[part 1 of 2: packages /MICROSAR/Dem_swc/DataTypes to /MICROSAR/Dem_swc/ComponentTypes]
AUTOSAR XML (schema 4-2-1)
package /MICROSAR/Dem_swc/DataTypes
  23 x impl type:
    Dem_EventIdType: range raw 1..65535, implementation-data-type=uint16
    Dem_RatioIdType: range raw 1..65535, implementation-data-type=uint16
    Dem_DTCStatusMaskType: range raw 0..255, implementation-data-type=uint8
    Dem_OperationCycleIdType: range raw 0..255, implementation-data-type=uint8
    Dem_DTCGroupType: range raw 0..16777215, implementation-data-type=uint32
    Dem_MaxDataValueType: category=ARRAY, sw-calibration-access=READ-ONLY
      element Dem_MaxDataValueTypeElement: array-size=2, array-size-semantics=FIXED-SIZE, implementation-data-type=uint8
    Dem_EventStatusType:
      compu {0=DEM_EVENT_STATUS_PASSED, 1=DEM_EVENT_STATUS_FAILED, 2=DEM_EVENT_STATUS_PREPASSED, 3=DEM_EVENT_STATUS_PREFAILED, 4=DEM_EVENT_STATUS_FDC_THRESHOLD_REACHED, 5=DEM_EVENT_STATUS_PASSED_CONDITIONS_NOT_FULFILLED, 6=DEM_EVENT_STATUS_FAILED_CONDITIONS_NOT_FULFILLED, 7=DEM_EVENT_STATUS_PREPASSED_CONDITIONS_NOT_FULFILLED, 8=DEM_EVENT_STATUS_PREFAILED_CONDITIONS_NOT_FULFILLED}
      range raw 0..255
      implementation-data-type=uint8
    Dem_InitMonitorReasonType: compu {1=DEM_INIT_MONITOR_CLEAR, 2=DEM_INIT_MONITOR_RESTART, 3=DEM_INIT_MONITOR_REENABLED, 4=DEM_INIT_MONITOR_STORAGE_REENABLED}, range raw 0..255, implementation-data-type=uint8
    Dem_DTCOriginType:
      compu {1=DEM_DTC_ORIGIN_PRIMARY_MEMORY, 2=DEM_DTC_ORIGIN_MIRROR_MEMORY, 3=DEM_DTC_ORIGIN_PERMANENT_MEMORY, 4=DEM_DTC_ORIGIN_OBD_RELEVANT_MEMORY, 5=DEM_DTC_ORIGIN_SECONDARY_MEMORY, 5=DEM_DTC_ORIGIN_USERDEFINED_MEMORY_10, 5=DEM_DTC_ORIGIN_USERDEFINED_MEMORY_11, 5=DEM_DTC_ORIGIN_USERDEFINED_MEMORY_12, 5=DEM_DTC_ORIGIN_USERDEFINED_MEMORY_13, 5=DEM_DTC_ORIGIN_USERDEFINED_MEMORY_14, 5=DEM_DTC_ORIGIN_USERDEFINED_MEMORY_15, 5=DEM_DTC_ORIGIN_USERDEFINED_MEMORY_16, 5=DEM_DTC_ORIGIN_USERDEFINED_MEMORY_17, 5=DEM_DTC_ORIGIN_USERDEFINED_MEMORY_18, 5=DEM_DTC_ORIGIN_USERDEFINED_MEMORY_19, 5=DEM_DTC_ORIGIN_USERDEFINED_MEMORY_1A, 5=DEM_DTC_ORIGIN_USERDEFINED_MEMORY_1B, 5=DEM_DTC_ORIGIN_USERDEFINED_MEMORY_1C, 5=DEM_DTC_ORIGIN_USERDEFINED_MEMORY_1D, 5=DEM_DTC_ORIGIN_USERDEFINED_MEMORY_1E, 5=DEM_DTC_ORIGIN_USERDEFINED_MEMORY_1F, 5=DEM_DTC_ORIGIN_USERDEFINED_MEMORY_20, 5=DEM_DTC_ORIGIN_USERDEFINED_MEMORY_21, 5=DEM_DTC_ORIGIN_USERDEFINED_MEMORY_22, 5=DEM_DTC_ORIGIN_USERDEFINED_MEMORY_23, 5=DEM_DTC_ORIGIN_USERDEFINED_MEMORY_24, 5=DEM_DTC_ORIGIN_USERDEFINED_MEMORY_25, 5=DEM_DTC_ORIGIN_USERDEFINED_MEMORY_26, 5=DEM_DTC_ORIGIN_USERDEFINED_MEMORY_27, 5=DEM_DTC_ORIGIN_USERDEFINED_MEMORY_28, 5=DEM_DTC_ORIGIN_USERDEFINED_MEMORY_29, 5=DEM_DTC_ORIGIN_USERDEFINED_MEMORY_2A, 5=DEM_DTC_ORIGIN_USERDEFINED_MEMORY_2B, 5=DEM_DTC_ORIGIN_USERDEFINED_MEMORY_2C, 5=DEM_DTC_ORIGIN_USERDEFINED_MEMORY_2D, 5=DEM_DTC_ORIGIN_USERDEFINED_MEMORY_2E, 5=DEM_DTC_ORIGIN_USERDEFINED_MEMORY_2F, 5=DEM_DTC_ORIGIN_USERDEFINED_MEMORY_30, 5=DEM_DTC_ORIGIN_USERDEFINED_MEMORY_31, 5=DEM_DTC_ORIGIN_USERDEFINED_MEMORY_32, 5=DEM_DTC_ORIGIN_USERDEFINED_MEMORY_33, 5=DEM_DTC_ORIGIN_USERDEFINED_MEMORY_34, 5=DEM_DTC_ORIGIN_USERDEFINED_MEMORY_35, 5=DEM_DTC_ORIGIN_USERDEFINED_MEMORY_36, 5=DEM_DTC_ORIGIN_USERDEFINED_MEMORY_37, 5=DEM_DTC_ORIGIN_USERDEFINED_MEMORY_38, 5=DEM_DTC_ORIGIN_USERDEFINED_MEMORY_39, 5=DEM_DTC_ORIGIN_USERDEFINED_MEMORY_3A, 5=DEM_DTC_ORIGIN_USERDEFINED_MEMORY_3B, 5=DEM_DTC_ORIGIN_USERDEFINED_MEMORY_3C, 5=DEM_DTC_ORIGIN_USERDEFINED_MEMORY_3D, 5=DEM_DTC_ORIGIN_USERDEFINED_MEMORY_3E, 5=DEM_DTC_ORIGIN_USERDEFINED_MEMORY_3F, 5=DEM_DTC_ORIGIN_USERDEFINED_MEMORY_40, 5=DEM_DTC_ORIGIN_USERDEFINED_MEMORY_41, 5=DEM_DTC_ORIGIN_USERDEFINED_MEMORY_42, 5=DEM_DTC_ORIGIN_USERDEFINED_MEMORY_43, 5=DEM_DTC_ORIGIN_USERDEFINED_MEMORY_44, 5=DEM_DTC_ORIGIN_USERDEFINED_MEMORY_45, 5=DEM_DTC_ORIGIN_USERDEFINED_MEMORY_46, 5=DEM_DTC_ORIGIN_USERDEFINED_MEMORY_47, 5=DEM_DTC_ORIGIN_USERDEFINED_MEMORY_48, 5=DEM_DTC_ORIGIN_USERDEFINED_MEMORY_49, 5=DEM_DTC_ORIGIN_USERDEFINED_MEMORY_4A, 5=DEM_DTC_ORIGIN_USERDEFINED_MEMORY_4B, 5=DEM_DTC_ORIGIN_USERDEFINED_MEMORY_4C, 5=DEM_DTC_ORIGIN_USERDEFINED_MEMORY_4D, 5=DEM_DTC_ORIGIN_USERDEFINED_MEMORY_4E, 5=DEM_DTC_ORIGIN_USERDEFINED_MEMORY_4F, 5=DEM_DTC_ORIGIN_USERDEFINED_MEMORY_50, 5=DEM_DTC_ORIGIN_USERDEFINED_MEMORY_51, 5=DEM_DTC_ORIGIN_USERDEFINED_MEMORY_52, 5=DEM_DTC_ORIGIN_USERDEFINED_MEMORY_53, 5=DEM_DTC_ORIGIN_USERDEFINED_MEMORY_54, 5=DEM_DTC_ORIGIN_USERDEFINED_MEMORY_55, 5=DEM_DTC_ORIGIN_USERDEFINED_MEMORY_56, 5=DEM_DTC_ORIGIN_USERDEFINED_MEMORY_57, 5=DEM_DTC_ORIGIN_USERDEFINED_MEMORY_58, 5=DEM_DTC_ORIGIN_USERDEFINED_MEMORY_59, 5=DEM_DTC_ORIGIN_USERDEFINED_MEMORY_5A, 5=DEM_DTC_ORIGIN_USERDEFINED_MEMORY_5B, 5=DEM_DTC_ORIGIN_USERDEFINED_MEMORY_5C, 5=DEM_DTC_ORIGIN_USERDEFINED_MEMORY_5D, 5=DEM_DTC_ORIGIN_USERDEFINED_MEMORY_5E, 5=DEM_DTC_ORIGIN_USERDEFINED_MEMORY_5F, 5=DEM_DTC_ORIGIN_USERDEFINED_MEMORY_60, 5=DEM_DTC_ORIGIN_USERDEFINED_MEMORY_61, 5=DEM_DTC_ORIGIN_USERDEFINED_MEMORY_62, 5=DEM_DTC_ORIGIN_USERDEFINED_MEMORY_63, 5=DEM_DTC_ORIGIN_USERDEFINED_MEMORY_64, 5=DEM_DTC_ORIGIN_USERDEFINED_MEMORY_65, 5=DEM_DTC_ORIGIN_USERDEFINED_MEMORY_66, 5=DEM_DTC_ORIGIN_USERDEFINED_MEMORY_67, 5=DEM_DTC_ORIGIN_USERDEFINED_MEMORY_68, 5=DEM_DTC_ORIGIN_USERDEFINED_MEMORY_69, 5=DEM_DTC_ORIGIN_USERDEFINED_MEMORY_6A, 5=DEM_DTC_ORIGIN_USERDEFINED_MEMORY_6B, 5=DEM_DTC_ORIGIN_USERDEFINED_MEMORY_6C, 5=DEM_DTC_ORIGIN_USERDEFINED_MEMORY_6D, 5=DEM_DTC_ORIGIN_USERDEFINED_MEMORY_6E, 5=DEM_DTC_ORIGIN_USERDEFINED_MEMORY_6F, 5=DEM_DTC_ORIGIN_USERDEFINED_MEMORY_70, 5=DEM_DTC_ORIGIN_USERDEFINED_MEMORY_71, 5=DEM_DTC_ORIGIN_USERDEFINED_MEMORY_72, 5=DEM_DTC_ORIGIN_USERDEFINED_MEMORY_73, 5=DEM_DTC_ORIGIN_USERDEFINED_MEMORY_74, 5=DEM_DTC_ORIGIN_USERDEFINED_MEMORY_75, 5=DEM_DTC_ORIGIN_USERDEFINED_MEMORY_76, 5=DEM_DTC_ORIGIN_USERDEFINED_MEMORY_77, 5=DEM_DTC_ORIGIN_USERDEFINED_MEMORY_78, 5=DEM_DTC_ORIGIN_USERDEFINED_MEMORY_79, 5=DEM_DTC_ORIGIN_USERDEFINED_MEMORY_7A, 5=DEM_DTC_ORIGIN_USERDEFINED_MEMORY_7B, 5=DEM_DTC_ORIGIN_USERDEFINED_MEMORY_7C, 5=DEM_DTC_ORIGIN_USERDEFINED_MEMORY_7D, 5=DEM_DTC_ORIGIN_USERDEFINED_MEMORY_7E, 5=DEM_DTC_ORIGIN_USERDEFINED_MEMORY_7F, 5=DEM_DTC_ORIGIN_USERDEFINED_MEMORY_80, 5=DEM_DTC_ORIGIN_USERDEFINED_MEMORY_81, 5=DEM_DTC_ORIGIN_USERDEFINED_MEMORY_82, 5=DEM_DTC_ORIGIN_USERDEFINED_MEMORY_83, 5=DEM_DTC_ORIGIN_USERDEFINED_MEMORY_84, 5=DEM_DTC_ORIGIN_USERDEFINED_MEMORY_85, 5=DEM_DTC_ORIGIN_USERDEFINED_MEMORY_86, 5=DEM_DTC_ORIGIN_USERDEFINED_MEMORY_87, 5=DEM_DTC_ORIGIN_USERDEFINED_MEMORY_88, 5=DEM_DTC_ORIGIN_USERDEFINED_MEMORY_89, 5=DEM_DTC_ORIGIN_USERDEFINED_MEMORY_8A, 5=DEM_DTC_ORIGIN_USERDEFINED_MEMORY_8B, 5=DEM_DTC_ORIGIN_USERDEFINED_MEMORY_8C, 5=DEM_DTC_ORIGIN_USERDEFINED_MEMORY_8D, 5=DEM_DTC_ORIGIN_USERDEFINED_MEMORY_8E, 5=DEM_DTC_ORIGIN_USERDEFINED_MEMORY_8F, 5=DEM_DTC_ORIGIN_USERDEFINED_MEMORY_90, 5=DEM_DTC_ORIGIN_USERDEFINED_MEMORY_91, 5=DEM_DTC_ORIGIN_USERDEFINED_MEMORY_92, 5=DEM_DTC_ORIGIN_USERDEFINED_MEMORY_93, 5=DEM_DTC_ORIGIN_USERDEFINED_MEMORY_94, 5=DEM_DTC_ORIGIN_USERDEFINED_MEMORY_95, 5=DEM_DTC_ORIGIN_USERDEFINED_MEMORY_96, 5=DEM_DTC_ORIGIN_USERDEFINED_MEMORY_97, 5=DEM_DTC_ORIGIN_USERDEFINED_MEMORY_98, 5=DEM_DTC_ORIGIN_USERDEFINED_MEMORY_99, 5=DEM_DTC_ORIGIN_USERDEFINED_MEMORY_9A, 5=DEM_DTC_ORIGIN_USERDEFINED_MEMORY_9B, 5=DEM_DTC_ORIGIN_USERDEFINED_MEMORY_9C, 5=DEM_DTC_ORIGIN_USERDEFINED_MEMORY_9D, 5=DEM_DTC_ORIGIN_USERDEFINED_MEMORY_9E, 5=DEM_DTC_ORIGIN_USERDEFINED_MEMORY_9F, 5=DEM_DTC_ORIGIN_USERDEFINED_MEMORY_A0, 5=DEM_DTC_ORIGIN_USERDEFINED_MEMORY_A1, 5=DEM_DTC_ORIGIN_USERDEFINED_MEMORY_A2, 5=DEM_DTC_ORIGIN_USERDEFINED_MEMORY_A3, 5=DEM_DTC_ORIGIN_USERDEFINED_MEMORY_A4, 5=DEM_DTC_ORIGIN_USERDEFINED_MEMORY_A5, 5=DEM_DTC_ORIGIN_USERDEFINED_MEMORY_A6, 5=DEM_DTC_ORIGIN_USERDEFINED_MEMORY_A7, 5=DEM_DTC_ORIGIN_USERDEFINED_MEMORY_A8, 5=DEM_DTC_ORIGIN_USERDEFINED_MEMORY_A9, 5=DEM_DTC_ORIGIN_USERDEFINED_MEMORY_AA, 5=DEM_DTC_ORIGIN_USERDEFINED_MEMORY_AB, 5=DEM_DTC_ORIGIN_USERDEFINED_MEMORY_AC, 5=DEM_DTC_ORIGIN_USERDEFINED_MEMORY_AD, 5=DEM_DTC_ORIGIN_USERDEFINED_MEMORY_AE, 5=DEM_DTC_ORIGIN_USERDEFINED_MEMORY_AF, 5=DEM_DTC_ORIGIN_USERDEFINED_MEMORY_B0, 5=DEM_DTC_ORIGIN_USERDEFINED_MEMORY_B1, 5=DEM_DTC_ORIGIN_USERDEFINED_MEMORY_B2, 5=DEM_DTC_ORIGIN_USERDEFINED_MEMORY_B3, 5=DEM_DTC_ORIGIN_USERDEFINED_MEMORY_B4, 5=DEM_DTC_ORIGIN_USERDEFINED_MEMORY_B5, 5=DEM_DTC_ORIGIN_USERDEFINED_MEMORY_B6, 5=DEM_DTC_ORIGIN_USERDEFINED_MEMORY_B7, 5=DEM_DTC_ORIGIN_USERDEFINED_MEMORY_B8, 5=DEM_DTC_ORIGIN_USERDEFINED_MEMORY_B9, 5=DEM_DTC_ORIGIN_USERDEFINED_MEMORY_BA, 5=DEM_DTC_ORIGIN_USERDEFINED_MEMORY_BB, 5=DEM_DTC_ORIGIN_USERDEFINED_MEMORY_BC, 5=DEM_DTC_ORIGIN_USERDEFINED_MEMORY_BD, 5=DEM_DTC_ORIGIN_USERDEFINED_MEMORY_BE, 5=DEM_DTC_ORIGIN_USERDEFINED_MEMORY_BF, 5=DEM_DTC_ORIGIN_USERDEFINED_MEMORY_C0, 5=DEM_DTC_ORIGIN_USERDEFINED_MEMORY_C1, 5=DEM_DTC_ORIGIN_USERDEFINED_MEMORY_C2, 5=DEM_DTC_ORIGIN_USERDEFINED_MEMORY_C3, 5=DEM_DTC_ORIGIN_USERDEFINED_MEMORY_C4, 5=DEM_DTC_ORIGIN_USERDEFINED_MEMORY_C5, 5=DEM_DTC_ORIGIN_USERDEFINED_MEMORY_C6, 5=DEM_DTC_ORIGIN_USERDEFINED_MEMORY_C7, 5=DEM_DTC_ORIGIN_USERDEFINED_MEMORY_C8, 5=DEM_DTC_ORIGIN_USERDEFINED_MEMORY_C9, 5=DEM_DTC_ORIGIN_USERDEFINED_MEMORY_CA, 5=DEM_DTC_ORIGIN_USERDEFINED_MEMORY_CB, 5=DEM_DTC_ORIGIN_USERDEFINED_MEMORY_CC, 5=DEM_DTC_ORIGIN_USERDEFINED_MEMORY_CD, 5=DEM_DTC_ORIGIN_USERDEFINED_MEMORY_CE, 5=DEM_DTC_ORIGIN_USERDEFINED_MEMORY_CF, 5=DEM_DTC_ORIGIN_USERDEFINED_MEMORY_D0, 5=DEM_DTC_ORIGIN_USERDEFINED_MEMORY_D1, 5=DEM_DTC_ORIGIN_USERDEFINED_MEMORY_D2, 5=DEM_DTC_ORIGIN_USERDEFINED_MEMORY_D3, 5=DEM_DTC_ORIGIN_USERDEFINED_MEMORY_D4, 5=DEM_DTC_ORIGIN_USERDEFINED_MEMORY_D5, 5=DEM_DTC_ORIGIN_USERDEFINED_MEMORY_D6, 5=DEM_DTC_ORIGIN_USERDEFINED_MEMORY_D7, 5=DEM_DTC_ORIGIN_USERDEFINED_MEMORY_D8, 5=DEM_DTC_ORIGIN_USERDEFINED_MEMORY_D9, 5=DEM_DTC_ORIGIN_USERDEFINED_MEMORY_DA, 5=DEM_DTC_ORIGIN_USERDEFINED_MEMORY_DB, 5=DEM_DTC_ORIGIN_USERDEFINED_MEMORY_DC, 5=DEM_DTC_ORIGIN_USERDEFINED_MEMORY_DD, 5=DEM_DTC_ORIGIN_USERDEFINED_MEMORY_DE, 5=DEM_DTC_ORIGIN_USERDEFINED_MEMORY_DF, 5=DEM_DTC_ORIGIN_USERDEFINED_MEMORY_E0, 5=DEM_DTC_ORIGIN_USERDEFINED_MEMORY_E1, 5=DEM_DTC_ORIGIN_USERDEFINED_MEMORY_E2, 5=DEM_DTC_ORIGIN_USERDEFINED_MEMORY_E3, 5=DEM_DTC_ORIGIN_USERDEFINED_MEMORY_E4, 5=DEM_DTC_ORIGIN_USERDEFINED_MEMORY_E5, 5=DEM_DTC_ORIGIN_USERDEFINED_MEMORY_E6, 5=DEM_DTC_ORIGIN_USERDEFINED_MEMORY_E7, 5=DEM_DTC_ORIGIN_USERDEFINED_MEMORY_E8, 5=DEM_DTC_ORIGIN_USERDEFINED_MEMORY_E9, 5=DEM_DTC_ORIGIN_USERDEFINED_MEMORY_EA, 5=DEM_DTC_ORIGIN_USERDEFINED_MEMORY_EB, 5=DEM_DTC_ORIGIN_USERDEFINED_MEMORY_EC, 5=DEM_DTC_ORIGIN_USERDEFINED_MEMORY_ED, 5=DEM_DTC_ORIGIN_USERDEFINED_MEMORY_EE, 5=DEM_DTC_ORIGIN_USERDEFINED_MEMORY_EF, 5=DEM_DTC_ORIGIN_USERDEFINED_MEMORY_F0, 5=DEM_DTC_ORIGIN_USERDEFINED_MEMORY_F1, 5=DEM_DTC_ORIGIN_USERDEFINED_MEMORY_F2, 5=DEM_DTC_ORIGIN_USERDEFINED_MEMORY_F3, 5=DEM_DTC_ORIGIN_USERDEFINED_MEMORY_F4, 5=DEM_DTC_ORIGIN_USERDEFINED_MEMORY_F5, 5=DEM_DTC_ORIGIN_USERDEFINED_MEMORY_F6, 5=DEM_DTC_ORIGIN_USERDEFINED_MEMORY_F7, 5=DEM_DTC_ORIGIN_USERDEFINED_MEMORY_F8, 5=DEM_DTC_ORIGIN_USERDEFINED_MEMORY_F9, 5=DEM_DTC_ORIGIN_USERDEFINED_MEMORY_FA, 5=DEM_DTC_ORIGIN_USERDEFINED_MEMORY_FB, 5=DEM_DTC_ORIGIN_USERDEFINED_MEMORY_FC, 5=DEM_DTC_ORIGIN_USERDEFINED_MEMORY_FD, 5=DEM_DTC_ORIGIN_USERDEFINED_MEMORY_FE, 5=DEM_DTC_ORIGIN_USERDEFINED_MEMORY_FF}
      range raw 0..65535
      implementation-data-type=uint16
    Dem_DTCFormatType: compu {0=DEM_DTC_FORMAT_OBD, 1=DEM_DTC_FORMAT_UDS, 2=DEM_DTC_FORMAT_J1939}, range raw 0..255, implementation-data-type=uint8
    Dem_OperationCycleStateType: compu {0=DEM_CYCLE_STATE_START, 1=DEM_CYCLE_STATE_END}, range raw 0..255, implementation-data-type=uint8
    Dem_IndicatorStatusType: compu {0=DEM_INDICATOR_OFF, 1=DEM_INDICATOR_CONTINUOUS, 2=DEM_INDICATOR_BLINKING, 3=DEM_INDICATOR_BLINK_CONT, 4=DEM_INDICATOR_SLOW_FLASH, 5=DEM_INDICATOR_FAST_FLASH, 6=DEM_INDICATOR_ON_DEMAND, 7=DEM_INDICATOR_SHORT}, range raw 0..255, implementation-data-type=uint8
    Dem_DTCKindType: compu {1=DEM_DTC_KIND_ALL_DTCS, 2=DEM_DTC_KIND_EMISSION_REL_DTCS}, range raw 0..255, implementation-data-type=uint8
    Dem_IumprDenomCondIdType: compu {1=DEM_IUMPR_GENERAL_DENOMINATOR, 2=DEM_IUMPR_DEN_COND_COLDSTART, 3=DEM_IUMPR_DEN_COND_EVAP, 4=DEM_IUMPR_DEN_COND_500MI}, range raw 0..255, implementation-data-type=uint8
    Dem_IumprDenomCondStatusType: compu {0=DEM_IUMPR_DEN_STATUS_NOT_REACHED, 1=DEM_IUMPR_DEN_STATUS_REACHED, 2=DEM_IUMPR_DEN_STATUS_INHIBITED}, range raw 0..255, implementation-data-type=uint8
    Dem_DebounceResetStatusType: compu {0=DEM_DEBOUNCE_STATUS_FREEZE, 1=DEM_DEBOUNCE_STATUS_RESET}, range raw 0..255, implementation-data-type=uint8
    Dem_DTRControlType: compu {0=DEM_DTR_CTL_NORMAL, 1=DEM_DTR_CTL_NO_MAX, 2=DEM_DTR_CTL_NO_MIN, 3=DEM_DTR_CTL_RESET, 4=DEM_DTR_CTL_INVISIBLE}, range raw 0..255, implementation-data-type=uint8
    Dem_DebouncingStateType:
      compu {mask 1: 1=DEM_TEMPORARILY_DEFECTIVE (Bit 0: Temporarily Defective (corresponds to 0 < FDC < 127)), mask 2: 2=DEM_FINALLY_DEFECTIVE (Bit 1: Finally Defective (corresponds to FDC = 127)), mask 4: 4=DEM_TEMPORARILY_HEALED (Bit 2: Temporarily healed (corresponds to -128 < FDC < 0)), mask 8: 8=DEM_TEST_COMPLETE (Bit 3: Test complete (corresponds to FDC = -128 or FDC = 127)), mask 16: 16=DEM_DTR_UPDATE (Bit 4: DTR Update (= Test complete && Debouncing complete && enable conditions / storage conditions fulfilled))}
      range raw 0..255
      implementation-data-type=uint8
    Dem_DTCSeverityType:
      compu {mask 255: 0=DEM_SEVERITY_NO_SEVERITY (DTC_NO_SEVERITY) (No severity information available), mask 31: 1=DEM_SEVERITY_WWHOBD_CLASS_NO_CLASS (DTC_CLASS) (No class information), mask 31: 2=DEM_SEVERITY_WWHOBD_CLASS_A (DTC_CLASS) (WWH-OBD Class A), mask 31: 4=DEM_SEVERITY_WWHOBD_CLASS_B1 (DTC_CLASS) (WWH-OBD Class B1), mask 31: 8=DEM_SEVERITY_WWHOBD_CLASS_B2 (DTC_CLASS) (WWH-OBD Class B2), mask 31: 16=DEM_SEVERITY_WWHOBD_CLASS_C (DTC_CLASS) (WWH-OBD Class C), mask 224: 32=DEM_SEVERITY_MAINTENANCE_ONLY (DTC_SEVERITY) (Maintenance required), mask 224: 64=DEM_SEVERITY_CHECK_AT_NEXT_HALT (DTC_SEVERITY) (Check at next halt), mask 224: 128=DEM_SEVERITY_CHECK_IMMEDIATELY (DTC_SEVERITY) (Check immediately)}
      range raw 0..255
      implementation-data-type=uint8
    Dem_UdsStatusByteType:
      compu {mask 1: 1=DEM_UDS_STATUS_TF (bit 0: TestFailed), mask 2: 2=DEM_UDS_STATUS_TFTOC (bit 1: TestFailedThisOperationCycle), mask 4: 4=DEM_UDS_STATUS_PDTC (bit 2: PendingDTC), mask 8: 8=DEM_UDS_STATUS_CDTC (bit 3: ConfirmedDTC), mask 16: 16=DEM_UDS_STATUS_TNCSLC (bit 4: TestNotCompletedSinceLastClear), mask 32: 32=DEM_UDS_STATUS_TFSLC (bit 5: TestFailedSinceLastClear), mask 64: 64=DEM_UDS_STATUS_TNCTOC (bit 6: TestNotCompletedThisOperationCycle), mask 128: 128=DEM_UDS_STATUS_WIR (bit 7: WarningIndicatorRequested)}
      range raw 0..255
      implementation-data-type=uint8
    Dem_MonitorStatusType: compu {mask 1: 1=DEM_MONITOR_STATUS_TF (bit 0: TestFailed), mask 2: 2=DEM_MONITOR_STATUS_TNCTOC (bit 1: TestNotCompletedThisOperationCycle)}, range raw 0..255, implementation-data-type=uint8
    DataArrayType_uint8_2: category=ARRAY, sw-calibration-access=READ-ONLY
      element DataArrayType_uint8_2Element: array-size=2, array-size-semantics=FIXED-SIZE, implementation-data-type=uint8
    Dem_IumprReadinessGroupType:
      compu {0=DEM_IUMPR_BOOSTPRS, 1=DEM_IUMPR_CAT1, 2=DEM_IUMPR_CAT2, 3=DEM_IUMPR_EGR, 4=DEM_IUMPR_EGSENSOR, 5=DEM_IUMPR_EVAP, 6=DEM_IUMPR_NMHCCAT, 7=DEM_IUMPR_NOXADSORB, 8=DEM_IUMPR_NOXCAT, 9=DEM_IUMPR_OXS1, 10=DEM_IUMPR_OXS2, 11=DEM_IUMPR_PMFILTER, 12=DEM_IUMPR_PRIVATE, 13=DEM_IUMPR_SAIR, 14=DEM_IUMPR_SECOXS1, 15=DEM_IUMPR_SECOXS2, 16=DEM_IUMPR_FLSYS, 17=DEM_IUMPR_AFRI1, 18=DEM_IUMPR_AFRI2, 19=DEM_IUMPR_PF1, 20=DEM_IUMPR_PF2, 255=DEM_IUMPR_ALLGROUPS}
      range raw 0..255
      implementation-data-type=uint8
package /MICROSAR/Dem_swc/Interfaces
  10 x client server interface, all with is-service=true, service-kind=DIAGNOSTIC-EVENT-MANAGER:
    DemServices
      operation GetPostRunRequested: possible-error=DemServices/E_NOT_OK
        arg IsRequested: type=boolean, direction=OUT
      operation GetDTCStatusAvailabilityMask: possible-error=DemServices/E_NOT_OK
        arg ClientId: type=uint8, direction=IN
        arg DTCStatusMask: type=uint8, direction=OUT
      error E_NOT_OK: error-code=1
    ClearDTC
      operation ClearDTC: possible-error=[ClearDTC/E_NOT_OK, DEM_CLEAR_FAILED, DEM_PENDING, DEM_CLEAR_BUSY, DEM_CLEAR_MEMORY_ERROR, DEM_WRONG_DTC, DEM_WRONG_DTCORIGIN]
      operation SelectDTC: possible-error=[ClearDTC/E_OK, ClearDTC/E_NOT_OK]
        arg DTC: type=uint32, direction=IN
        arg DTCFormat: type=Dem_DTCFormatType, direction=IN
        arg DTCOrigin: type=Dem_DTCOriginType, direction=IN
      8 x error:
        E_OK: error-code=0
        E_NOT_OK: error-code=1
        DEM_CLEAR_FAILED: error-code=7
        DEM_PENDING: error-code=4
        DEM_CLEAR_BUSY: error-code=5
        DEM_CLEAR_MEMORY_ERROR: error-code=6
        DEM_WRONG_DTC: error-code=8
        DEM_WRONG_DTCORIGIN: error-code=9
    EnableCondition
      operation SetEnableCondition: possible-error=EnableCondition/E_NOT_OK
        arg ConditionFulfilled: type=boolean, direction=IN
      error E_NOT_OK: error-code=1
    EvMemOverflowIndication
      operation GetEventMemoryOverflow: possible-error=EvMemOverflowIndication/E_NOT_OK
        arg OverflowIndication: type=boolean, direction=OUT
      operation GetNumberOfEventMemoryEntries: possible-error=EvMemOverflowIndication/E_NOT_OK
        arg NumberOfEventMemoryEntries: type=uint8, direction=OUT
      error E_NOT_OK: error-code=1
    GeneralDiagnosticInfo
      11 x operation:
        GetEventUdsStatus: possible-error=GeneralDiagnosticInfo/E_NOT_OK
          arg EventId: type=Dem_EventIdType, direction=IN
          arg UDSStatusByte: type=Dem_UdsStatusByteType, direction=OUT
        GetEventStatus: possible-error=GeneralDiagnosticInfo/E_NOT_OK
          arg EventId: type=Dem_EventIdType, direction=IN
          arg UDSStatusByte: type=Dem_UdsStatusByteType, direction=OUT
        GetEventFailed: possible-error=GeneralDiagnosticInfo/E_NOT_OK
          arg EventId: type=Dem_EventIdType, direction=IN
          arg EventFailed: type=boolean, direction=OUT
        GetEventTested: possible-error=GeneralDiagnosticInfo/E_NOT_OK
          arg EventId: type=Dem_EventIdType, direction=IN
          arg EventTested: type=boolean, direction=OUT
        GetDTCOfEvent: possible-error=[GeneralDiagnosticInfo/E_NOT_OK, GeneralDiagnosticInfo/DEM_E_NO_DTC_AVAILABLE]
          arg EventId: type=Dem_EventIdType, direction=IN
          arg DTCFormat: type=Dem_DTCFormatType, direction=IN
          arg DTCOfEvent: type=uint32, direction=OUT
        GetFaultDetectionCounter: possible-error=[GeneralDiagnosticInfo/E_NOT_OK, GeneralDiagnosticInfo/DEM_E_NO_FDC_AVAILABLE]
          arg EventId: type=Dem_EventIdType, direction=IN
          arg FaultDetectionCounter: type=sint8, direction=OUT
        GetEventFreezeFrameDataEx: possible-error=[GeneralDiagnosticInfo/E_NOT_OK, GeneralDiagnosticInfo/DEM_BUFFER_TOO_SMALL, GeneralDiagnosticInfo/DEM_NO_SUCH_ELEMENT]
          5 x arg:
            EventId: type=Dem_EventIdType, direction=IN
            RecordNumber: type=uint8, direction=IN
            DataId: type=uint16, direction=IN
            DestBuffer: type=Dem_MaxDataValueType, direction=OUT
            BufSize: type=uint16, direction=INOUT
        GetEventExtendedDataRecordEx: possible-error=[GeneralDiagnosticInfo/E_NOT_OK, GeneralDiagnosticInfo/DEM_BUFFER_TOO_SMALL, GeneralDiagnosticInfo/DEM_NO_SUCH_ELEMENT]
          4 x arg:
            EventId: type=Dem_EventIdType, direction=IN
            RecordNumber: type=uint8, direction=IN
            DestBuffer: type=Dem_MaxDataValueType, direction=OUT
            BufSize: type=uint16, direction=INOUT
        GetEventEnableCondition: possible-error=GeneralDiagnosticInfo/E_NOT_OK
          arg EventId: type=Dem_EventIdType, direction=IN
          arg ConditionFullfilled: type=boolean, direction=OUT
        GetDebouncingOfEvent: possible-error=GeneralDiagnosticInfo/E_NOT_OK
          arg EventId: type=Dem_EventIdType, direction=IN
          arg DebouncingState: type=Dem_DebouncingStateType, direction=OUT
        GetMonitorStatus: possible-error=GeneralDiagnosticInfo/E_NOT_OK
          arg EventId: type=Dem_EventIdType, direction=IN
          arg MonitorStatus: type=Dem_MonitorStatusType, direction=OUT
      5 x error:
        E_NOT_OK: error-code=1
        DEM_E_NO_DTC_AVAILABLE: error-code=10
        DEM_E_NO_FDC_AVAILABLE: error-code=14
        DEM_BUFFER_TOO_SMALL: error-code=21
        DEM_NO_SUCH_ELEMENT: error-code=48
    OperationCycle
      operation GetOperationCycleState: possible-error=[OperationCycle/E_OK, OperationCycle/E_NOT_OK]
        arg CycleState: type=Dem_OperationCycleStateType, direction=OUT
      operation SetOperationCycleState: possible-error=[OperationCycle/E_OK, OperationCycle/E_NOT_OK]
        arg CycleState: type=Dem_OperationCycleStateType, direction=IN
      error E_OK: error-code=0
      error E_NOT_OK: error-code=1
    CSDataServices_PID_0x14_DID_Data
      operation ReadData: possible-error=CSDataServices_PID_0x14_DID_Data/E_NOT_OK
        arg Data: type=DataArrayType_uint8_2, direction=OUT
      error E_NOT_OK: error-code=1
    DiagnosticInfo
      11 x operation:
        GetEventUdsStatus: possible-error=DiagnosticInfo/E_NOT_OK
          arg UDSStatusByte: type=Dem_UdsStatusByteType, direction=OUT
        GetEventStatus: possible-error=DiagnosticInfo/E_NOT_OK
          arg UDSStatusByte: type=Dem_UdsStatusByteType, direction=OUT
        GetEventFailed: possible-error=DiagnosticInfo/E_NOT_OK
          arg EventFailed: type=boolean, direction=OUT
        GetEventTested: possible-error=DiagnosticInfo/E_NOT_OK
          arg EventTested: type=boolean, direction=OUT
        GetDTCOfEvent: possible-error=[DiagnosticInfo/E_NOT_OK, DiagnosticInfo/DEM_E_NO_DTC_AVAILABLE]
          arg DTCFormat: type=Dem_DTCFormatType, direction=IN
          arg DTCOfEvent: type=uint32, direction=OUT
        GetFaultDetectionCounter: possible-error=[DiagnosticInfo/E_NOT_OK, DiagnosticInfo/DEM_E_NO_FDC_AVAILABLE]
          arg FaultDetectionCounter: type=sint8, direction=OUT
        GetEventFreezeFrameDataEx: possible-error=[DiagnosticInfo/E_NOT_OK, DiagnosticInfo/DEM_BUFFER_TOO_SMALL, DiagnosticInfo/DEM_NO_SUCH_ELEMENT]
          4 x arg:
            RecordNumber: type=uint8, direction=IN
            DataId: type=uint16, direction=IN
            DestBuffer: type=Dem_MaxDataValueType, direction=OUT
            BufSize: type=uint16, direction=INOUT
        GetEventExtendedDataRecordEx: possible-error=[DiagnosticInfo/E_NOT_OK, DiagnosticInfo/DEM_BUFFER_TOO_SMALL, DiagnosticInfo/DEM_NO_SUCH_ELEMENT]
          arg RecordNumber: type=uint8, direction=IN
          arg DestBuffer: type=Dem_MaxDataValueType, direction=OUT
          arg BufSize: type=uint16, direction=INOUT
        GetEventEnableCondition: possible-error=DiagnosticInfo/E_NOT_OK
          arg ConditionFullfilled: type=boolean, direction=OUT
        GetDebouncingOfEvent: possible-error=DiagnosticInfo/E_NOT_OK
          arg DebouncingState: type=Dem_DebouncingStateType, direction=OUT
        GetMonitorStatus: possible-error=DiagnosticInfo/E_NOT_OK
          arg MonitorStatus: type=Dem_MonitorStatusType, direction=OUT
      5 x error:
        E_NOT_OK: error-code=1
        DEM_E_NO_DTC_AVAILABLE: error-code=10
        DEM_E_NO_FDC_AVAILABLE: error-code=14
        DEM_BUFFER_TOO_SMALL: error-code=21
        DEM_NO_SUCH_ELEMENT: error-code=48
    DiagnosticMonitor
      11 x operation:
        SetEventStatus: possible-error=DiagnosticMonitor/E_NOT_OK
          arg EventStatus: type=Dem_EventStatusType, direction=IN
        ResetEventStatus: possible-error=DiagnosticMonitor/E_NOT_OK
        ResetEventDebounceStatus: possible-error=DiagnosticMonitor/E_NOT_OK
          arg DebounceResetStatus: type=Dem_DebounceResetStatusType, direction=IN
        GetEventUdsStatus: possible-error=DiagnosticMonitor/E_NOT_OK
          arg UDSStatusByte: type=Dem_UdsStatusByteType, direction=OUT
        GetEventStatus: possible-error=DiagnosticMonitor/E_NOT_OK
          arg UDSStatusByte: type=Dem_UdsStatusByteType, direction=OUT
        GetEventFailed: possible-error=DiagnosticMonitor/E_NOT_OK
          arg EventFailed: type=boolean, direction=OUT
        GetEventTested: possible-error=DiagnosticMonitor/E_NOT_OK
          arg EventTested: type=boolean, direction=OUT
        GetDTCOfEvent: possible-error=[DiagnosticMonitor/E_NOT_OK, DiagnosticMonitor/DEM_E_NO_DTC_AVAILABLE]
          arg DTCFormat: type=Dem_DTCFormatType, direction=IN
          arg DTCOfEvent: type=uint32, direction=OUT
        GetFaultDetectionCounter: possible-error=[DiagnosticMonitor/E_NOT_OK, DiagnosticMonitor/DEM_E_NO_FDC_AVAILABLE]
          arg FaultDetectionCounter: type=sint8, direction=OUT
        GetEventFreezeFrameDataEx: possible-error=[DiagnosticMonitor/E_NOT_OK, DiagnosticMonitor/DEM_BUFFER_TOO_SMALL, DiagnosticMonitor/DEM_NO_SUCH_ELEMENT]
          4 x arg:
            RecordNumber: type=uint8, direction=IN
            DataId: type=uint16, direction=IN
            DestBuffer: type=Dem_MaxDataValueType, direction=OUT
            BufSize: type=uint16, direction=INOUT
        GetEventExtendedDataRecordEx: possible-error=[DiagnosticMonitor/E_NOT_OK, DiagnosticMonitor/DEM_BUFFER_TOO_SMALL, DiagnosticMonitor/DEM_NO_SUCH_ELEMENT]
          arg RecordNumber: type=uint8, direction=IN
          arg DestBuffer: type=Dem_MaxDataValueType, direction=OUT
          arg BufSize: type=uint16, direction=INOUT
      5 x error:
        E_NOT_OK: error-code=1
        DEM_E_NO_DTC_AVAILABLE: error-code=10
        DEM_E_NO_FDC_AVAILABLE: error-code=14
        DEM_BUFFER_TOO_SMALL: error-code=21
        DEM_NO_SUCH_ELEMENT: error-code=48
    CSDataServices_DemDataElementClass_StartApplication
      operation ReadData: possible-error=CSDataServices_DemDataElementClass_StartApplication/E_NOT_OK
        arg Data: type=DataArrayType_uint8_2, direction=OUT
      error E_NOT_OK: error-code=1
package /MICROSAR/Dem_swc/ComponentTypes
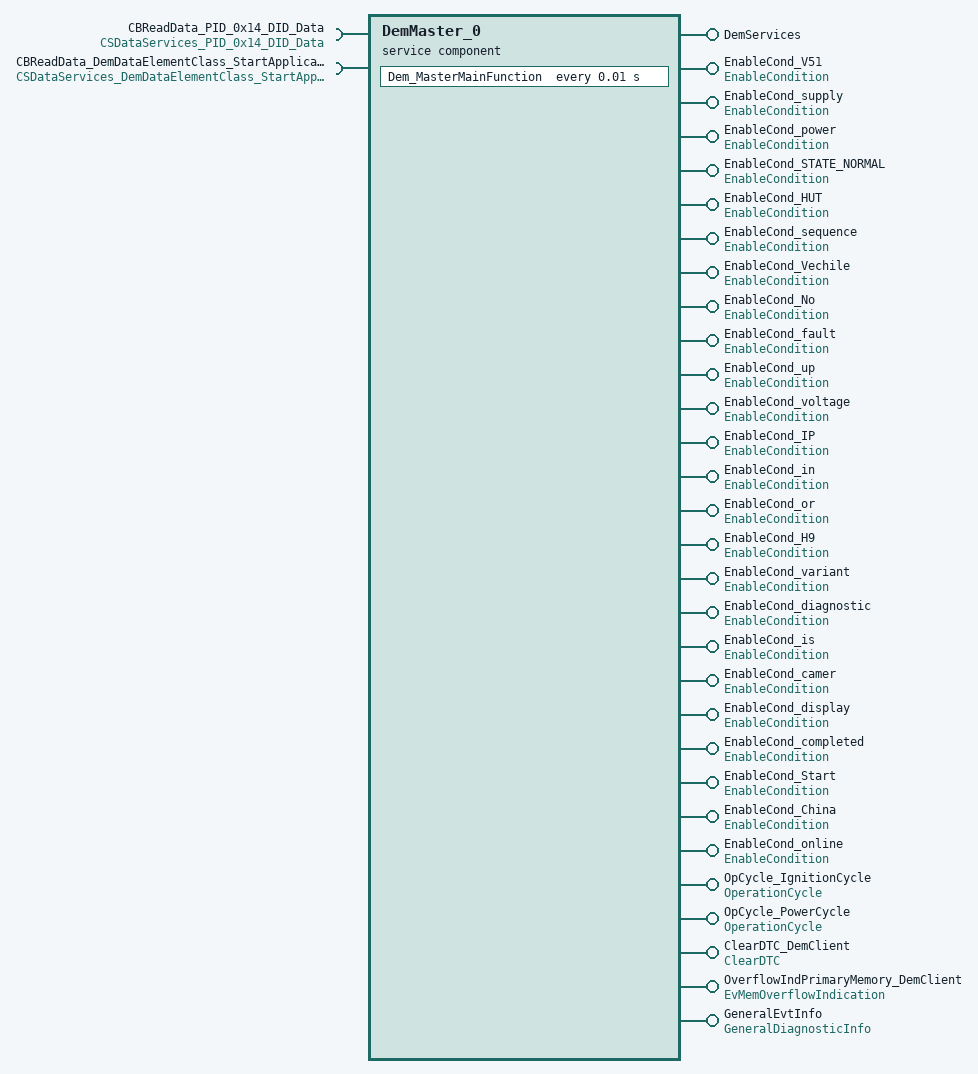
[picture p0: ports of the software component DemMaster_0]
  service sw component type DemMaster_0: category=SERVICE_COMPONENT
    27 x provide port:
      DemServices: provided-interface=DemServices
      EnableCond_V51: provided-interface=EnableCondition
      EnableCond_supply: provided-interface=EnableCondition
      EnableCond_power: provided-interface=EnableCondition
      EnableCond_STATE_NORMAL: provided-interface=EnableCondition
      EnableCond_HUT: provided-interface=EnableCondition
      EnableCond_sequence: provided-interface=EnableCondition
      EnableCond_Vechile: provided-interface=EnableCondition
      EnableCond_No: provided-interface=EnableCondition
      EnableCond_fault: provided-interface=EnableCondition
      EnableCond_up: provided-interface=EnableCondition
      EnableCond_voltage: provided-interface=EnableCondition
      EnableCond_IP: provided-interface=EnableCondition
      EnableCond_in: provided-interface=EnableCondition
      EnableCond_or: provided-interface=EnableCondition
      EnableCond_H9: provided-interface=EnableCondition
      EnableCond_variant: provided-interface=EnableCondition
      EnableCond_diagnostic: provided-interface=EnableCondition
      EnableCond_is: provided-interface=EnableCondition
      EnableCond_camer: provided-interface=EnableCondition
      EnableCond_display: provided-interface=EnableCondition
      EnableCond_completed: provided-interface=EnableCondition
      EnableCond_Start: provided-interface=EnableCondition
      EnableCond_China: provided-interface=EnableCondition
      EnableCond_online: provided-interface=EnableCondition
      OpCycle_IgnitionCycle: provided-interface=OperationCycle
      OpCycle_PowerCycle: provided-interface=OperationCycle
    require port CBReadData_PID_0x14_DID_Data: required-interface=CSDataServices_PID_0x14_DID_Data
    provide port ClearDTC_DemClient: provided-interface=ClearDTC
    provide port OverflowIndPrimaryMemory_DemClient: provided-interface=EvMemOverflowIndication
    require port CBReadData_DemDataElementClass_StartApplication: required-interface=CSDataServices_DemDataElementClass_StartApplication
    provide port GeneralEvtInfo: provided-interface=GeneralDiagnosticInfo
    behavior DemMaster_0InternalBehavior: handle-termination-and-restart=NO-SUPPORT, included-data-type-set=data-type=[Dem_EventIdType, Dem_RatioIdType, Dem_EventStatusType, Dem_UdsStatusByteType, Dem_DTCFormatType, Dem_InitMonitorReasonType, Dem_OperationCycleStateType, Dem_DTCStatusMaskType, Dem_IndicatorStatusType, Dem_MaxDataValueType, Dem_DTCKindType, Dem_DTCGroupType, Dem_IumprDenomCondIdType, Dem_IumprDenomCondStatusType, Dem_DebounceResetStatusType, Dem_DebouncingStateType, Dem_IumprReadinessGroupType, Dem_DTRControlType, Dem_DTCSeverityType, Dem_MonitorStatusType]
      timing event Timer_Dem_MasterMainFunction: start-on-event=Dem_MasterMainFunction, period=0.01
      45 x operation invoked event:
        OpEventPostRunRequested_GetPostRunRequested_DemServices: start-on-event=PostRunRequested, operation=DemServices.GetPostRunRequested
        OpEventGetDTCStatusAvailabilityMask_GetDTCStatusAvailabilityMask_DemServices: start-on-event=GetDTCStatusAvailabilityMask, operation=DemServices.GetDTCStatusAvailabilityMask
        OpEventSetEnableCondition_SetEnableCondition_EnableCond_V51: start-on-event=SetEnableCondition, operation=EnableCond_V51.SetEnableCondition
        OpEventSetEnableCondition_SetEnableCondition_EnableCond_supply: start-on-event=SetEnableCondition, operation=EnableCond_supply.SetEnableCondition
        OpEventSetEnableCondition_SetEnableCondition_EnableCond_power: start-on-event=SetEnableCondition, operation=EnableCond_power.SetEnableCondition
        OpEventSetEnableCondition_SetEnableCondition_EnableCond_STATE_NORMAL: start-on-event=SetEnableCondition, operation=EnableCond_STATE_NORMAL.SetEnableCondition
        OpEventSetEnableCondition_SetEnableCondition_EnableCond_HUT: start-on-event=SetEnableCondition, operation=EnableCond_HUT.SetEnableCondition
        OpEventSetEnableCondition_SetEnableCondition_EnableCond_sequence: start-on-event=SetEnableCondition, operation=EnableCond_sequence.SetEnableCondition
        OpEventSetEnableCondition_SetEnableCondition_EnableCond_Vechile: start-on-event=SetEnableCondition, operation=EnableCond_Vechile.SetEnableCondition
        OpEventSetEnableCondition_SetEnableCondition_EnableCond_No: start-on-event=SetEnableCondition, operation=EnableCond_No.SetEnableCondition
        OpEventSetEnableCondition_SetEnableCondition_EnableCond_fault: start-on-event=SetEnableCondition, operation=EnableCond_fault.SetEnableCondition
        OpEventSetEnableCondition_SetEnableCondition_EnableCond_up: start-on-event=SetEnableCondition, operation=EnableCond_up.SetEnableCondition
        OpEventSetEnableCondition_SetEnableCondition_EnableCond_voltage: start-on-event=SetEnableCondition, operation=EnableCond_voltage.SetEnableCondition
        OpEventSetEnableCondition_SetEnableCondition_EnableCond_IP: start-on-event=SetEnableCondition, operation=EnableCond_IP.SetEnableCondition
        OpEventSetEnableCondition_SetEnableCondition_EnableCond_in: start-on-event=SetEnableCondition, operation=EnableCond_in.SetEnableCondition
        OpEventSetEnableCondition_SetEnableCondition_EnableCond_or: start-on-event=SetEnableCondition, operation=EnableCond_or.SetEnableCondition
        OpEventSetEnableCondition_SetEnableCondition_EnableCond_H9: start-on-event=SetEnableCondition, operation=EnableCond_H9.SetEnableCondition
        OpEventSetEnableCondition_SetEnableCondition_EnableCond_variant: start-on-event=SetEnableCondition, operation=EnableCond_variant.SetEnableCondition
        OpEventSetEnableCondition_SetEnableCondition_EnableCond_diagnostic: start-on-event=SetEnableCondition, operation=EnableCond_diagnostic.SetEnableCondition
        OpEventSetEnableCondition_SetEnableCondition_EnableCond_is: start-on-event=SetEnableCondition, operation=EnableCond_is.SetEnableCondition
        OpEventSetEnableCondition_SetEnableCondition_EnableCond_camer: start-on-event=SetEnableCondition, operation=EnableCond_camer.SetEnableCondition
        OpEventSetEnableCondition_SetEnableCondition_EnableCond_display: start-on-event=SetEnableCondition, operation=EnableCond_display.SetEnableCondition
        OpEventSetEnableCondition_SetEnableCondition_EnableCond_completed: start-on-event=SetEnableCondition, operation=EnableCond_completed.SetEnableCondition
        OpEventSetEnableCondition_SetEnableCondition_EnableCond_Start: start-on-event=SetEnableCondition, operation=EnableCond_Start.SetEnableCondition
        OpEventSetEnableCondition_SetEnableCondition_EnableCond_China: start-on-event=SetEnableCondition, operation=EnableCond_China.SetEnableCondition
        OpEventSetEnableCondition_SetEnableCondition_EnableCond_online: start-on-event=SetEnableCondition, operation=EnableCond_online.SetEnableCondition
        OpEventGetOperationCycleState_GetOperationCycleState_OpCycle_IgnitionCycle: start-on-event=GetOperationCycleState, operation=OpCycle_IgnitionCycle.GetOperationCycleState
        OpEventGetOperationCycleState_GetOperationCycleState_OpCycle_PowerCycle: start-on-event=GetOperationCycleState, operation=OpCycle_PowerCycle.GetOperationCycleState
        OpEventSetOperationCycleState_SetOperationCycleState_OpCycle_IgnitionCycle: start-on-event=SetOperationCycleState, operation=OpCycle_IgnitionCycle.SetOperationCycleState
        OpEventSetOperationCycleState_SetOperationCycleState_OpCycle_PowerCycle: start-on-event=SetOperationCycleState, operation=OpCycle_PowerCycle.SetOperationCycleState
        OpEventClearDTC_ClearDTC_ClearDTC_DemClient: start-on-event=ClearDTC, operation=ClearDTC_DemClient.ClearDTC
        OpEventSelectDTC_SelectDTC_ClearDTC_DemClient: start-on-event=SelectDTC, operation=ClearDTC_DemClient.SelectDTC
        OpEventGetEventMemoryOverflow_GetEventMemoryOverflow_OverflowIndPrimaryMemory_DemClient: start-on-event=GetEventMemoryOverflow, operation=OverflowIndPrimaryMemory_DemClient.GetEventMemoryOverflow
        OpEventGetNumberOfEventMemoryEntries_GetNumberOfEventMemoryEntries_OverflowIndPrimaryMemory_DemClient: start-on-event=GetNumberOfEventMemoryEntries, operation=OverflowIndPrimaryMemory_DemClient.GetNumberOfEventMemoryEntries
        OpEventGetEventUdsStatus_GetEventUdsStatus_GeneralEvtInfo: start-on-event=DemMaster_0InternalBehavior/GetEventUdsStatus, operation=GeneralEvtInfo.GetEventUdsStatus
        OpEventGetEventStatus_GetEventStatus_GeneralEvtInfo: start-on-event=DemMaster_0InternalBehavior/GetEventStatus, operation=GeneralEvtInfo.GetEventStatus
        OpEventGetEventFailed_GetEventFailed_GeneralEvtInfo: start-on-event=DemMaster_0InternalBehavior/GetEventFailed, operation=GeneralEvtInfo.GetEventFailed
        OpEventGetEventTested_GetEventTested_GeneralEvtInfo: start-on-event=DemMaster_0InternalBehavior/GetEventTested, operation=GeneralEvtInfo.GetEventTested
        OpEventGetDTCOfEvent_GetDTCOfEvent_GeneralEvtInfo: start-on-event=DemMaster_0InternalBehavior/GetDTCOfEvent, operation=GeneralEvtInfo.GetDTCOfEvent
        OpEventGetFaultDetectionCounter_GetFaultDetectionCounter_GeneralEvtInfo: start-on-event=DemMaster_0InternalBehavior/GetFaultDetectionCounter, operation=GeneralEvtInfo.GetFaultDetectionCounter
        OpEventGetEventFreezeFrameDataEx_GetEventFreezeFrameDataEx_GeneralEvtInfo: start-on-event=DemMaster_0InternalBehavior/GetEventFreezeFrameDataEx, operation=GeneralEvtInfo.GetEventFreezeFrameDataEx
        OpEventGetEventExtendedDataRecordEx_GetEventExtendedDataRecordEx_GeneralEvtInfo: start-on-event=DemMaster_0InternalBehavior/GetEventExtendedDataRecordEx, operation=GeneralEvtInfo.GetEventExtendedDataRecordEx
        OpEventGetEventEnableCondition_GetEventEnableCondition_GeneralEvtInfo: start-on-event=DemMaster_0InternalBehavior/GetEventEnableCondition, operation=GeneralEvtInfo.GetEventEnableCondition
        OpEventGetDebouncingOfEvent_GetDebouncingOfEvent_GeneralEvtInfo: start-on-event=DemMaster_0InternalBehavior/GetDebouncingOfEvent, operation=GeneralEvtInfo.GetDebouncingOfEvent
        OpEventGetMonitorStatus_GetMonitorStatus_GeneralEvtInfo: start-on-event=DemMaster_0InternalBehavior/GetMonitorStatus, operation=GeneralEvtInfo.GetMonitorStatus
      port-api-options:
        enable-take-address=true, indirect-api=false, port=DemServices
        {enable-take-address=true, indirect-api=false, port-defined-argument-value{value=0, value-type=Dem_OperationCycleIdType}, port=OpCycle_IgnitionCycle}
        {enable-take-address=true, indirect-api=false, port-defined-argument-value{value=1, value-type=Dem_OperationCycleIdType}, port=OpCycle_PowerCycle}
        enable-take-address=true, indirect-api=false, port=DemMaster_0/CBReadData_PID_0x14_DID_Data
        {enable-take-address=true, indirect-api=false, port-defined-argument-value{value=8, value-type=uint8}, port=EnableCond_V51}
        {enable-take-address=true, indirect-api=false, port-defined-argument-value{value=21, value-type=uint8}, port=EnableCond_supply}
        {enable-take-address=true, indirect-api=false, port-defined-argument-value{value=19, value-type=uint8}, port=EnableCond_power}
        {enable-take-address=true, indirect-api=false, port-defined-argument-value{value=6, value-type=uint8}, port=EnableCond_STATE_NORMAL}
        {enable-take-address=true, indirect-api=false, port-defined-argument-value{value=3, value-type=uint8}, port=EnableCond_HUT}
        {enable-take-address=true, indirect-api=false, port-defined-argument-value{value=20, value-type=uint8}, port=EnableCond_sequence}
        {enable-take-address=true, indirect-api=false, port-defined-argument-value{value=9, value-type=uint8}, port=EnableCond_Vechile}
        {enable-take-address=true, indirect-api=false, port-defined-argument-value{value=5, value-type=uint8}, port=EnableCond_No}
        {enable-take-address=true, indirect-api=false, port-defined-argument-value{value=14, value-type=uint8}, port=EnableCond_fault}
        {enable-take-address=true, indirect-api=false, port-defined-argument-value{value=22, value-type=uint8}, port=EnableCond_up}
        {enable-take-address=true, indirect-api=false, port-defined-argument-value{value=24, value-type=uint8}, port=EnableCond_voltage}
        {enable-take-address=true, indirect-api=false, port-defined-argument-value{value=4, value-type=uint8}, port=EnableCond_IP}
        {enable-take-address=true, indirect-api=false, port-defined-argument-value{value=15, value-type=uint8}, port=EnableCond_in}
        {enable-take-address=true, indirect-api=false, port-defined-argument-value{value=18, value-type=uint8}, port=EnableCond_or}
        {enable-take-address=true, indirect-api=false, port-defined-argument-value{value=2, value-type=uint8}, port=EnableCond_H9}
        {enable-take-address=true, indirect-api=false, port-defined-argument-value{value=23, value-type=uint8}, port=EnableCond_variant}
        {enable-take-address=true, indirect-api=false, port-defined-argument-value{value=12, value-type=uint8}, port=EnableCond_diagnostic}
        {enable-take-address=true, indirect-api=false, port-defined-argument-value{value=16, value-type=uint8}, port=EnableCond_is}
        {enable-take-address=true, indirect-api=false, port-defined-argument-value{value=10, value-type=uint8}, port=EnableCond_camer}
        {enable-take-address=true, indirect-api=false, port-defined-argument-value{value=13, value-type=uint8}, port=EnableCond_display}
        {enable-take-address=true, indirect-api=false, port-defined-argument-value{value=11, value-type=uint8}, port=EnableCond_completed}
        {enable-take-address=true, indirect-api=false, port-defined-argument-value{value=7, value-type=uint8}, port=EnableCond_Start}
        {enable-take-address=true, indirect-api=false, port-defined-argument-value{value=1, value-type=uint8}, port=EnableCond_China}
        {enable-take-address=true, indirect-api=false, port-defined-argument-value{value=17, value-type=uint8}, port=EnableCond_online}
        {enable-take-address=true, indirect-api=false, port-defined-argument-value{value=0, value-type=uint8}, port=ClearDTC_DemClient}
        {enable-take-address=true, indirect-api=false, port-arg-values=[{value=0, value-type=uint8}, {value=1, value-type=Dem_DTCOriginType}], port=OverflowIndPrimaryMemory_DemClient}
        enable-take-address=true, indirect-api=false, port=DemMaster_0/CBReadData_DemDataElementClass_StartApplication
        enable-take-address=true, indirect-api=false, port=DemMaster_0/GeneralEvtInfo
      21 x runnable:
        Dem_MasterMainFunction
          sync call OpServerCallDem_MasterMainFunction_ReadData_CBReadData_PID_0x14_DID_Data: operation=CBReadData_PID_0x14_DID_Data.ReadData, timeout=0
          sync call OpServerCallDem_MasterMainFunction_ReadData_CBReadData_DemDataElementClass_StartApplication: operation=CBReadData_DemDataElementClass_StartApplication.ReadData, timeout=0
        PostRunRequested: can-be-invoked-concurrently=true, symbol=Dem_PostRunRequested
        GetDTCStatusAvailabilityMask: can-be-invoked-concurrently=true, symbol=Dem_GetDTCStatusAvailabilityMask
        SetEnableCondition: can-be-invoked-concurrently=true, symbol=Dem_SetEnableCondition
        GetEventUdsStatus: can-be-invoked-concurrently=true, symbol=Dem_GetEventUdsStatus
        GetEventStatus: can-be-invoked-concurrently=true, symbol=Dem_GetEventUdsStatus
        GetEventFailed: can-be-invoked-concurrently=true, symbol=Dem_GetEventFailed
        GetEventTested: can-be-invoked-concurrently=true, symbol=Dem_GetEventTested
        GetDTCOfEvent: can-be-invoked-concurrently=true, symbol=Dem_GetDTCOfEvent
        GetFaultDetectionCounter: can-be-invoked-concurrently=true, symbol=Dem_GetFaultDetectionCounter
        GetEventFreezeFrameDataEx: can-be-invoked-concurrently=true, symbol=Dem_GetEventFreezeFrameDataEx
        GetEventExtendedDataRecordEx: can-be-invoked-concurrently=true, symbol=Dem_GetEventExtendedDataRecordEx
        GetEventEnableCondition: can-be-invoked-concurrently=true, symbol=Dem_GetEventEnableCondition
        GetDebouncingOfEvent: can-be-invoked-concurrently=true, symbol=Dem_GetDebouncingOfEvent
        GetMonitorStatus: can-be-invoked-concurrently=true, symbol=Dem_GetMonitorStatus
        GetOperationCycleState: can-be-invoked-concurrently=true, symbol=Dem_GetOperationCycleState
        SetOperationCycleState: can-be-invoked-concurrently=true, symbol=Dem_SetOperationCycleState
        ClearDTC: can-be-invoked-concurrently=true, symbol=Dem_ClearDTC
        SelectDTC: can-be-invoked-concurrently=true, symbol=Dem_SelectDTC
        GetEventMemoryOverflow: can-be-invoked-concurrently=true, symbol=Dem_GetEventMemoryOverflow
        GetNumberOfEventMemoryEntries: can-be-invoked-concurrently=true, symbol=Dem_GetNumberOfEventMemoryEntries
  swc implementation DemMaster_0Implementation: programming-language=C, behavior=DemMaster_0InternalBehavior
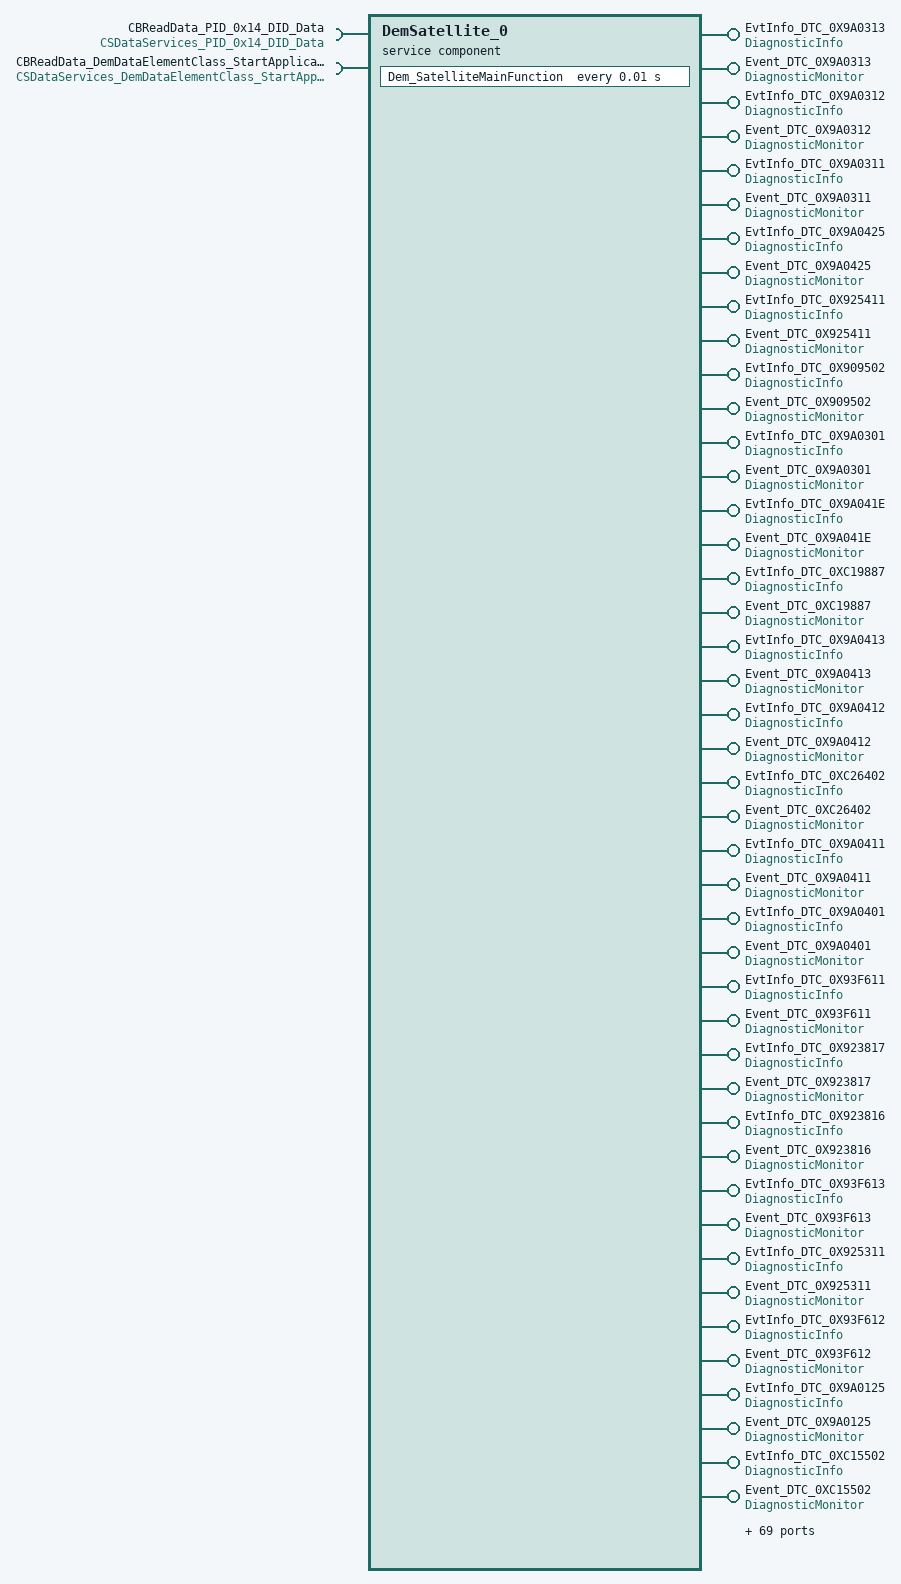
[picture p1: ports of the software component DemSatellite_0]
  service sw component type DemSatellite_0: category=SERVICE_COMPONENT
    108 x provide port:
      EvtInfo_DTC_0X9A0313: provided-interface=DiagnosticInfo
      Event_DTC_0X9A0313: provided-interface=DiagnosticMonitor
      EvtInfo_DTC_0X9A0312: provided-interface=DiagnosticInfo
      Event_DTC_0X9A0312: provided-interface=DiagnosticMonitor
      EvtInfo_DTC_0X9A0311: provided-interface=DiagnosticInfo
      Event_DTC_0X9A0311: provided-interface=DiagnosticMonitor
      EvtInfo_DTC_0X9A0425: provided-interface=DiagnosticInfo
      Event_DTC_0X9A0425: provided-interface=DiagnosticMonitor
      EvtInfo_DTC_0X925411: provided-interface=DiagnosticInfo
      Event_DTC_0X925411: provided-interface=DiagnosticMonitor
      EvtInfo_DTC_0X909502: provided-interface=DiagnosticInfo
      Event_DTC_0X909502: provided-interface=DiagnosticMonitor
      EvtInfo_DTC_0X9A0301: provided-interface=DiagnosticInfo
      Event_DTC_0X9A0301: provided-interface=DiagnosticMonitor
      EvtInfo_DTC_0X9A041E: provided-interface=DiagnosticInfo
      Event_DTC_0X9A041E: provided-interface=DiagnosticMonitor
      EvtInfo_DTC_0XC19887: provided-interface=DiagnosticInfo
      Event_DTC_0XC19887: provided-interface=DiagnosticMonitor
      EvtInfo_DTC_0X9A0413: provided-interface=DiagnosticInfo
      Event_DTC_0X9A0413: provided-interface=DiagnosticMonitor
      EvtInfo_DTC_0X9A0412: provided-interface=DiagnosticInfo
      Event_DTC_0X9A0412: provided-interface=DiagnosticMonitor
      EvtInfo_DTC_0XC26402: provided-interface=DiagnosticInfo
      Event_DTC_0XC26402: provided-interface=DiagnosticMonitor
      EvtInfo_DTC_0X9A0411: provided-interface=DiagnosticInfo
      Event_DTC_0X9A0411: provided-interface=DiagnosticMonitor
      EvtInfo_DTC_0X9A0401: provided-interface=DiagnosticInfo
      Event_DTC_0X9A0401: provided-interface=DiagnosticMonitor
      EvtInfo_DTC_0X93F611: provided-interface=DiagnosticInfo
      Event_DTC_0X93F611: provided-interface=DiagnosticMonitor
      EvtInfo_DTC_0X923817: provided-interface=DiagnosticInfo
      Event_DTC_0X923817: provided-interface=DiagnosticMonitor
      EvtInfo_DTC_0X923816: provided-interface=DiagnosticInfo
      Event_DTC_0X923816: provided-interface=DiagnosticMonitor
      EvtInfo_DTC_0X93F613: provided-interface=DiagnosticInfo
      Event_DTC_0X93F613: provided-interface=DiagnosticMonitor
      EvtInfo_DTC_0X925311: provided-interface=DiagnosticInfo
      Event_DTC_0X925311: provided-interface=DiagnosticMonitor
      EvtInfo_DTC_0X93F612: provided-interface=DiagnosticInfo
      Event_DTC_0X93F612: provided-interface=DiagnosticMonitor
      EvtInfo_DTC_0X9A0125: provided-interface=DiagnosticInfo
      Event_DTC_0X9A0125: provided-interface=DiagnosticMonitor
      EvtInfo_DTC_0XC15502: provided-interface=DiagnosticInfo
      Event_DTC_0XC15502: provided-interface=DiagnosticMonitor
      EvtInfo_DTC_0X9A011E: provided-interface=DiagnosticInfo
      Event_DTC_0X9A011E: provided-interface=DiagnosticMonitor
      EvtInfo_DTC_0XC15582: provided-interface=DiagnosticInfo
      Event_DTC_0XC15582: provided-interface=DiagnosticMonitor
      EvtInfo_DTC_0XC01988: provided-interface=DiagnosticInfo
      Event_DTC_0XC01988: provided-interface=DiagnosticMonitor
      EvtInfo_DTC_0X9A0112: provided-interface=DiagnosticInfo
      Event_DTC_0X9A0112: provided-interface=DiagnosticMonitor
      EvtInfo_DTC_0X919F11: provided-interface=DiagnosticInfo
      Event_DTC_0X919F11: provided-interface=DiagnosticMonitor
      EvtInfo_DTC_0X9A0111: provided-interface=DiagnosticInfo
      Event_DTC_0X9A0111: provided-interface=DiagnosticMonitor
      EvtInfo_DTC_0X919F12: provided-interface=DiagnosticInfo
      Event_DTC_0X919F12: provided-interface=DiagnosticMonitor
      EvtInfo_DTC_0X919F13: provided-interface=DiagnosticInfo
      Event_DTC_0X919F13: provided-interface=DiagnosticMonitor
      EvtInfo_DTC_0X9A0113: provided-interface=DiagnosticInfo
      Event_DTC_0X9A0113: provided-interface=DiagnosticMonitor
      EvtInfo_DTC_0XC14687: provided-interface=DiagnosticInfo
      Event_DTC_0XC14687: provided-interface=DiagnosticMonitor
      EvtInfo_DTC_0X91BA63: provided-interface=DiagnosticInfo
      Event_DTC_0X91BA63: provided-interface=DiagnosticMonitor
      EvtInfo_DTC_0X9A0225: provided-interface=DiagnosticInfo
      Event_DTC_0X9A0225: provided-interface=DiagnosticMonitor
      EvtInfo_DTC_0XD10017: provided-interface=DiagnosticInfo
      Event_DTC_0XD10017: provided-interface=DiagnosticMonitor
      EvtInfo_DTC_0X93F512: provided-interface=DiagnosticInfo
      Event_DTC_0X93F512: provided-interface=DiagnosticMonitor
      EvtInfo_DTC_0X93F511: provided-interface=DiagnosticInfo
      Event_DTC_0X93F511: provided-interface=DiagnosticMonitor
      EvtInfo_DTC_0X925211: provided-interface=DiagnosticInfo
      Event_DTC_0X925211: provided-interface=DiagnosticMonitor
      EvtInfo_DTC_0X93F513: provided-interface=DiagnosticInfo
      Event_DTC_0X93F513: provided-interface=DiagnosticMonitor
      EvtInfo_DTC_0X9A0101: provided-interface=DiagnosticInfo
      Event_DTC_0X9A0101: provided-interface=DiagnosticMonitor
      EvtInfo_DTC_0X9A021E: provided-interface=DiagnosticInfo
      Event_DTC_0X9A021E: provided-interface=DiagnosticMonitor
      EvtInfo_DTC_0XA10604: provided-interface=DiagnosticInfo
      Event_DTC_0XA10604: provided-interface=DiagnosticMonitor
      EvtInfo_DTC_0XA10602: provided-interface=DiagnosticInfo
      Event_DTC_0XA10602: provided-interface=DiagnosticMonitor
      EvtInfo_DTC_0X908E87: provided-interface=DiagnosticInfo
      Event_DTC_0X908E87: provided-interface=DiagnosticMonitor
      EvtInfo_DTC_0X9A0211: provided-interface=DiagnosticInfo
      Event_DTC_0X9A0211: provided-interface=DiagnosticMonitor
      EvtInfo_DTC_0X9A0213: provided-interface=DiagnosticInfo
      Event_DTC_0X9A0213: provided-interface=DiagnosticMonitor
      EvtInfo_DTC_0X9A0212: provided-interface=DiagnosticInfo
      Event_DTC_0X9A0212: provided-interface=DiagnosticMonitor
      EvtInfo_DTC_0XA11204: provided-interface=DiagnosticInfo
      Event_DTC_0XA11204: provided-interface=DiagnosticMonitor
      EvtInfo_DTC_0X9A0325: provided-interface=DiagnosticInfo
      Event_DTC_0X9A0325: provided-interface=DiagnosticMonitor
      EvtInfo_DTC_0XD10116: provided-interface=DiagnosticInfo
      Event_DTC_0XD10116: provided-interface=DiagnosticMonitor
      EvtInfo_DTC_0X909602: provided-interface=DiagnosticInfo
      Event_DTC_0X909602: provided-interface=DiagnosticMonitor
      EvtInfo_DTC_0X9A0201: provided-interface=DiagnosticInfo
      Event_DTC_0X9A0201: provided-interface=DiagnosticMonitor
      EvtInfo_DTC_0X9A031E: provided-interface=DiagnosticInfo
      Event_DTC_0X9A031E: provided-interface=DiagnosticMonitor
      EvtInfo_DTC_0XC19988: provided-interface=DiagnosticInfo
      Event_DTC_0XC19988: provided-interface=DiagnosticMonitor
    require port CBReadData_PID_0x14_DID_Data: required-interface=CSDataServices_PID_0x14_DID_Data
    4 x provide port:
      EvtInfo_DemEventParameter_Ramtst: provided-interface=DiagnosticInfo
      Event_DemEventParameter_Ramtst: provided-interface=DiagnosticMonitor
      EvtInfo_DEM_EVENT_StartApplication: provided-interface=DiagnosticInfo
      Event_DEM_EVENT_StartApplication: provided-interface=DiagnosticMonitor
    require port CBReadData_DemDataElementClass_StartApplication: required-interface=CSDataServices_DemDataElementClass_StartApplication
    provide port GeneralEvtInfo: provided-interface=GeneralDiagnosticInfo
    behavior DemSatellite_0InternalBehavior: handle-termination-and-restart=NO-SUPPORT, included-data-type-set=data-type=[Dem_EventIdType, Dem_RatioIdType, Dem_EventStatusType, Dem_UdsStatusByteType, Dem_DTCFormatType, Dem_InitMonitorReasonType, Dem_OperationCycleStateType, Dem_DTCStatusMaskType, Dem_IndicatorStatusType, Dem_MaxDataValueType, Dem_DTCKindType, Dem_DTCGroupType, Dem_IumprDenomCondIdType, Dem_IumprDenomCondStatusType, Dem_DebounceResetStatusType, Dem_DebouncingStateType, Dem_IumprReadinessGroupType, Dem_DTRControlType, Dem_DTCSeverityType, Dem_MonitorStatusType]
      timing event Timer_Dem_SatelliteMainFunction: start-on-event=Dem_SatelliteMainFunction, period=0.01
      1243 x operation invoked event:
        OpEventGetEventUdsStatus_GetEventUdsStatus_EvtInfo_DTC_0X9A0313: start-on-event=DemSatellite_0InternalBehavior/GetEventUdsStatus, operation=EvtInfo_DTC_0X9A0313.GetEventUdsStatus
        OpEventGetEventUdsStatus_GetEventUdsStatus_Event_DTC_0X9A0313: start-on-event=DemSatellite_0InternalBehavior/GetEventUdsStatus, operation=Event_DTC_0X9A0313.GetEventUdsStatus
        OpEventGetEventUdsStatus_GetEventUdsStatus_EvtInfo_DTC_0X9A0312: start-on-event=DemSatellite_0InternalBehavior/GetEventUdsStatus, operation=EvtInfo_DTC_0X9A0312.GetEventUdsStatus
        OpEventGetEventUdsStatus_GetEventUdsStatus_Event_DTC_0X9A0312: start-on-event=DemSatellite_0InternalBehavior/GetEventUdsStatus, operation=Event_DTC_0X9A0312.GetEventUdsStatus
        OpEventGetEventUdsStatus_GetEventUdsStatus_EvtInfo_DTC_0X9A0311: start-on-event=DemSatellite_0InternalBehavior/GetEventUdsStatus, operation=EvtInfo_DTC_0X9A0311.GetEventUdsStatus
        OpEventGetEventUdsStatus_GetEventUdsStatus_Event_DTC_0X9A0311: start-on-event=DemSatellite_0InternalBehavior/GetEventUdsStatus, operation=Event_DTC_0X9A0311.GetEventUdsStatus
        OpEventGetEventUdsStatus_GetEventUdsStatus_EvtInfo_DTC_0X9A0425: start-on-event=DemSatellite_0InternalBehavior/GetEventUdsStatus, operation=EvtInfo_DTC_0X9A0425.GetEventUdsStatus
        OpEventGetEventUdsStatus_GetEventUdsStatus_Event_DTC_0X9A0425: start-on-event=DemSatellite_0InternalBehavior/GetEventUdsStatus, operation=Event_DTC_0X9A0425.GetEventUdsStatus
        OpEventGetEventUdsStatus_GetEventUdsStatus_EvtInfo_DTC_0X925411: start-on-event=DemSatellite_0InternalBehavior/GetEventUdsStatus, operation=EvtInfo_DTC_0X925411.GetEventUdsStatus
        OpEventGetEventUdsStatus_GetEventUdsStatus_Event_DTC_0X925411: start-on-event=DemSatellite_0InternalBehavior/GetEventUdsStatus, operation=Event_DTC_0X925411.GetEventUdsStatus
        OpEventGetEventUdsStatus_GetEventUdsStatus_EvtInfo_DTC_0X909502: start-on-event=DemSatellite_0InternalBehavior/GetEventUdsStatus, operation=EvtInfo_DTC_0X909502.GetEventUdsStatus
        OpEventGetEventUdsStatus_GetEventUdsStatus_Event_DTC_0X909502: start-on-event=DemSatellite_0InternalBehavior/GetEventUdsStatus, operation=Event_DTC_0X909502.GetEventUdsStatus
        OpEventGetEventUdsStatus_GetEventUdsStatus_EvtInfo_DTC_0X9A0301: start-on-event=DemSatellite_0InternalBehavior/GetEventUdsStatus, operation=EvtInfo_DTC_0X9A0301.GetEventUdsStatus
        OpEventGetEventUdsStatus_GetEventUdsStatus_Event_DTC_0X9A0301: start-on-event=DemSatellite_0InternalBehavior/GetEventUdsStatus, operation=Event_DTC_0X9A0301.GetEventUdsStatus
        OpEventGetEventUdsStatus_GetEventUdsStatus_EvtInfo_DTC_0X9A041E: start-on-event=DemSatellite_0InternalBehavior/GetEventUdsStatus, operation=EvtInfo_DTC_0X9A041E.GetEventUdsStatus
        OpEventGetEventUdsStatus_GetEventUdsStatus_Event_DTC_0X9A041E: start-on-event=DemSatellite_0InternalBehavior/GetEventUdsStatus, operation=Event_DTC_0X9A041E.GetEventUdsStatus
        OpEventGetEventUdsStatus_GetEventUdsStatus_EvtInfo_DTC_0XC19887: start-on-event=DemSatellite_0InternalBehavior/GetEventUdsStatus, operation=EvtInfo_DTC_0XC19887.GetEventUdsStatus
        OpEventGetEventUdsStatus_GetEventUdsStatus_Event_DTC_0XC19887: start-on-event=DemSatellite_0InternalBehavior/GetEventUdsStatus, operation=Event_DTC_0XC19887.GetEventUdsStatus
        OpEventGetEventUdsStatus_GetEventUdsStatus_EvtInfo_DTC_0X9A0413: start-on-event=DemSatellite_0InternalBehavior/GetEventUdsStatus, operation=EvtInfo_DTC_0X9A0413.GetEventUdsStatus
        OpEventGetEventUdsStatus_GetEventUdsStatus_Event_DTC_0X9A0413: start-on-event=DemSatellite_0InternalBehavior/GetEventUdsStatus, operation=Event_DTC_0X9A0413.GetEventUdsStatus
        OpEventGetEventUdsStatus_GetEventUdsStatus_EvtInfo_DTC_0X9A0412: start-on-event=DemSatellite_0InternalBehavior/GetEventUdsStatus, operation=EvtInfo_DTC_0X9A0412.GetEventUdsStatus
        OpEventGetEventUdsStatus_GetEventUdsStatus_Event_DTC_0X9A0412: start-on-event=DemSatellite_0InternalBehavior/GetEventUdsStatus, operation=Event_DTC_0X9A0412.GetEventUdsStatus
        OpEventGetEventUdsStatus_GetEventUdsStatus_EvtInfo_DTC_0XC26402: start-on-event=DemSatellite_0InternalBehavior/GetEventUdsStatus, operation=EvtInfo_DTC_0XC26402.GetEventUdsStatus
        OpEventGetEventUdsStatus_GetEventUdsStatus_Event_DTC_0XC26402: start-on-event=DemSatellite_0InternalBehavior/GetEventUdsStatus, operation=Event_DTC_0XC26402.GetEventUdsStatus
        OpEventGetEventUdsStatus_GetEventUdsStatus_EvtInfo_DTC_0X9A0411: start-on-event=DemSatellite_0InternalBehavior/GetEventUdsStatus, operation=EvtInfo_DTC_0X9A0411.GetEventUdsStatus
        OpEventGetEventUdsStatus_GetEventUdsStatus_Event_DTC_0X9A0411: start-on-event=DemSatellite_0InternalBehavior/GetEventUdsStatus, operation=Event_DTC_0X9A0411.GetEventUdsStatus
        OpEventGetEventUdsStatus_GetEventUdsStatus_EvtInfo_DTC_0X9A0401: start-on-event=DemSatellite_0InternalBehavior/GetEventUdsStatus, operation=EvtInfo_DTC_0X9A0401.GetEventUdsStatus
        OpEventGetEventUdsStatus_GetEventUdsStatus_Event_DTC_0X9A0401: start-on-event=DemSatellite_0InternalBehavior/GetEventUdsStatus, operation=Event_DTC_0X9A0401.GetEventUdsStatus
        OpEventGetEventUdsStatus_GetEventUdsStatus_EvtInfo_DTC_0X93F611: start-on-event=DemSatellite_0InternalBehavior/GetEventUdsStatus, operation=EvtInfo_DTC_0X93F611.GetEventUdsStatus
        OpEventGetEventUdsStatus_GetEventUdsStatus_Event_DTC_0X93F611: start-on-event=DemSatellite_0InternalBehavior/GetEventUdsStatus, operation=Event_DTC_0X93F611.GetEventUdsStatus
        OpEventGetEventUdsStatus_GetEventUdsStatus_EvtInfo_DTC_0X923817: start-on-event=DemSatellite_0InternalBehavior/GetEventUdsStatus, operation=EvtInfo_DTC_0X923817.GetEventUdsStatus
        OpEventGetEventUdsStatus_GetEventUdsStatus_Event_DTC_0X923817: start-on-event=DemSatellite_0InternalBehavior/GetEventUdsStatus, operation=Event_DTC_0X923817.GetEventUdsStatus
        OpEventGetEventUdsStatus_GetEventUdsStatus_EvtInfo_DTC_0X923816: start-on-event=DemSatellite_0InternalBehavior/GetEventUdsStatus, operation=EvtInfo_DTC_0X923816.GetEventUdsStatus
        OpEventGetEventUdsStatus_GetEventUdsStatus_Event_DTC_0X923816: start-on-event=DemSatellite_0InternalBehavior/GetEventUdsStatus, operation=Event_DTC_0X923816.GetEventUdsStatus
        OpEventGetEventUdsStatus_GetEventUdsStatus_EvtInfo_DTC_0X93F613: start-on-event=DemSatellite_0InternalBehavior/GetEventUdsStatus, operation=EvtInfo_DTC_0X93F613.GetEventUdsStatus
        OpEventGetEventUdsStatus_GetEventUdsStatus_Event_DTC_0X93F613: start-on-event=DemSatellite_0InternalBehavior/GetEventUdsStatus, operation=Event_DTC_0X93F613.GetEventUdsStatus
        OpEventGetEventUdsStatus_GetEventUdsStatus_EvtInfo_DTC_0X925311: start-on-event=DemSatellite_0InternalBehavior/GetEventUdsStatus, operation=EvtInfo_DTC_0X925311.GetEventUdsStatus
        OpEventGetEventUdsStatus_GetEventUdsStatus_Event_DTC_0X925311: start-on-event=DemSatellite_0InternalBehavior/GetEventUdsStatus, operation=Event_DTC_0X925311.GetEventUdsStatus
        OpEventGetEventUdsStatus_GetEventUdsStatus_EvtInfo_DTC_0X93F612: start-on-event=DemSatellite_0InternalBehavior/GetEventUdsStatus, operation=EvtInfo_DTC_0X93F612.GetEventUdsStatus
        OpEventGetEventUdsStatus_GetEventUdsStatus_Event_DTC_0X93F612: start-on-event=DemSatellite_0InternalBehavior/GetEventUdsStatus, operation=Event_DTC_0X93F612.GetEventUdsStatus
        OpEventGetEventUdsStatus_GetEventUdsStatus_EvtInfo_DTC_0X9A0125: start-on-event=DemSatellite_0InternalBehavior/GetEventUdsStatus, operation=EvtInfo_DTC_0X9A0125.GetEventUdsStatus
        OpEventGetEventUdsStatus_GetEventUdsStatus_Event_DTC_0X9A0125: start-on-event=DemSatellite_0InternalBehavior/GetEventUdsStatus, operation=Event_DTC_0X9A0125.GetEventUdsStatus
        OpEventGetEventUdsStatus_GetEventUdsStatus_EvtInfo_DTC_0XC15502: start-on-event=DemSatellite_0InternalBehavior/GetEventUdsStatus, operation=EvtInfo_DTC_0XC15502.GetEventUdsStatus
        OpEventGetEventUdsStatus_GetEventUdsStatus_Event_DTC_0XC15502: start-on-event=DemSatellite_0InternalBehavior/GetEventUdsStatus, operation=Event_DTC_0XC15502.GetEventUdsStatus
        OpEventGetEventUdsStatus_GetEventUdsStatus_EvtInfo_DTC_0X9A011E: start-on-event=DemSatellite_0InternalBehavior/GetEventUdsStatus, operation=EvtInfo_DTC_0X9A011E.GetEventUdsStatus
        OpEventGetEventUdsStatus_GetEventUdsStatus_Event_DTC_0X9A011E: start-on-event=DemSatellite_0InternalBehavior/GetEventUdsStatus, operation=Event_DTC_0X9A011E.GetEventUdsStatus
        OpEventGetEventUdsStatus_GetEventUdsStatus_EvtInfo_DTC_0XC15582: start-on-event=DemSatellite_0InternalBehavior/GetEventUdsStatus, operation=EvtInfo_DTC_0XC15582.GetEventUdsStatus
        OpEventGetEventUdsStatus_GetEventUdsStatus_Event_DTC_0XC15582: start-on-event=DemSatellite_0InternalBehavior/GetEventUdsStatus, operation=Event_DTC_0XC15582.GetEventUdsStatus
        OpEventGetEventUdsStatus_GetEventUdsStatus_EvtInfo_DTC_0XC01988: start-on-event=DemSatellite_0InternalBehavior/GetEventUdsStatus, operation=EvtInfo_DTC_0XC01988.GetEventUdsStatus
        OpEventGetEventUdsStatus_GetEventUdsStatus_Event_DTC_0XC01988: start-on-event=DemSatellite_0InternalBehavior/GetEventUdsStatus, operation=Event_DTC_0XC01988.GetEventUdsStatus
        OpEventGetEventUdsStatus_GetEventUdsStatus_EvtInfo_DTC_0X9A0112: start-on-event=DemSatellite_0InternalBehavior/GetEventUdsStatus, operation=EvtInfo_DTC_0X9A0112.GetEventUdsStatus
        OpEventGetEventUdsStatus_GetEventUdsStatus_Event_DTC_0X9A0112: start-on-event=DemSatellite_0InternalBehavior/GetEventUdsStatus, operation=Event_DTC_0X9A0112.GetEventUdsStatus
        OpEventGetEventUdsStatus_GetEventUdsStatus_EvtInfo_DTC_0X919F11: start-on-event=DemSatellite_0InternalBehavior/GetEventUdsStatus, operation=EvtInfo_DTC_0X919F11.GetEventUdsStatus
        OpEventGetEventUdsStatus_GetEventUdsStatus_Event_DTC_0X919F11: start-on-event=DemSatellite_0InternalBehavior/GetEventUdsStatus, operation=Event_DTC_0X919F11.GetEventUdsStatus
        OpEventGetEventUdsStatus_GetEventUdsStatus_EvtInfo_DTC_0X9A0111: start-on-event=DemSatellite_0InternalBehavior/GetEventUdsStatus, operation=EvtInfo_DTC_0X9A0111.GetEventUdsStatus
        OpEventGetEventUdsStatus_GetEventUdsStatus_Event_DTC_0X9A0111: start-on-event=DemSatellite_0InternalBehavior/GetEventUdsStatus, operation=Event_DTC_0X9A0111.GetEventUdsStatus
        OpEventGetEventUdsStatus_GetEventUdsStatus_EvtInfo_DTC_0X919F12: start-on-event=DemSatellite_0InternalBehavior/GetEventUdsStatus, operation=EvtInfo_DTC_0X919F12.GetEventUdsStatus
        OpEventGetEventUdsStatus_GetEventUdsStatus_Event_DTC_0X919F12: start-on-event=DemSatellite_0InternalBehavior/GetEventUdsStatus, operation=Event_DTC_0X919F12.GetEventUdsStatus
        OpEventGetEventUdsStatus_GetEventUdsStatus_EvtInfo_DTC_0X919F13: start-on-event=DemSatellite_0InternalBehavior/GetEventUdsStatus, operation=EvtInfo_DTC_0X919F13.GetEventUdsStatus
        OpEventGetEventUdsStatus_GetEventUdsStatus_Event_DTC_0X919F13: start-on-event=DemSatellite_0InternalBehavior/GetEventUdsStatus, operation=Event_DTC_0X919F13.GetEventUdsStatus
        OpEventGetEventUdsStatus_GetEventUdsStatus_EvtInfo_DTC_0X9A0113: start-on-event=DemSatellite_0InternalBehavior/GetEventUdsStatus, operation=EvtInfo_DTC_0X9A0113.GetEventUdsStatus
        OpEventGetEventUdsStatus_GetEventUdsStatus_Event_DTC_0X9A0113: start-on-event=DemSatellite_0InternalBehavior/GetEventUdsStatus, operation=Event_DTC_0X9A0113.GetEventUdsStatus
        OpEventGetEventUdsStatus_GetEventUdsStatus_EvtInfo_DTC_0XC14687: start-on-event=DemSatellite_0InternalBehavior/GetEventUdsStatus, operation=EvtInfo_DTC_0XC14687.GetEventUdsStatus
        OpEventGetEventUdsStatus_GetEventUdsStatus_Event_DTC_0XC14687: start-on-event=DemSatellite_0InternalBehavior/GetEventUdsStatus, operation=Event_DTC_0XC14687.GetEventUdsStatus
        OpEventGetEventUdsStatus_GetEventUdsStatus_EvtInfo_DTC_0X91BA63: start-on-event=DemSatellite_0InternalBehavior/GetEventUdsStatus, operation=EvtInfo_DTC_0X91BA63.GetEventUdsStatus
        OpEventGetEventUdsStatus_GetEventUdsStatus_Event_DTC_0X91BA63: start-on-event=DemSatellite_0InternalBehavior/GetEventUdsStatus, operation=Event_DTC_0X91BA63.GetEventUdsStatus
        OpEventGetEventUdsStatus_GetEventUdsStatus_EvtInfo_DTC_0X9A0225: start-on-event=DemSatellite_0InternalBehavior/GetEventUdsStatus, operation=EvtInfo_DTC_0X9A0225.GetEventUdsStatus
        OpEventGetEventUdsStatus_GetEventUdsStatus_Event_DTC_0X9A0225: start-on-event=DemSatellite_0InternalBehavior/GetEventUdsStatus, operation=Event_DTC_0X9A0225.GetEventUdsStatus
        OpEventGetEventUdsStatus_GetEventUdsStatus_EvtInfo_DTC_0XD10017: start-on-event=DemSatellite_0InternalBehavior/GetEventUdsStatus, operation=EvtInfo_DTC_0XD10017.GetEventUdsStatus
        OpEventGetEventUdsStatus_GetEventUdsStatus_Event_DTC_0XD10017: start-on-event=DemSatellite_0InternalBehavior/GetEventUdsStatus, operation=Event_DTC_0XD10017.GetEventUdsStatus
        OpEventGetEventUdsStatus_GetEventUdsStatus_EvtInfo_DTC_0X93F512: start-on-event=DemSatellite_0InternalBehavior/GetEventUdsStatus, operation=EvtInfo_DTC_0X93F512.GetEventUdsStatus
        OpEventGetEventUdsStatus_GetEventUdsStatus_Event_DTC_0X93F512: start-on-event=DemSatellite_0InternalBehavior/GetEventUdsStatus, operation=Event_DTC_0X93F512.GetEventUdsStatus
        OpEventGetEventUdsStatus_GetEventUdsStatus_EvtInfo_DTC_0X93F511: start-on-event=DemSatellite_0InternalBehavior/GetEventUdsStatus, operation=EvtInfo_DTC_0X93F511.GetEventUdsStatus
        OpEventGetEventUdsStatus_GetEventUdsStatus_Event_DTC_0X93F511: start-on-event=DemSatellite_0InternalBehavior/GetEventUdsStatus, operation=Event_DTC_0X93F511.GetEventUdsStatus
        OpEventGetEventUdsStatus_GetEventUdsStatus_EvtInfo_DTC_0X925211: start-on-event=DemSatellite_0InternalBehavior/GetEventUdsStatus, operation=EvtInfo_DTC_0X925211.GetEventUdsStatus
        OpEventGetEventUdsStatus_GetEventUdsStatus_Event_DTC_0X925211: start-on-event=DemSatellite_0InternalBehavior/GetEventUdsStatus, operation=Event_DTC_0X925211.GetEventUdsStatus
        OpEventGetEventUdsStatus_GetEventUdsStatus_EvtInfo_DTC_0X93F513: start-on-event=DemSatellite_0InternalBehavior/GetEventUdsStatus, operation=EvtInfo_DTC_0X93F513.GetEventUdsStatus
        OpEventGetEventUdsStatus_GetEventUdsStatus_Event_DTC_0X93F513: start-on-event=DemSatellite_0InternalBehavior/GetEventUdsStatus, operation=Event_DTC_0X93F513.GetEventUdsStatus
        OpEventGetEventUdsStatus_GetEventUdsStatus_EvtInfo_DTC_0X9A0101: start-on-event=DemSatellite_0InternalBehavior/GetEventUdsStatus, operation=EvtInfo_DTC_0X9A0101.GetEventUdsStatus
        OpEventGetEventUdsStatus_GetEventUdsStatus_Event_DTC_0X9A0101: start-on-event=DemSatellite_0InternalBehavior/GetEventUdsStatus, operation=Event_DTC_0X9A0101.GetEventUdsStatus
        OpEventGetEventUdsStatus_GetEventUdsStatus_EvtInfo_DTC_0X9A021E: start-on-event=DemSatellite_0InternalBehavior/GetEventUdsStatus, operation=EvtInfo_DTC_0X9A021E.GetEventUdsStatus
        OpEventGetEventUdsStatus_GetEventUdsStatus_Event_DTC_0X9A021E: start-on-event=DemSatellite_0InternalBehavior/GetEventUdsStatus, operation=Event_DTC_0X9A021E.GetEventUdsStatus
        OpEventGetEventUdsStatus_GetEventUdsStatus_EvtInfo_DTC_0XA10604: start-on-event=DemSatellite_0InternalBehavior/GetEventUdsStatus, operation=EvtInfo_DTC_0XA10604.GetEventUdsStatus
        OpEventGetEventUdsStatus_GetEventUdsStatus_Event_DTC_0XA10604: start-on-event=DemSatellite_0InternalBehavior/GetEventUdsStatus, operation=Event_DTC_0XA10604.GetEventUdsStatus
        OpEventGetEventUdsStatus_GetEventUdsStatus_EvtInfo_DTC_0XA10602: start-on-event=DemSatellite_0InternalBehavior/GetEventUdsStatus, operation=EvtInfo_DTC_0XA10602.GetEventUdsStatus
        OpEventGetEventUdsStatus_GetEventUdsStatus_Event_DTC_0XA10602: start-on-event=DemSatellite_0InternalBehavior/GetEventUdsStatus, operation=Event_DTC_0XA10602.GetEventUdsStatus
        OpEventGetEventUdsStatus_GetEventUdsStatus_EvtInfo_DTC_0X908E87: start-on-event=DemSatellite_0InternalBehavior/GetEventUdsStatus, operation=EvtInfo_DTC_0X908E87.GetEventUdsStatus
        OpEventGetEventUdsStatus_GetEventUdsStatus_Event_DTC_0X908E87: start-on-event=DemSatellite_0InternalBehavior/GetEventUdsStatus, operation=Event_DTC_0X908E87.GetEventUdsStatus
        OpEventGetEventUdsStatus_GetEventUdsStatus_EvtInfo_DTC_0X9A0211: start-on-event=DemSatellite_0InternalBehavior/GetEventUdsStatus, operation=EvtInfo_DTC_0X9A0211.GetEventUdsStatus
        OpEventGetEventUdsStatus_GetEventUdsStatus_Event_DTC_0X9A0211: start-on-event=DemSatellite_0InternalBehavior/GetEventUdsStatus, operation=Event_DTC_0X9A0211.GetEventUdsStatus
        OpEventGetEventUdsStatus_GetEventUdsStatus_EvtInfo_DTC_0X9A0213: start-on-event=DemSatellite_0InternalBehavior/GetEventUdsStatus, operation=EvtInfo_DTC_0X9A0213.GetEventUdsStatus
        OpEventGetEventUdsStatus_GetEventUdsStatus_Event_DTC_0X9A0213: start-on-event=DemSatellite_0InternalBehavior/GetEventUdsStatus, operation=Event_DTC_0X9A0213.GetEventUdsStatus
        OpEventGetEventUdsStatus_GetEventUdsStatus_EvtInfo_DTC_0X9A0212: start-on-event=DemSatellite_0InternalBehavior/GetEventUdsStatus, operation=EvtInfo_DTC_0X9A0212.GetEventUdsStatus
        OpEventGetEventUdsStatus_GetEventUdsStatus_Event_DTC_0X9A0212: start-on-event=DemSatellite_0InternalBehavior/GetEventUdsStatus, operation=Event_DTC_0X9A0212.GetEventUdsStatus
        OpEventGetEventUdsStatus_GetEventUdsStatus_EvtInfo_DTC_0XA11204: start-on-event=DemSatellite_0InternalBehavior/GetEventUdsStatus, operation=EvtInfo_DTC_0XA11204.GetEventUdsStatus
        OpEventGetEventUdsStatus_GetEventUdsStatus_Event_DTC_0XA11204: start-on-event=DemSatellite_0InternalBehavior/GetEventUdsStatus, operation=Event_DTC_0XA11204.GetEventUdsStatus
        OpEventGetEventUdsStatus_GetEventUdsStatus_EvtInfo_DTC_0X9A0325: start-on-event=DemSatellite_0InternalBehavior/GetEventUdsStatus, operation=EvtInfo_DTC_0X9A0325.GetEventUdsStatus
        OpEventGetEventUdsStatus_GetEventUdsStatus_Event_DTC_0X9A0325: start-on-event=DemSatellite_0InternalBehavior/GetEventUdsStatus, operation=Event_DTC_0X9A0325.GetEventUdsStatus
        OpEventGetEventUdsStatus_GetEventUdsStatus_EvtInfo_DTC_0XD10116: start-on-event=DemSatellite_0InternalBehavior/GetEventUdsStatus, operation=EvtInfo_DTC_0XD10116.GetEventUdsStatus
        OpEventGetEventUdsStatus_GetEventUdsStatus_Event_DTC_0XD10116: start-on-event=DemSatellite_0InternalBehavior/GetEventUdsStatus, operation=Event_DTC_0XD10116.GetEventUdsStatus
        OpEventGetEventUdsStatus_GetEventUdsStatus_EvtInfo_DTC_0X909602: start-on-event=DemSatellite_0InternalBehavior/GetEventUdsStatus, operation=EvtInfo_DTC_0X909602.GetEventUdsStatus
        OpEventGetEventUdsStatus_GetEventUdsStatus_Event_DTC_0X909602: start-on-event=DemSatellite_0InternalBehavior/GetEventUdsStatus, operation=Event_DTC_0X909602.GetEventUdsStatus
        OpEventGetEventUdsStatus_GetEventUdsStatus_EvtInfo_DTC_0X9A0201: start-on-event=DemSatellite_0InternalBehavior/GetEventUdsStatus, operation=EvtInfo_DTC_0X9A0201.GetEventUdsStatus
        OpEventGetEventUdsStatus_GetEventUdsStatus_Event_DTC_0X9A0201: start-on-event=DemSatellite_0InternalBehavior/GetEventUdsStatus, operation=Event_DTC_0X9A0201.GetEventUdsStatus
        OpEventGetEventUdsStatus_GetEventUdsStatus_EvtInfo_DTC_0X9A031E: start-on-event=DemSatellite_0InternalBehavior/GetEventUdsStatus, operation=EvtInfo_DTC_0X9A031E.GetEventUdsStatus
        OpEventGetEventUdsStatus_GetEventUdsStatus_Event_DTC_0X9A031E: start-on-event=DemSatellite_0InternalBehavior/GetEventUdsStatus, operation=Event_DTC_0X9A031E.GetEventUdsStatus
        OpEventGetEventUdsStatus_GetEventUdsStatus_EvtInfo_DTC_0XC19988: start-on-event=DemSatellite_0InternalBehavior/GetEventUdsStatus, operation=EvtInfo_DTC_0XC19988.GetEventUdsStatus
        OpEventGetEventUdsStatus_GetEventUdsStatus_Event_DTC_0XC19988: start-on-event=DemSatellite_0InternalBehavior/GetEventUdsStatus, operation=Event_DTC_0XC19988.GetEventUdsStatus
        OpEventGetEventStatus_GetEventStatus_EvtInfo_DTC_0X9A0313: start-on-event=DemSatellite_0InternalBehavior/GetEventStatus, operation=EvtInfo_DTC_0X9A0313.GetEventStatus
        OpEventGetEventStatus_GetEventStatus_Event_DTC_0X9A0313: start-on-event=DemSatellite_0InternalBehavior/GetEventStatus, operation=Event_DTC_0X9A0313.GetEventStatus
        OpEventGetEventStatus_GetEventStatus_EvtInfo_DTC_0X9A0312: start-on-event=DemSatellite_0InternalBehavior/GetEventStatus, operation=EvtInfo_DTC_0X9A0312.GetEventStatus
        OpEventGetEventStatus_GetEventStatus_Event_DTC_0X9A0312: start-on-event=DemSatellite_0InternalBehavior/GetEventStatus, operation=Event_DTC_0X9A0312.GetEventStatus
        OpEventGetEventStatus_GetEventStatus_EvtInfo_DTC_0X9A0311: start-on-event=DemSatellite_0InternalBehavior/GetEventStatus, operation=EvtInfo_DTC_0X9A0311.GetEventStatus
        OpEventGetEventStatus_GetEventStatus_Event_DTC_0X9A0311: start-on-event=DemSatellite_0InternalBehavior/GetEventStatus, operation=Event_DTC_0X9A0311.GetEventStatus
        OpEventGetEventStatus_GetEventStatus_EvtInfo_DTC_0X9A0425: start-on-event=DemSatellite_0InternalBehavior/GetEventStatus, operation=EvtInfo_DTC_0X9A0425.GetEventStatus
        OpEventGetEventStatus_GetEventStatus_Event_DTC_0X9A0425: start-on-event=DemSatellite_0InternalBehavior/GetEventStatus, operation=Event_DTC_0X9A0425.GetEventStatus
        OpEventGetEventStatus_GetEventStatus_EvtInfo_DTC_0X925411: start-on-event=DemSatellite_0InternalBehavior/GetEventStatus, operation=EvtInfo_DTC_0X925411.GetEventStatus
        OpEventGetEventStatus_GetEventStatus_Event_DTC_0X925411: start-on-event=DemSatellite_0InternalBehavior/GetEventStatus, operation=Event_DTC_0X925411.GetEventStatus
        OpEventGetEventStatus_GetEventStatus_EvtInfo_DTC_0X909502: start-on-event=DemSatellite_0InternalBehavior/GetEventStatus, operation=EvtInfo_DTC_0X909502.GetEventStatus
        OpEventGetEventStatus_GetEventStatus_Event_DTC_0X909502: start-on-event=DemSatellite_0InternalBehavior/GetEventStatus, operation=Event_DTC_0X909502.GetEventStatus
        OpEventGetEventStatus_GetEventStatus_EvtInfo_DTC_0X9A0301: start-on-event=DemSatellite_0InternalBehavior/GetEventStatus, operation=EvtInfo_DTC_0X9A0301.GetEventStatus
        OpEventGetEventStatus_GetEventStatus_Event_DTC_0X9A0301: start-on-event=DemSatellite_0InternalBehavior/GetEventStatus, operation=Event_DTC_0X9A0301.GetEventStatus
        OpEventGetEventStatus_GetEventStatus_EvtInfo_DTC_0X9A041E: start-on-event=DemSatellite_0InternalBehavior/GetEventStatus, operation=EvtInfo_DTC_0X9A041E.GetEventStatus
        OpEventGetEventStatus_GetEventStatus_Event_DTC_0X9A041E: start-on-event=DemSatellite_0InternalBehavior/GetEventStatus, operation=Event_DTC_0X9A041E.GetEventStatus
        OpEventGetEventStatus_GetEventStatus_EvtInfo_DTC_0XC19887: start-on-event=DemSatellite_0InternalBehavior/GetEventStatus, operation=EvtInfo_DTC_0XC19887.GetEventStatus
        OpEventGetEventStatus_GetEventStatus_Event_DTC_0XC19887: start-on-event=DemSatellite_0InternalBehavior/GetEventStatus, operation=Event_DTC_0XC19887.GetEventStatus
        OpEventGetEventStatus_GetEventStatus_EvtInfo_DTC_0X9A0413: start-on-event=DemSatellite_0InternalBehavior/GetEventStatus, operation=EvtInfo_DTC_0X9A0413.GetEventStatus
        OpEventGetEventStatus_GetEventStatus_Event_DTC_0X9A0413: start-on-event=DemSatellite_0InternalBehavior/GetEventStatus, operation=Event_DTC_0X9A0413.GetEventStatus
        OpEventGetEventStatus_GetEventStatus_EvtInfo_DTC_0X9A0412: start-on-event=DemSatellite_0InternalBehavior/GetEventStatus, operation=EvtInfo_DTC_0X9A0412.GetEventStatus
        OpEventGetEventStatus_GetEventStatus_Event_DTC_0X9A0412: start-on-event=DemSatellite_0InternalBehavior/GetEventStatus, operation=Event_DTC_0X9A0412.GetEventStatus
        OpEventGetEventStatus_GetEventStatus_EvtInfo_DTC_0XC26402: start-on-event=DemSatellite_0InternalBehavior/GetEventStatus, operation=EvtInfo_DTC_0XC26402.GetEventStatus
        OpEventGetEventStatus_GetEventStatus_Event_DTC_0XC26402: start-on-event=DemSatellite_0InternalBehavior/GetEventStatus, operation=Event_DTC_0XC26402.GetEventStatus
        OpEventGetEventStatus_GetEventStatus_EvtInfo_DTC_0X9A0411: start-on-event=DemSatellite_0InternalBehavior/GetEventStatus, operation=EvtInfo_DTC_0X9A0411.GetEventStatus
        OpEventGetEventStatus_GetEventStatus_Event_DTC_0X9A0411: start-on-event=DemSatellite_0InternalBehavior/GetEventStatus, operation=Event_DTC_0X9A0411.GetEventStatus
        OpEventGetEventStatus_GetEventStatus_EvtInfo_DTC_0X9A0401: start-on-event=DemSatellite_0InternalBehavior/GetEventStatus, operation=EvtInfo_DTC_0X9A0401.GetEventStatus
        OpEventGetEventStatus_GetEventStatus_Event_DTC_0X9A0401: start-on-event=DemSatellite_0InternalBehavior/GetEventStatus, operation=Event_DTC_0X9A0401.GetEventStatus
        OpEventGetEventStatus_GetEventStatus_EvtInfo_DTC_0X93F611: start-on-event=DemSatellite_0InternalBehavior/GetEventStatus, operation=EvtInfo_DTC_0X93F611.GetEventStatus
        OpEventGetEventStatus_GetEventStatus_Event_DTC_0X93F611: start-on-event=DemSatellite_0InternalBehavior/GetEventStatus, operation=Event_DTC_0X93F611.GetEventStatus
        OpEventGetEventStatus_GetEventStatus_EvtInfo_DTC_0X923817: start-on-event=DemSatellite_0InternalBehavior/GetEventStatus, operation=EvtInfo_DTC_0X923817.GetEventStatus
        OpEventGetEventStatus_GetEventStatus_Event_DTC_0X923817: start-on-event=DemSatellite_0InternalBehavior/GetEventStatus, operation=Event_DTC_0X923817.GetEventStatus
        OpEventGetEventStatus_GetEventStatus_EvtInfo_DTC_0X923816: start-on-event=DemSatellite_0InternalBehavior/GetEventStatus, operation=EvtInfo_DTC_0X923816.GetEventStatus
        OpEventGetEventStatus_GetEventStatus_Event_DTC_0X923816: start-on-event=DemSatellite_0InternalBehavior/GetEventStatus, operation=Event_DTC_0X923816.GetEventStatus
        OpEventGetEventStatus_GetEventStatus_EvtInfo_DTC_0X93F613: start-on-event=DemSatellite_0InternalBehavior/GetEventStatus, operation=EvtInfo_DTC_0X93F613.GetEventStatus
        OpEventGetEventStatus_GetEventStatus_Event_DTC_0X93F613: start-on-event=DemSatellite_0InternalBehavior/GetEventStatus, operation=Event_DTC_0X93F613.GetEventStatus
        OpEventGetEventStatus_GetEventStatus_EvtInfo_DTC_0X925311: start-on-event=DemSatellite_0InternalBehavior/GetEventStatus, operation=EvtInfo_DTC_0X925311.GetEventStatus
        OpEventGetEventStatus_GetEventStatus_Event_DTC_0X925311: start-on-event=DemSatellite_0InternalBehavior/GetEventStatus, operation=Event_DTC_0X925311.GetEventStatus
        OpEventGetEventStatus_GetEventStatus_EvtInfo_DTC_0X93F612: start-on-event=DemSatellite_0InternalBehavior/GetEventStatus, operation=EvtInfo_DTC_0X93F612.GetEventStatus
        OpEventGetEventStatus_GetEventStatus_Event_DTC_0X93F612: start-on-event=DemSatellite_0InternalBehavior/GetEventStatus, operation=Event_DTC_0X93F612.GetEventStatus
        OpEventGetEventStatus_GetEventStatus_EvtInfo_DTC_0X9A0125: start-on-event=DemSatellite_0InternalBehavior/GetEventStatus, operation=EvtInfo_DTC_0X9A0125.GetEventStatus
        OpEventGetEventStatus_GetEventStatus_Event_DTC_0X9A0125: start-on-event=DemSatellite_0InternalBehavior/GetEventStatus, operation=Event_DTC_0X9A0125.GetEventStatus
        OpEventGetEventStatus_GetEventStatus_EvtInfo_DTC_0XC15502: start-on-event=DemSatellite_0InternalBehavior/GetEventStatus, operation=EvtInfo_DTC_0XC15502.GetEventStatus
        OpEventGetEventStatus_GetEventStatus_Event_DTC_0XC15502: start-on-event=DemSatellite_0InternalBehavior/GetEventStatus, operation=Event_DTC_0XC15502.GetEventStatus
        OpEventGetEventStatus_GetEventStatus_EvtInfo_DTC_0X9A011E: start-on-event=DemSatellite_0InternalBehavior/GetEventStatus, operation=EvtInfo_DTC_0X9A011E.GetEventStatus
        OpEventGetEventStatus_GetEventStatus_Event_DTC_0X9A011E: start-on-event=DemSatellite_0InternalBehavior/GetEventStatus, operation=Event_DTC_0X9A011E.GetEventStatus
        OpEventGetEventStatus_GetEventStatus_EvtInfo_DTC_0XC15582: start-on-event=DemSatellite_0InternalBehavior/GetEventStatus, operation=EvtInfo_DTC_0XC15582.GetEventStatus
        OpEventGetEventStatus_GetEventStatus_Event_DTC_0XC15582: start-on-event=DemSatellite_0InternalBehavior/GetEventStatus, operation=Event_DTC_0XC15582.GetEventStatus
        OpEventGetEventStatus_GetEventStatus_EvtInfo_DTC_0XC01988: start-on-event=DemSatellite_0InternalBehavior/GetEventStatus, operation=EvtInfo_DTC_0XC01988.GetEventStatus
        OpEventGetEventStatus_GetEventStatus_Event_DTC_0XC01988: start-on-event=DemSatellite_0InternalBehavior/GetEventStatus, operation=Event_DTC_0XC01988.GetEventStatus
        OpEventGetEventStatus_GetEventStatus_EvtInfo_DTC_0X9A0112: start-on-event=DemSatellite_0InternalBehavior/GetEventStatus, operation=EvtInfo_DTC_0X9A0112.GetEventStatus
        OpEventGetEventStatus_GetEventStatus_Event_DTC_0X9A0112: start-on-event=DemSatellite_0InternalBehavior/GetEventStatus, operation=Event_DTC_0X9A0112.GetEventStatus
        OpEventGetEventStatus_GetEventStatus_EvtInfo_DTC_0X919F11: start-on-event=DemSatellite_0InternalBehavior/GetEventStatus, operation=EvtInfo_DTC_0X919F11.GetEventStatus
        OpEventGetEventStatus_GetEventStatus_Event_DTC_0X919F11: start-on-event=DemSatellite_0InternalBehavior/GetEventStatus, operation=Event_DTC_0X919F11.GetEventStatus
        OpEventGetEventStatus_GetEventStatus_EvtInfo_DTC_0X9A0111: start-on-event=DemSatellite_0InternalBehavior/GetEventStatus, operation=EvtInfo_DTC_0X9A0111.GetEventStatus
        OpEventGetEventStatus_GetEventStatus_Event_DTC_0X9A0111: start-on-event=DemSatellite_0InternalBehavior/GetEventStatus, operation=Event_DTC_0X9A0111.GetEventStatus
        OpEventGetEventStatus_GetEventStatus_EvtInfo_DTC_0X919F12: start-on-event=DemSatellite_0InternalBehavior/GetEventStatus, operation=EvtInfo_DTC_0X919F12.GetEventStatus
        OpEventGetEventStatus_GetEventStatus_Event_DTC_0X919F12: start-on-event=DemSatellite_0InternalBehavior/GetEventStatus, operation=Event_DTC_0X919F12.GetEventStatus
        OpEventGetEventStatus_GetEventStatus_EvtInfo_DTC_0X919F13: start-on-event=DemSatellite_0InternalBehavior/GetEventStatus, operation=EvtInfo_DTC_0X919F13.GetEventStatus
        OpEventGetEventStatus_GetEventStatus_Event_DTC_0X919F13: start-on-event=DemSatellite_0InternalBehavior/GetEventStatus, operation=Event_DTC_0X919F13.GetEventStatus
        OpEventGetEventStatus_GetEventStatus_EvtInfo_DTC_0X9A0113: start-on-event=DemSatellite_0InternalBehavior/GetEventStatus, operation=EvtInfo_DTC_0X9A0113.GetEventStatus
        OpEventGetEventStatus_GetEventStatus_Event_DTC_0X9A0113: start-on-event=DemSatellite_0InternalBehavior/GetEventStatus, operation=Event_DTC_0X9A0113.GetEventStatus
        OpEventGetEventStatus_GetEventStatus_EvtInfo_DTC_0XC14687: start-on-event=DemSatellite_0InternalBehavior/GetEventStatus, operation=EvtInfo_DTC_0XC14687.GetEventStatus
        OpEventGetEventStatus_GetEventStatus_Event_DTC_0XC14687: start-on-event=DemSatellite_0InternalBehavior/GetEventStatus, operation=Event_DTC_0XC14687.GetEventStatus
        OpEventGetEventStatus_GetEventStatus_EvtInfo_DTC_0X91BA63: start-on-event=DemSatellite_0InternalBehavior/GetEventStatus, operation=EvtInfo_DTC_0X91BA63.GetEventStatus
        OpEventGetEventStatus_GetEventStatus_Event_DTC_0X91BA63: start-on-event=DemSatellite_0InternalBehavior/GetEventStatus, operation=Event_DTC_0X91BA63.GetEventStatus
        OpEventGetEventStatus_GetEventStatus_EvtInfo_DTC_0X9A0225: start-on-event=DemSatellite_0InternalBehavior/GetEventStatus, operation=EvtInfo_DTC_0X9A0225.GetEventStatus
        OpEventGetEventStatus_GetEventStatus_Event_DTC_0X9A0225: start-on-event=DemSatellite_0InternalBehavior/GetEventStatus, operation=Event_DTC_0X9A0225.GetEventStatus
        OpEventGetEventStatus_GetEventStatus_EvtInfo_DTC_0XD10017: start-on-event=DemSatellite_0InternalBehavior/GetEventStatus, operation=EvtInfo_DTC_0XD10017.GetEventStatus
        OpEventGetEventStatus_GetEventStatus_Event_DTC_0XD10017: start-on-event=DemSatellite_0InternalBehavior/GetEventStatus, operation=Event_DTC_0XD10017.GetEventStatus
        OpEventGetEventStatus_GetEventStatus_EvtInfo_DTC_0X93F512: start-on-event=DemSatellite_0InternalBehavior/GetEventStatus, operation=EvtInfo_DTC_0X93F512.GetEventStatus
        OpEventGetEventStatus_GetEventStatus_Event_DTC_0X93F512: start-on-event=DemSatellite_0InternalBehavior/GetEventStatus, operation=Event_DTC_0X93F512.GetEventStatus
        OpEventGetEventStatus_GetEventStatus_EvtInfo_DTC_0X93F511: start-on-event=DemSatellite_0InternalBehavior/GetEventStatus, operation=EvtInfo_DTC_0X93F511.GetEventStatus
        OpEventGetEventStatus_GetEventStatus_Event_DTC_0X93F511: start-on-event=DemSatellite_0InternalBehavior/GetEventStatus, operation=Event_DTC_0X93F511.GetEventStatus
        OpEventGetEventStatus_GetEventStatus_EvtInfo_DTC_0X925211: start-on-event=DemSatellite_0InternalBehavior/GetEventStatus, operation=EvtInfo_DTC_0X925211.GetEventStatus
        OpEventGetEventStatus_GetEventStatus_Event_DTC_0X925211: start-on-event=DemSatellite_0InternalBehavior/GetEventStatus, operation=Event_DTC_0X925211.GetEventStatus
        OpEventGetEventStatus_GetEventStatus_EvtInfo_DTC_0X93F513: start-on-event=DemSatellite_0InternalBehavior/GetEventStatus, operation=EvtInfo_DTC_0X93F513.GetEventStatus
        OpEventGetEventStatus_GetEventStatus_Event_DTC_0X93F513: start-on-event=DemSatellite_0InternalBehavior/GetEventStatus, operation=Event_DTC_0X93F513.GetEventStatus
        OpEventGetEventStatus_GetEventStatus_EvtInfo_DTC_0X9A0101: start-on-event=DemSatellite_0InternalBehavior/GetEventStatus, operation=EvtInfo_DTC_0X9A0101.GetEventStatus
        OpEventGetEventStatus_GetEventStatus_Event_DTC_0X9A0101: start-on-event=DemSatellite_0InternalBehavior/GetEventStatus, operation=Event_DTC_0X9A0101.GetEventStatus
        OpEventGetEventStatus_GetEventStatus_EvtInfo_DTC_0X9A021E: start-on-event=DemSatellite_0InternalBehavior/GetEventStatus, operation=EvtInfo_DTC_0X9A021E.GetEventStatus
        OpEventGetEventStatus_GetEventStatus_Event_DTC_0X9A021E: start-on-event=DemSatellite_0InternalBehavior/GetEventStatus, operation=Event_DTC_0X9A021E.GetEventStatus
        OpEventGetEventStatus_GetEventStatus_EvtInfo_DTC_0XA10604: start-on-event=DemSatellite_0InternalBehavior/GetEventStatus, operation=EvtInfo_DTC_0XA10604.GetEventStatus
        OpEventGetEventStatus_GetEventStatus_Event_DTC_0XA10604: start-on-event=DemSatellite_0InternalBehavior/GetEventStatus, operation=Event_DTC_0XA10604.GetEventStatus
        OpEventGetEventStatus_GetEventStatus_EvtInfo_DTC_0XA10602: start-on-event=DemSatellite_0InternalBehavior/GetEventStatus, operation=EvtInfo_DTC_0XA10602.GetEventStatus
        OpEventGetEventStatus_GetEventStatus_Event_DTC_0XA10602: start-on-event=DemSatellite_0InternalBehavior/GetEventStatus, operation=Event_DTC_0XA10602.GetEventStatus
        OpEventGetEventStatus_GetEventStatus_EvtInfo_DTC_0X908E87: start-on-event=DemSatellite_0InternalBehavior/GetEventStatus, operation=EvtInfo_DTC_0X908E87.GetEventStatus
        OpEventGetEventStatus_GetEventStatus_Event_DTC_0X908E87: start-on-event=DemSatellite_0InternalBehavior/GetEventStatus, operation=Event_DTC_0X908E87.GetEventStatus
        OpEventGetEventStatus_GetEventStatus_EvtInfo_DTC_0X9A0211: start-on-event=DemSatellite_0InternalBehavior/GetEventStatus, operation=EvtInfo_DTC_0X9A0211.GetEventStatus
        OpEventGetEventStatus_GetEventStatus_Event_DTC_0X9A0211: start-on-event=DemSatellite_0InternalBehavior/GetEventStatus, operation=Event_DTC_0X9A0211.GetEventStatus
        OpEventGetEventStatus_GetEventStatus_EvtInfo_DTC_0X9A0213: start-on-event=DemSatellite_0InternalBehavior/GetEventStatus, operation=EvtInfo_DTC_0X9A0213.GetEventStatus
        OpEventGetEventStatus_GetEventStatus_Event_DTC_0X9A0213: start-on-event=DemSatellite_0InternalBehavior/GetEventStatus, operation=Event_DTC_0X9A0213.GetEventStatus
        OpEventGetEventStatus_GetEventStatus_EvtInfo_DTC_0X9A0212: start-on-event=DemSatellite_0InternalBehavior/GetEventStatus, operation=EvtInfo_DTC_0X9A0212.GetEventStatus
        OpEventGetEventStatus_GetEventStatus_Event_DTC_0X9A0212: start-on-event=DemSatellite_0InternalBehavior/GetEventStatus, operation=Event_DTC_0X9A0212.GetEventStatus
        OpEventGetEventStatus_GetEventStatus_EvtInfo_DTC_0XA11204: start-on-event=DemSatellite_0InternalBehavior/GetEventStatus, operation=EvtInfo_DTC_0XA11204.GetEventStatus
        OpEventGetEventStatus_GetEventStatus_Event_DTC_0XA11204: start-on-event=DemSatellite_0InternalBehavior/GetEventStatus, operation=Event_DTC_0XA11204.GetEventStatus
        OpEventGetEventStatus_GetEventStatus_EvtInfo_DTC_0X9A0325: start-on-event=DemSatellite_0InternalBehavior/GetEventStatus, operation=EvtInfo_DTC_0X9A0325.GetEventStatus
        OpEventGetEventStatus_GetEventStatus_Event_DTC_0X9A0325: start-on-event=DemSatellite_0InternalBehavior/GetEventStatus, operation=Event_DTC_0X9A0325.GetEventStatus
        OpEventGetEventStatus_GetEventStatus_EvtInfo_DTC_0XD10116: start-on-event=DemSatellite_0InternalBehavior/GetEventStatus, operation=EvtInfo_DTC_0XD10116.GetEventStatus
        OpEventGetEventStatus_GetEventStatus_Event_DTC_0XD10116: start-on-event=DemSatellite_0InternalBehavior/GetEventStatus, operation=Event_DTC_0XD10116.GetEventStatus
        OpEventGetEventStatus_GetEventStatus_EvtInfo_DTC_0X909602: start-on-event=DemSatellite_0InternalBehavior/GetEventStatus, operation=EvtInfo_DTC_0X909602.GetEventStatus
        OpEventGetEventStatus_GetEventStatus_Event_DTC_0X909602: start-on-event=DemSatellite_0InternalBehavior/GetEventStatus, operation=Event_DTC_0X909602.GetEventStatus
        OpEventGetEventStatus_GetEventStatus_EvtInfo_DTC_0X9A0201: start-on-event=DemSatellite_0InternalBehavior/GetEventStatus, operation=EvtInfo_DTC_0X9A0201.GetEventStatus
        OpEventGetEventStatus_GetEventStatus_Event_DTC_0X9A0201: start-on-event=DemSatellite_0InternalBehavior/GetEventStatus, operation=Event_DTC_0X9A0201.GetEventStatus
        OpEventGetEventStatus_GetEventStatus_EvtInfo_DTC_0X9A031E: start-on-event=DemSatellite_0InternalBehavior/GetEventStatus, operation=EvtInfo_DTC_0X9A031E.GetEventStatus
        OpEventGetEventStatus_GetEventStatus_Event_DTC_0X9A031E: start-on-event=DemSatellite_0InternalBehavior/GetEventStatus, operation=Event_DTC_0X9A031E.GetEventStatus
        OpEventGetEventStatus_GetEventStatus_EvtInfo_DTC_0XC19988: start-on-event=DemSatellite_0InternalBehavior/GetEventStatus, operation=EvtInfo_DTC_0XC19988.GetEventStatus
        OpEventGetEventStatus_GetEventStatus_Event_DTC_0XC19988: start-on-event=DemSatellite_0InternalBehavior/GetEventStatus, operation=Event_DTC_0XC19988.GetEventStatus
        OpEventGetEventFailed_GetEventFailed_EvtInfo_DTC_0X9A0313: start-on-event=DemSatellite_0InternalBehavior/GetEventFailed, operation=EvtInfo_DTC_0X9A0313.GetEventFailed
        OpEventGetEventFailed_GetEventFailed_Event_DTC_0X9A0313: start-on-event=DemSatellite_0InternalBehavior/GetEventFailed, operation=Event_DTC_0X9A0313.GetEventFailed
        OpEventGetEventFailed_GetEventFailed_EvtInfo_DTC_0X9A0312: start-on-event=DemSatellite_0InternalBehavior/GetEventFailed, operation=EvtInfo_DTC_0X9A0312.GetEventFailed
        OpEventGetEventFailed_GetEventFailed_Event_DTC_0X9A0312: start-on-event=DemSatellite_0InternalBehavior/GetEventFailed, operation=Event_DTC_0X9A0312.GetEventFailed
        OpEventGetEventFailed_GetEventFailed_EvtInfo_DTC_0X9A0311: start-on-event=DemSatellite_0InternalBehavior/GetEventFailed, operation=EvtInfo_DTC_0X9A0311.GetEventFailed
        OpEventGetEventFailed_GetEventFailed_Event_DTC_0X9A0311: start-on-event=DemSatellite_0InternalBehavior/GetEventFailed, operation=Event_DTC_0X9A0311.GetEventFailed
        OpEventGetEventFailed_GetEventFailed_EvtInfo_DTC_0X9A0425: start-on-event=DemSatellite_0InternalBehavior/GetEventFailed, operation=EvtInfo_DTC_0X9A0425.GetEventFailed
        OpEventGetEventFailed_GetEventFailed_Event_DTC_0X9A0425: start-on-event=DemSatellite_0InternalBehavior/GetEventFailed, operation=Event_DTC_0X9A0425.GetEventFailed
        OpEventGetEventFailed_GetEventFailed_EvtInfo_DTC_0X925411: start-on-event=DemSatellite_0InternalBehavior/GetEventFailed, operation=EvtInfo_DTC_0X925411.GetEventFailed
        OpEventGetEventFailed_GetEventFailed_Event_DTC_0X925411: start-on-event=DemSatellite_0InternalBehavior/GetEventFailed, operation=Event_DTC_0X925411.GetEventFailed
        OpEventGetEventFailed_GetEventFailed_EvtInfo_DTC_0X909502: start-on-event=DemSatellite_0InternalBehavior/GetEventFailed, operation=EvtInfo_DTC_0X909502.GetEventFailed
        OpEventGetEventFailed_GetEventFailed_Event_DTC_0X909502: start-on-event=DemSatellite_0InternalBehavior/GetEventFailed, operation=Event_DTC_0X909502.GetEventFailed
        OpEventGetEventFailed_GetEventFailed_EvtInfo_DTC_0X9A0301: start-on-event=DemSatellite_0InternalBehavior/GetEventFailed, operation=EvtInfo_DTC_0X9A0301.GetEventFailed
        OpEventGetEventFailed_GetEventFailed_Event_DTC_0X9A0301: start-on-event=DemSatellite_0InternalBehavior/GetEventFailed, operation=Event_DTC_0X9A0301.GetEventFailed
        OpEventGetEventFailed_GetEventFailed_EvtInfo_DTC_0X9A041E: start-on-event=DemSatellite_0InternalBehavior/GetEventFailed, operation=EvtInfo_DTC_0X9A041E.GetEventFailed
        OpEventGetEventFailed_GetEventFailed_Event_DTC_0X9A041E: start-on-event=DemSatellite_0InternalBehavior/GetEventFailed, operation=Event_DTC_0X9A041E.GetEventFailed
        OpEventGetEventFailed_GetEventFailed_EvtInfo_DTC_0XC19887: start-on-event=DemSatellite_0InternalBehavior/GetEventFailed, operation=EvtInfo_DTC_0XC19887.GetEventFailed
        OpEventGetEventFailed_GetEventFailed_Event_DTC_0XC19887: start-on-event=DemSatellite_0InternalBehavior/GetEventFailed, operation=Event_DTC_0XC19887.GetEventFailed
        OpEventGetEventFailed_GetEventFailed_EvtInfo_DTC_0X9A0413: start-on-event=DemSatellite_0InternalBehavior/GetEventFailed, operation=EvtInfo_DTC_0X9A0413.GetEventFailed
        OpEventGetEventFailed_GetEventFailed_Event_DTC_0X9A0413: start-on-event=DemSatellite_0InternalBehavior/GetEventFailed, operation=Event_DTC_0X9A0413.GetEventFailed
        OpEventGetEventFailed_GetEventFailed_EvtInfo_DTC_0X9A0412: start-on-event=DemSatellite_0InternalBehavior/GetEventFailed, operation=EvtInfo_DTC_0X9A0412.GetEventFailed
        OpEventGetEventFailed_GetEventFailed_Event_DTC_0X9A0412: start-on-event=DemSatellite_0InternalBehavior/GetEventFailed, operation=Event_DTC_0X9A0412.GetEventFailed
        OpEventGetEventFailed_GetEventFailed_EvtInfo_DTC_0XC26402: start-on-event=DemSatellite_0InternalBehavior/GetEventFailed, operation=EvtInfo_DTC_0XC26402.GetEventFailed
        OpEventGetEventFailed_GetEventFailed_Event_DTC_0XC26402: start-on-event=DemSatellite_0InternalBehavior/GetEventFailed, operation=Event_DTC_0XC26402.GetEventFailed
        OpEventGetEventFailed_GetEventFailed_EvtInfo_DTC_0X9A0411: start-on-event=DemSatellite_0InternalBehavior/GetEventFailed, operation=EvtInfo_DTC_0X9A0411.GetEventFailed
        OpEventGetEventFailed_GetEventFailed_Event_DTC_0X9A0411: start-on-event=DemSatellite_0InternalBehavior/GetEventFailed, operation=Event_DTC_0X9A0411.GetEventFailed
        OpEventGetEventFailed_GetEventFailed_EvtInfo_DTC_0X9A0401: start-on-event=DemSatellite_0InternalBehavior/GetEventFailed, operation=EvtInfo_DTC_0X9A0401.GetEventFailed
        OpEventGetEventFailed_GetEventFailed_Event_DTC_0X9A0401: start-on-event=DemSatellite_0InternalBehavior/GetEventFailed, operation=Event_DTC_0X9A0401.GetEventFailed
        OpEventGetEventFailed_GetEventFailed_EvtInfo_DTC_0X93F611: start-on-event=DemSatellite_0InternalBehavior/GetEventFailed, operation=EvtInfo_DTC_0X93F611.GetEventFailed
        OpEventGetEventFailed_GetEventFailed_Event_DTC_0X93F611: start-on-event=DemSatellite_0InternalBehavior/GetEventFailed, operation=Event_DTC_0X93F611.GetEventFailed
        OpEventGetEventFailed_GetEventFailed_EvtInfo_DTC_0X923817: start-on-event=DemSatellite_0InternalBehavior/GetEventFailed, operation=EvtInfo_DTC_0X923817.GetEventFailed
        OpEventGetEventFailed_GetEventFailed_Event_DTC_0X923817: start-on-event=DemSatellite_0InternalBehavior/GetEventFailed, operation=Event_DTC_0X923817.GetEventFailed
        OpEventGetEventFailed_GetEventFailed_EvtInfo_DTC_0X923816: start-on-event=DemSatellite_0InternalBehavior/GetEventFailed, operation=EvtInfo_DTC_0X923816.GetEventFailed
        OpEventGetEventFailed_GetEventFailed_Event_DTC_0X923816: start-on-event=DemSatellite_0InternalBehavior/GetEventFailed, operation=Event_DTC_0X923816.GetEventFailed
        OpEventGetEventFailed_GetEventFailed_EvtInfo_DTC_0X93F613: start-on-event=DemSatellite_0InternalBehavior/GetEventFailed, operation=EvtInfo_DTC_0X93F613.GetEventFailed
        OpEventGetEventFailed_GetEventFailed_Event_DTC_0X93F613: start-on-event=DemSatellite_0InternalBehavior/GetEventFailed, operation=Event_DTC_0X93F613.GetEventFailed
        OpEventGetEventFailed_GetEventFailed_EvtInfo_DTC_0X925311: start-on-event=DemSatellite_0InternalBehavior/GetEventFailed, operation=EvtInfo_DTC_0X925311.GetEventFailed
        OpEventGetEventFailed_GetEventFailed_Event_DTC_0X925311: start-on-event=DemSatellite_0InternalBehavior/GetEventFailed, operation=Event_DTC_0X925311.GetEventFailed
        OpEventGetEventFailed_GetEventFailed_EvtInfo_DTC_0X93F612: start-on-event=DemSatellite_0InternalBehavior/GetEventFailed, operation=EvtInfo_DTC_0X93F612.GetEventFailed
        OpEventGetEventFailed_GetEventFailed_Event_DTC_0X93F612: start-on-event=DemSatellite_0InternalBehavior/GetEventFailed, operation=Event_DTC_0X93F612.GetEventFailed
        OpEventGetEventFailed_GetEventFailed_EvtInfo_DTC_0X9A0125: start-on-event=DemSatellite_0InternalBehavior/GetEventFailed, operation=EvtInfo_DTC_0X9A0125.GetEventFailed
        OpEventGetEventFailed_GetEventFailed_Event_DTC_0X9A0125: start-on-event=DemSatellite_0InternalBehavior/GetEventFailed, operation=Event_DTC_0X9A0125.GetEventFailed
        OpEventGetEventFailed_GetEventFailed_EvtInfo_DTC_0XC15502: start-on-event=DemSatellite_0InternalBehavior/GetEventFailed, operation=EvtInfo_DTC_0XC15502.GetEventFailed
        OpEventGetEventFailed_GetEventFailed_Event_DTC_0XC15502: start-on-event=DemSatellite_0InternalBehavior/GetEventFailed, operation=Event_DTC_0XC15502.GetEventFailed
        OpEventGetEventFailed_GetEventFailed_EvtInfo_DTC_0X9A011E: start-on-event=DemSatellite_0InternalBehavior/GetEventFailed, operation=EvtInfo_DTC_0X9A011E.GetEventFailed
        OpEventGetEventFailed_GetEventFailed_Event_DTC_0X9A011E: start-on-event=DemSatellite_0InternalBehavior/GetEventFailed, operation=Event_DTC_0X9A011E.GetEventFailed
        OpEventGetEventFailed_GetEventFailed_EvtInfo_DTC_0XC15582: start-on-event=DemSatellite_0InternalBehavior/GetEventFailed, operation=EvtInfo_DTC_0XC15582.GetEventFailed
        OpEventGetEventFailed_GetEventFailed_Event_DTC_0XC15582: start-on-event=DemSatellite_0InternalBehavior/GetEventFailed, operation=Event_DTC_0XC15582.GetEventFailed
        OpEventGetEventFailed_GetEventFailed_EvtInfo_DTC_0XC01988: start-on-event=DemSatellite_0InternalBehavior/GetEventFailed, operation=EvtInfo_DTC_0XC01988.GetEventFailed
        OpEventGetEventFailed_GetEventFailed_Event_DTC_0XC01988: start-on-event=DemSatellite_0InternalBehavior/GetEventFailed, operation=Event_DTC_0XC01988.GetEventFailed
        OpEventGetEventFailed_GetEventFailed_EvtInfo_DTC_0X9A0112: start-on-event=DemSatellite_0InternalBehavior/GetEventFailed, operation=EvtInfo_DTC_0X9A0112.GetEventFailed
        OpEventGetEventFailed_GetEventFailed_Event_DTC_0X9A0112: start-on-event=DemSatellite_0InternalBehavior/GetEventFailed, operation=Event_DTC_0X9A0112.GetEventFailed
        OpEventGetEventFailed_GetEventFailed_EvtInfo_DTC_0X919F11: start-on-event=DemSatellite_0InternalBehavior/GetEventFailed, operation=EvtInfo_DTC_0X919F11.GetEventFailed
        OpEventGetEventFailed_GetEventFailed_Event_DTC_0X919F11: start-on-event=DemSatellite_0InternalBehavior/GetEventFailed, operation=Event_DTC_0X919F11.GetEventFailed
        OpEventGetEventFailed_GetEventFailed_EvtInfo_DTC_0X9A0111: start-on-event=DemSatellite_0InternalBehavior/GetEventFailed, operation=EvtInfo_DTC_0X9A0111.GetEventFailed
        OpEventGetEventFailed_GetEventFailed_Event_DTC_0X9A0111: start-on-event=DemSatellite_0InternalBehavior/GetEventFailed, operation=Event_DTC_0X9A0111.GetEventFailed
        OpEventGetEventFailed_GetEventFailed_EvtInfo_DTC_0X919F12: start-on-event=DemSatellite_0InternalBehavior/GetEventFailed, operation=EvtInfo_DTC_0X919F12.GetEventFailed
        OpEventGetEventFailed_GetEventFailed_Event_DTC_0X919F12: start-on-event=DemSatellite_0InternalBehavior/GetEventFailed, operation=Event_DTC_0X919F12.GetEventFailed
        OpEventGetEventFailed_GetEventFailed_EvtInfo_DTC_0X919F13: start-on-event=DemSatellite_0InternalBehavior/GetEventFailed, operation=EvtInfo_DTC_0X919F13.GetEventFailed
        OpEventGetEventFailed_GetEventFailed_Event_DTC_0X919F13: start-on-event=DemSatellite_0InternalBehavior/GetEventFailed, operation=Event_DTC_0X919F13.GetEventFailed
        OpEventGetEventFailed_GetEventFailed_EvtInfo_DTC_0X9A0113: start-on-event=DemSatellite_0InternalBehavior/GetEventFailed, operation=EvtInfo_DTC_0X9A0113.GetEventFailed
        OpEventGetEventFailed_GetEventFailed_Event_DTC_0X9A0113: start-on-event=DemSatellite_0InternalBehavior/GetEventFailed, operation=Event_DTC_0X9A0113.GetEventFailed
        OpEventGetEventFailed_GetEventFailed_EvtInfo_DTC_0XC14687: start-on-event=DemSatellite_0InternalBehavior/GetEventFailed, operation=EvtInfo_DTC_0XC14687.GetEventFailed
        OpEventGetEventFailed_GetEventFailed_Event_DTC_0XC14687: start-on-event=DemSatellite_0InternalBehavior/GetEventFailed, operation=Event_DTC_0XC14687.GetEventFailed
        OpEventGetEventFailed_GetEventFailed_EvtInfo_DTC_0X91BA63: start-on-event=DemSatellite_0InternalBehavior/GetEventFailed, operation=EvtInfo_DTC_0X91BA63.GetEventFailed
        OpEventGetEventFailed_GetEventFailed_Event_DTC_0X91BA63: start-on-event=DemSatellite_0InternalBehavior/GetEventFailed, operation=Event_DTC_0X91BA63.GetEventFailed
        OpEventGetEventFailed_GetEventFailed_EvtInfo_DTC_0X9A0225: start-on-event=DemSatellite_0InternalBehavior/GetEventFailed, operation=EvtInfo_DTC_0X9A0225.GetEventFailed
        OpEventGetEventFailed_GetEventFailed_Event_DTC_0X9A0225: start-on-event=DemSatellite_0InternalBehavior/GetEventFailed, operation=Event_DTC_0X9A0225.GetEventFailed
        OpEventGetEventFailed_GetEventFailed_EvtInfo_DTC_0XD10017: start-on-event=DemSatellite_0InternalBehavior/GetEventFailed, operation=EvtInfo_DTC_0XD10017.GetEventFailed
        OpEventGetEventFailed_GetEventFailed_Event_DTC_0XD10017: start-on-event=DemSatellite_0InternalBehavior/GetEventFailed, operation=Event_DTC_0XD10017.GetEventFailed
        OpEventGetEventFailed_GetEventFailed_EvtInfo_DTC_0X93F512: start-on-event=DemSatellite_0InternalBehavior/GetEventFailed, operation=EvtInfo_DTC_0X93F512.GetEventFailed
        OpEventGetEventFailed_GetEventFailed_Event_DTC_0X93F512: start-on-event=DemSatellite_0InternalBehavior/GetEventFailed, operation=Event_DTC_0X93F512.GetEventFailed
        OpEventGetEventFailed_GetEventFailed_EvtInfo_DTC_0X93F511: start-on-event=DemSatellite_0InternalBehavior/GetEventFailed, operation=EvtInfo_DTC_0X93F511.GetEventFailed
        OpEventGetEventFailed_GetEventFailed_Event_DTC_0X93F511: start-on-event=DemSatellite_0InternalBehavior/GetEventFailed, operation=Event_DTC_0X93F511.GetEventFailed
        OpEventGetEventFailed_GetEventFailed_EvtInfo_DTC_0X925211: start-on-event=DemSatellite_0InternalBehavior/GetEventFailed, operation=EvtInfo_DTC_0X925211.GetEventFailed
        OpEventGetEventFailed_GetEventFailed_Event_DTC_0X925211: start-on-event=DemSatellite_0InternalBehavior/GetEventFailed, operation=Event_DTC_0X925211.GetEventFailed
        OpEventGetEventFailed_GetEventFailed_EvtInfo_DTC_0X93F513: start-on-event=DemSatellite_0InternalBehavior/GetEventFailed, operation=EvtInfo_DTC_0X93F513.GetEventFailed
        OpEventGetEventFailed_GetEventFailed_Event_DTC_0X93F513: start-on-event=DemSatellite_0InternalBehavior/GetEventFailed, operation=Event_DTC_0X93F513.GetEventFailed
        OpEventGetEventFailed_GetEventFailed_EvtInfo_DTC_0X9A0101: start-on-event=DemSatellite_0InternalBehavior/GetEventFailed, operation=EvtInfo_DTC_0X9A0101.GetEventFailed
        OpEventGetEventFailed_GetEventFailed_Event_DTC_0X9A0101: start-on-event=DemSatellite_0InternalBehavior/GetEventFailed, operation=Event_DTC_0X9A0101.GetEventFailed
        OpEventGetEventFailed_GetEventFailed_EvtInfo_DTC_0X9A021E: start-on-event=DemSatellite_0InternalBehavior/GetEventFailed, operation=EvtInfo_DTC_0X9A021E.GetEventFailed
        OpEventGetEventFailed_GetEventFailed_Event_DTC_0X9A021E: start-on-event=DemSatellite_0InternalBehavior/GetEventFailed, operation=Event_DTC_0X9A021E.GetEventFailed
        OpEventGetEventFailed_GetEventFailed_EvtInfo_DTC_0XA10604: start-on-event=DemSatellite_0InternalBehavior/GetEventFailed, operation=EvtInfo_DTC_0XA10604.GetEventFailed
        OpEventGetEventFailed_GetEventFailed_Event_DTC_0XA10604: start-on-event=DemSatellite_0InternalBehavior/GetEventFailed, operation=Event_DTC_0XA10604.GetEventFailed
        OpEventGetEventFailed_GetEventFailed_EvtInfo_DTC_0XA10602: start-on-event=DemSatellite_0InternalBehavior/GetEventFailed, operation=EvtInfo_DTC_0XA10602.GetEventFailed
        OpEventGetEventFailed_GetEventFailed_Event_DTC_0XA10602: start-on-event=DemSatellite_0InternalBehavior/GetEventFailed, operation=Event_DTC_0XA10602.GetEventFailed
        OpEventGetEventFailed_GetEventFailed_EvtInfo_DTC_0X908E87: start-on-event=DemSatellite_0InternalBehavior/GetEventFailed, operation=EvtInfo_DTC_0X908E87.GetEventFailed
        OpEventGetEventFailed_GetEventFailed_Event_DTC_0X908E87: start-on-event=DemSatellite_0InternalBehavior/GetEventFailed, operation=Event_DTC_0X908E87.GetEventFailed
        OpEventGetEventFailed_GetEventFailed_EvtInfo_DTC_0X9A0211: start-on-event=DemSatellite_0InternalBehavior/GetEventFailed, operation=EvtInfo_DTC_0X9A0211.GetEventFailed
        OpEventGetEventFailed_GetEventFailed_Event_DTC_0X9A0211: start-on-event=DemSatellite_0InternalBehavior/GetEventFailed, operation=Event_DTC_0X9A0211.GetEventFailed
        OpEventGetEventFailed_GetEventFailed_EvtInfo_DTC_0X9A0213: start-on-event=DemSatellite_0InternalBehavior/GetEventFailed, operation=EvtInfo_DTC_0X9A0213.GetEventFailed
        OpEventGetEventFailed_GetEventFailed_Event_DTC_0X9A0213: start-on-event=DemSatellite_0InternalBehavior/GetEventFailed, operation=Event_DTC_0X9A0213.GetEventFailed
        OpEventGetEventFailed_GetEventFailed_EvtInfo_DTC_0X9A0212: start-on-event=DemSatellite_0InternalBehavior/GetEventFailed, operation=EvtInfo_DTC_0X9A0212.GetEventFailed
        OpEventGetEventFailed_GetEventFailed_Event_DTC_0X9A0212: start-on-event=DemSatellite_0InternalBehavior/GetEventFailed, operation=Event_DTC_0X9A0212.GetEventFailed
        OpEventGetEventFailed_GetEventFailed_EvtInfo_DTC_0XA11204: start-on-event=DemSatellite_0InternalBehavior/GetEventFailed, operation=EvtInfo_DTC_0XA11204.GetEventFailed
        OpEventGetEventFailed_GetEventFailed_Event_DTC_0XA11204: start-on-event=DemSatellite_0InternalBehavior/GetEventFailed, operation=Event_DTC_0XA11204.GetEventFailed
        OpEventGetEventFailed_GetEventFailed_EvtInfo_DTC_0X9A0325: start-on-event=DemSatellite_0InternalBehavior/GetEventFailed, operation=EvtInfo_DTC_0X9A0325.GetEventFailed
        OpEventGetEventFailed_GetEventFailed_Event_DTC_0X9A0325: start-on-event=DemSatellite_0InternalBehavior/GetEventFailed, operation=Event_DTC_0X9A0325.GetEventFailed
        OpEventGetEventFailed_GetEventFailed_EvtInfo_DTC_0XD10116: start-on-event=DemSatellite_0InternalBehavior/GetEventFailed, operation=EvtInfo_DTC_0XD10116.GetEventFailed
        OpEventGetEventFailed_GetEventFailed_Event_DTC_0XD10116: start-on-event=DemSatellite_0InternalBehavior/GetEventFailed, operation=Event_DTC_0XD10116.GetEventFailed
        OpEventGetEventFailed_GetEventFailed_EvtInfo_DTC_0X909602: start-on-event=DemSatellite_0InternalBehavior/GetEventFailed, operation=EvtInfo_DTC_0X909602.GetEventFailed
        OpEventGetEventFailed_GetEventFailed_Event_DTC_0X909602: start-on-event=DemSatellite_0InternalBehavior/GetEventFailed, operation=Event_DTC_0X909602.GetEventFailed
        OpEventGetEventFailed_GetEventFailed_EvtInfo_DTC_0X9A0201: start-on-event=DemSatellite_0InternalBehavior/GetEventFailed, operation=EvtInfo_DTC_0X9A0201.GetEventFailed
        OpEventGetEventFailed_GetEventFailed_Event_DTC_0X9A0201: start-on-event=DemSatellite_0InternalBehavior/GetEventFailed, operation=Event_DTC_0X9A0201.GetEventFailed
        OpEventGetEventFailed_GetEventFailed_EvtInfo_DTC_0X9A031E: start-on-event=DemSatellite_0InternalBehavior/GetEventFailed, operation=EvtInfo_DTC_0X9A031E.GetEventFailed
        OpEventGetEventFailed_GetEventFailed_Event_DTC_0X9A031E: start-on-event=DemSatellite_0InternalBehavior/GetEventFailed, operation=Event_DTC_0X9A031E.GetEventFailed
        OpEventGetEventFailed_GetEventFailed_EvtInfo_DTC_0XC19988: start-on-event=DemSatellite_0InternalBehavior/GetEventFailed, operation=EvtInfo_DTC_0XC19988.GetEventFailed
        OpEventGetEventFailed_GetEventFailed_Event_DTC_0XC19988: start-on-event=DemSatellite_0InternalBehavior/GetEventFailed, operation=Event_DTC_0XC19988.GetEventFailed
        OpEventGetEventTested_GetEventTested_EvtInfo_DTC_0X9A0313: start-on-event=DemSatellite_0InternalBehavior/GetEventTested, operation=EvtInfo_DTC_0X9A0313.GetEventTested
        OpEventGetEventTested_GetEventTested_Event_DTC_0X9A0313: start-on-event=DemSatellite_0InternalBehavior/GetEventTested, operation=Event_DTC_0X9A0313.GetEventTested
        OpEventGetEventTested_GetEventTested_EvtInfo_DTC_0X9A0312: start-on-event=DemSatellite_0InternalBehavior/GetEventTested, operation=EvtInfo_DTC_0X9A0312.GetEventTested
        OpEventGetEventTested_GetEventTested_Event_DTC_0X9A0312: start-on-event=DemSatellite_0InternalBehavior/GetEventTested, operation=Event_DTC_0X9A0312.GetEventTested
        OpEventGetEventTested_GetEventTested_EvtInfo_DTC_0X9A0311: start-on-event=DemSatellite_0InternalBehavior/GetEventTested, operation=EvtInfo_DTC_0X9A0311.GetEventTested
        OpEventGetEventTested_GetEventTested_Event_DTC_0X9A0311: start-on-event=DemSatellite_0InternalBehavior/GetEventTested, operation=Event_DTC_0X9A0311.GetEventTested
        OpEventGetEventTested_GetEventTested_EvtInfo_DTC_0X9A0425: start-on-event=DemSatellite_0InternalBehavior/GetEventTested, operation=EvtInfo_DTC_0X9A0425.GetEventTested
        OpEventGetEventTested_GetEventTested_Event_DTC_0X9A0425: start-on-event=DemSatellite_0InternalBehavior/GetEventTested, operation=Event_DTC_0X9A0425.GetEventTested
        OpEventGetEventTested_GetEventTested_EvtInfo_DTC_0X925411: start-on-event=DemSatellite_0InternalBehavior/GetEventTested, operation=EvtInfo_DTC_0X925411.GetEventTested
        OpEventGetEventTested_GetEventTested_Event_DTC_0X925411: start-on-event=DemSatellite_0InternalBehavior/GetEventTested, operation=Event_DTC_0X925411.GetEventTested
        OpEventGetEventTested_GetEventTested_EvtInfo_DTC_0X909502: start-on-event=DemSatellite_0InternalBehavior/GetEventTested, operation=EvtInfo_DTC_0X909502.GetEventTested
        OpEventGetEventTested_GetEventTested_Event_DTC_0X909502: start-on-event=DemSatellite_0InternalBehavior/GetEventTested, operation=Event_DTC_0X909502.GetEventTested
        OpEventGetEventTested_GetEventTested_EvtInfo_DTC_0X9A0301: start-on-event=DemSatellite_0InternalBehavior/GetEventTested, operation=EvtInfo_DTC_0X9A0301.GetEventTested
        OpEventGetEventTested_GetEventTested_Event_DTC_0X9A0301: start-on-event=DemSatellite_0InternalBehavior/GetEventTested, operation=Event_DTC_0X9A0301.GetEventTested
        OpEventGetEventTested_GetEventTested_EvtInfo_DTC_0X9A041E: start-on-event=DemSatellite_0InternalBehavior/GetEventTested, operation=EvtInfo_DTC_0X9A041E.GetEventTested
        OpEventGetEventTested_GetEventTested_Event_DTC_0X9A041E: start-on-event=DemSatellite_0InternalBehavior/GetEventTested, operation=Event_DTC_0X9A041E.GetEventTested
        OpEventGetEventTested_GetEventTested_EvtInfo_DTC_0XC19887: start-on-event=DemSatellite_0InternalBehavior/GetEventTested, operation=EvtInfo_DTC_0XC19887.GetEventTested
        OpEventGetEventTested_GetEventTested_Event_DTC_0XC19887: start-on-event=DemSatellite_0InternalBehavior/GetEventTested, operation=Event_DTC_0XC19887.GetEventTested
        OpEventGetEventTested_GetEventTested_EvtInfo_DTC_0X9A0413: start-on-event=DemSatellite_0InternalBehavior/GetEventTested, operation=EvtInfo_DTC_0X9A0413.GetEventTested
        OpEventGetEventTested_GetEventTested_Event_DTC_0X9A0413: start-on-event=DemSatellite_0InternalBehavior/GetEventTested, operation=Event_DTC_0X9A0413.GetEventTested
        OpEventGetEventTested_GetEventTested_EvtInfo_DTC_0X9A0412: start-on-event=DemSatellite_0InternalBehavior/GetEventTested, operation=EvtInfo_DTC_0X9A0412.GetEventTested
        OpEventGetEventTested_GetEventTested_Event_DTC_0X9A0412: start-on-event=DemSatellite_0InternalBehavior/GetEventTested, operation=Event_DTC_0X9A0412.GetEventTested
        OpEventGetEventTested_GetEventTested_EvtInfo_DTC_0XC26402: start-on-event=DemSatellite_0InternalBehavior/GetEventTested, operation=EvtInfo_DTC_0XC26402.GetEventTested
        OpEventGetEventTested_GetEventTested_Event_DTC_0XC26402: start-on-event=DemSatellite_0InternalBehavior/GetEventTested, operation=Event_DTC_0XC26402.GetEventTested
        OpEventGetEventTested_GetEventTested_EvtInfo_DTC_0X9A0411: start-on-event=DemSatellite_0InternalBehavior/GetEventTested, operation=EvtInfo_DTC_0X9A0411.GetEventTested
        OpEventGetEventTested_GetEventTested_Event_DTC_0X9A0411: start-on-event=DemSatellite_0InternalBehavior/GetEventTested, operation=Event_DTC_0X9A0411.GetEventTested
        OpEventGetEventTested_GetEventTested_EvtInfo_DTC_0X9A0401: start-on-event=DemSatellite_0InternalBehavior/GetEventTested, operation=EvtInfo_DTC_0X9A0401.GetEventTested
        OpEventGetEventTested_GetEventTested_Event_DTC_0X9A0401: start-on-event=DemSatellite_0InternalBehavior/GetEventTested, operation=Event_DTC_0X9A0401.GetEventTested
        OpEventGetEventTested_GetEventTested_EvtInfo_DTC_0X93F611: start-on-event=DemSatellite_0InternalBehavior/GetEventTested, operation=EvtInfo_DTC_0X93F611.GetEventTested
        OpEventGetEventTested_GetEventTested_Event_DTC_0X93F611: start-on-event=DemSatellite_0InternalBehavior/GetEventTested, operation=Event_DTC_0X93F611.GetEventTested
        OpEventGetEventTested_GetEventTested_EvtInfo_DTC_0X923817: start-on-event=DemSatellite_0InternalBehavior/GetEventTested, operation=EvtInfo_DTC_0X923817.GetEventTested
        OpEventGetEventTested_GetEventTested_Event_DTC_0X923817: start-on-event=DemSatellite_0InternalBehavior/GetEventTested, operation=Event_DTC_0X923817.GetEventTested
        OpEventGetEventTested_GetEventTested_EvtInfo_DTC_0X923816: start-on-event=DemSatellite_0InternalBehavior/GetEventTested, operation=EvtInfo_DTC_0X923816.GetEventTested
        OpEventGetEventTested_GetEventTested_Event_DTC_0X923816: start-on-event=DemSatellite_0InternalBehavior/GetEventTested, operation=Event_DTC_0X923816.GetEventTested
        OpEventGetEventTested_GetEventTested_EvtInfo_DTC_0X93F613: start-on-event=DemSatellite_0InternalBehavior/GetEventTested, operation=EvtInfo_DTC_0X93F613.GetEventTested
        OpEventGetEventTested_GetEventTested_Event_DTC_0X93F613: start-on-event=DemSatellite_0InternalBehavior/GetEventTested, operation=Event_DTC_0X93F613.GetEventTested
        OpEventGetEventTested_GetEventTested_EvtInfo_DTC_0X925311: start-on-event=DemSatellite_0InternalBehavior/GetEventTested, operation=EvtInfo_DTC_0X925311.GetEventTested
        OpEventGetEventTested_GetEventTested_Event_DTC_0X925311: start-on-event=DemSatellite_0InternalBehavior/GetEventTested, operation=Event_DTC_0X925311.GetEventTested
        OpEventGetEventTested_GetEventTested_EvtInfo_DTC_0X93F612: start-on-event=DemSatellite_0InternalBehavior/GetEventTested, operation=EvtInfo_DTC_0X93F612.GetEventTested
        OpEventGetEventTested_GetEventTested_Event_DTC_0X93F612: start-on-event=DemSatellite_0InternalBehavior/GetEventTested, operation=Event_DTC_0X93F612.GetEventTested
        OpEventGetEventTested_GetEventTested_EvtInfo_DTC_0X9A0125: start-on-event=DemSatellite_0InternalBehavior/GetEventTested, operation=EvtInfo_DTC_0X9A0125.GetEventTested
        OpEventGetEventTested_GetEventTested_Event_DTC_0X9A0125: start-on-event=DemSatellite_0InternalBehavior/GetEventTested, operation=Event_DTC_0X9A0125.GetEventTested
        OpEventGetEventTested_GetEventTested_EvtInfo_DTC_0XC15502: start-on-event=DemSatellite_0InternalBehavior/GetEventTested, operation=EvtInfo_DTC_0XC15502.GetEventTested
        OpEventGetEventTested_GetEventTested_Event_DTC_0XC15502: start-on-event=DemSatellite_0InternalBehavior/GetEventTested, operation=Event_DTC_0XC15502.GetEventTested
        OpEventGetEventTested_GetEventTested_EvtInfo_DTC_0X9A011E: start-on-event=DemSatellite_0InternalBehavior/GetEventTested, operation=EvtInfo_DTC_0X9A011E.GetEventTested
        OpEventGetEventTested_GetEventTested_Event_DTC_0X9A011E: start-on-event=DemSatellite_0InternalBehavior/GetEventTested, operation=Event_DTC_0X9A011E.GetEventTested
        OpEventGetEventTested_GetEventTested_EvtInfo_DTC_0XC15582: start-on-event=DemSatellite_0InternalBehavior/GetEventTested, operation=EvtInfo_DTC_0XC15582.GetEventTested
        OpEventGetEventTested_GetEventTested_Event_DTC_0XC15582: start-on-event=DemSatellite_0InternalBehavior/GetEventTested, operation=Event_DTC_0XC15582.GetEventTested
        OpEventGetEventTested_GetEventTested_EvtInfo_DTC_0XC01988: start-on-event=DemSatellite_0InternalBehavior/GetEventTested, operation=EvtInfo_DTC_0XC01988.GetEventTested
        OpEventGetEventTested_GetEventTested_Event_DTC_0XC01988: start-on-event=DemSatellite_0InternalBehavior/GetEventTested, operation=Event_DTC_0XC01988.GetEventTested
        OpEventGetEventTested_GetEventTested_EvtInfo_DTC_0X9A0112: start-on-event=DemSatellite_0InternalBehavior/GetEventTested, operation=EvtInfo_DTC_0X9A0112.GetEventTested
        OpEventGetEventTested_GetEventTested_Event_DTC_0X9A0112: start-on-event=DemSatellite_0InternalBehavior/GetEventTested, operation=Event_DTC_0X9A0112.GetEventTested
        OpEventGetEventTested_GetEventTested_EvtInfo_DTC_0X919F11: start-on-event=DemSatellite_0InternalBehavior/GetEventTested, operation=EvtInfo_DTC_0X919F11.GetEventTested
        OpEventGetEventTested_GetEventTested_Event_DTC_0X919F11: start-on-event=DemSatellite_0InternalBehavior/GetEventTested, operation=Event_DTC_0X919F11.GetEventTested
        OpEventGetEventTested_GetEventTested_EvtInfo_DTC_0X9A0111: start-on-event=DemSatellite_0InternalBehavior/GetEventTested, operation=EvtInfo_DTC_0X9A0111.GetEventTested
        OpEventGetEventTested_GetEventTested_Event_DTC_0X9A0111: start-on-event=DemSatellite_0InternalBehavior/GetEventTested, operation=Event_DTC_0X9A0111.GetEventTested
        OpEventGetEventTested_GetEventTested_EvtInfo_DTC_0X919F12: start-on-event=DemSatellite_0InternalBehavior/GetEventTested, operation=EvtInfo_DTC_0X919F12.GetEventTested
        OpEventGetEventTested_GetEventTested_Event_DTC_0X919F12: start-on-event=DemSatellite_0InternalBehavior/GetEventTested, operation=Event_DTC_0X919F12.GetEventTested
        OpEventGetEventTested_GetEventTested_EvtInfo_DTC_0X919F13: start-on-event=DemSatellite_0InternalBehavior/GetEventTested, operation=EvtInfo_DTC_0X919F13.GetEventTested
        OpEventGetEventTested_GetEventTested_Event_DTC_0X919F13: start-on-event=DemSatellite_0InternalBehavior/GetEventTested, operation=Event_DTC_0X919F13.GetEventTested
        OpEventGetEventTested_GetEventTested_EvtInfo_DTC_0X9A0113: start-on-event=DemSatellite_0InternalBehavior/GetEventTested, operation=EvtInfo_DTC_0X9A0113.GetEventTested
        OpEventGetEventTested_GetEventTested_Event_DTC_0X9A0113: start-on-event=DemSatellite_0InternalBehavior/GetEventTested, operation=Event_DTC_0X9A0113.GetEventTested
        OpEventGetEventTested_GetEventTested_EvtInfo_DTC_0XC14687: start-on-event=DemSatellite_0InternalBehavior/GetEventTested, operation=EvtInfo_DTC_0XC14687.GetEventTested
        OpEventGetEventTested_GetEventTested_Event_DTC_0XC14687: start-on-event=DemSatellite_0InternalBehavior/GetEventTested, operation=Event_DTC_0XC14687.GetEventTested
        OpEventGetEventTested_GetEventTested_EvtInfo_DTC_0X91BA63: start-on-event=DemSatellite_0InternalBehavior/GetEventTested, operation=EvtInfo_DTC_0X91BA63.GetEventTested
        OpEventGetEventTested_GetEventTested_Event_DTC_0X91BA63: start-on-event=DemSatellite_0InternalBehavior/GetEventTested, operation=Event_DTC_0X91BA63.GetEventTested
        OpEventGetEventTested_GetEventTested_EvtInfo_DTC_0X9A0225: start-on-event=DemSatellite_0InternalBehavior/GetEventTested, operation=EvtInfo_DTC_0X9A0225.GetEventTested
        OpEventGetEventTested_GetEventTested_Event_DTC_0X9A0225: start-on-event=DemSatellite_0InternalBehavior/GetEventTested, operation=Event_DTC_0X9A0225.GetEventTested
        OpEventGetEventTested_GetEventTested_EvtInfo_DTC_0XD10017: start-on-event=DemSatellite_0InternalBehavior/GetEventTested, operation=EvtInfo_DTC_0XD10017.GetEventTested
        OpEventGetEventTested_GetEventTested_Event_DTC_0XD10017: start-on-event=DemSatellite_0InternalBehavior/GetEventTested, operation=Event_DTC_0XD10017.GetEventTested
        OpEventGetEventTested_GetEventTested_EvtInfo_DTC_0X93F512: start-on-event=DemSatellite_0InternalBehavior/GetEventTested, operation=EvtInfo_DTC_0X93F512.GetEventTested
        OpEventGetEventTested_GetEventTested_Event_DTC_0X93F512: start-on-event=DemSatellite_0InternalBehavior/GetEventTested, operation=Event_DTC_0X93F512.GetEventTested
        OpEventGetEventTested_GetEventTested_EvtInfo_DTC_0X93F511: start-on-event=DemSatellite_0InternalBehavior/GetEventTested, operation=EvtInfo_DTC_0X93F511.GetEventTested
        OpEventGetEventTested_GetEventTested_Event_DTC_0X93F511: start-on-event=DemSatellite_0InternalBehavior/GetEventTested, operation=Event_DTC_0X93F511.GetEventTested
        OpEventGetEventTested_GetEventTested_EvtInfo_DTC_0X925211: start-on-event=DemSatellite_0InternalBehavior/GetEventTested, operation=EvtInfo_DTC_0X925211.GetEventTested
        OpEventGetEventTested_GetEventTested_Event_DTC_0X925211: start-on-event=DemSatellite_0InternalBehavior/GetEventTested, operation=Event_DTC_0X925211.GetEventTested
        OpEventGetEventTested_GetEventTested_EvtInfo_DTC_0X93F513: start-on-event=DemSatellite_0InternalBehavior/GetEventTested, operation=EvtInfo_DTC_0X93F513.GetEventTested
        OpEventGetEventTested_GetEventTested_Event_DTC_0X93F513: start-on-event=DemSatellite_0InternalBehavior/GetEventTested, operation=Event_DTC_0X93F513.GetEventTested
        OpEventGetEventTested_GetEventTested_EvtInfo_DTC_0X9A0101: start-on-event=DemSatellite_0InternalBehavior/GetEventTested, operation=EvtInfo_DTC_0X9A0101.GetEventTested
        OpEventGetEventTested_GetEventTested_Event_DTC_0X9A0101: start-on-event=DemSatellite_0InternalBehavior/GetEventTested, operation=Event_DTC_0X9A0101.GetEventTested
        OpEventGetEventTested_GetEventTested_EvtInfo_DTC_0X9A021E: start-on-event=DemSatellite_0InternalBehavior/GetEventTested, operation=EvtInfo_DTC_0X9A021E.GetEventTested
        OpEventGetEventTested_GetEventTested_Event_DTC_0X9A021E: start-on-event=DemSatellite_0InternalBehavior/GetEventTested, operation=Event_DTC_0X9A021E.GetEventTested
        OpEventGetEventTested_GetEventTested_EvtInfo_DTC_0XA10604: start-on-event=DemSatellite_0InternalBehavior/GetEventTested, operation=EvtInfo_DTC_0XA10604.GetEventTested
        OpEventGetEventTested_GetEventTested_Event_DTC_0XA10604: start-on-event=DemSatellite_0InternalBehavior/GetEventTested, operation=Event_DTC_0XA10604.GetEventTested
        OpEventGetEventTested_GetEventTested_EvtInfo_DTC_0XA10602: start-on-event=DemSatellite_0InternalBehavior/GetEventTested, operation=EvtInfo_DTC_0XA10602.GetEventTested
        OpEventGetEventTested_GetEventTested_Event_DTC_0XA10602: start-on-event=DemSatellite_0InternalBehavior/GetEventTested, operation=Event_DTC_0XA10602.GetEventTested
        OpEventGetEventTested_GetEventTested_EvtInfo_DTC_0X908E87: start-on-event=DemSatellite_0InternalBehavior/GetEventTested, operation=EvtInfo_DTC_0X908E87.GetEventTested
        OpEventGetEventTested_GetEventTested_Event_DTC_0X908E87: start-on-event=DemSatellite_0InternalBehavior/GetEventTested, operation=Event_DTC_0X908E87.GetEventTested
        OpEventGetEventTested_GetEventTested_EvtInfo_DTC_0X9A0211: start-on-event=DemSatellite_0InternalBehavior/GetEventTested, operation=EvtInfo_DTC_0X9A0211.GetEventTested
        OpEventGetEventTested_GetEventTested_Event_DTC_0X9A0211: start-on-event=DemSatellite_0InternalBehavior/GetEventTested, operation=Event_DTC_0X9A0211.GetEventTested
        OpEventGetEventTested_GetEventTested_EvtInfo_DTC_0X9A0213: start-on-event=DemSatellite_0InternalBehavior/GetEventTested, operation=EvtInfo_DTC_0X9A0213.GetEventTested
        OpEventGetEventTested_GetEventTested_Event_DTC_0X9A0213: start-on-event=DemSatellite_0InternalBehavior/GetEventTested, operation=Event_DTC_0X9A0213.GetEventTested
        OpEventGetEventTested_GetEventTested_EvtInfo_DTC_0X9A0212: start-on-event=DemSatellite_0InternalBehavior/GetEventTested, operation=EvtInfo_DTC_0X9A0212.GetEventTested
        OpEventGetEventTested_GetEventTested_Event_DTC_0X9A0212: start-on-event=DemSatellite_0InternalBehavior/GetEventTested, operation=Event_DTC_0X9A0212.GetEventTested
        OpEventGetEventTested_GetEventTested_EvtInfo_DTC_0XA11204: start-on-event=DemSatellite_0InternalBehavior/GetEventTested, operation=EvtInfo_DTC_0XA11204.GetEventTested
        OpEventGetEventTested_GetEventTested_Event_DTC_0XA11204: start-on-event=DemSatellite_0InternalBehavior/GetEventTested, operation=Event_DTC_0XA11204.GetEventTested
        OpEventGetEventTested_GetEventTested_EvtInfo_DTC_0X9A0325: start-on-event=DemSatellite_0InternalBehavior/GetEventTested, operation=EvtInfo_DTC_0X9A0325.GetEventTested
        OpEventGetEventTested_GetEventTested_Event_DTC_0X9A0325: start-on-event=DemSatellite_0InternalBehavior/GetEventTested, operation=Event_DTC_0X9A0325.GetEventTested
        OpEventGetEventTested_GetEventTested_EvtInfo_DTC_0XD10116: start-on-event=DemSatellite_0InternalBehavior/GetEventTested, operation=EvtInfo_DTC_0XD10116.GetEventTested
        OpEventGetEventTested_GetEventTested_Event_DTC_0XD10116: start-on-event=DemSatellite_0InternalBehavior/GetEventTested, operation=Event_DTC_0XD10116.GetEventTested
        OpEventGetEventTested_GetEventTested_EvtInfo_DTC_0X909602: start-on-event=DemSatellite_0InternalBehavior/GetEventTested, operation=EvtInfo_DTC_0X909602.GetEventTested
        OpEventGetEventTested_GetEventTested_Event_DTC_0X909602: start-on-event=DemSatellite_0InternalBehavior/GetEventTested, operation=Event_DTC_0X909602.GetEventTested
        OpEventGetEventTested_GetEventTested_EvtInfo_DTC_0X9A0201: start-on-event=DemSatellite_0InternalBehavior/GetEventTested, operation=EvtInfo_DTC_0X9A0201.GetEventTested
        OpEventGetEventTested_GetEventTested_Event_DTC_0X9A0201: start-on-event=DemSatellite_0InternalBehavior/GetEventTested, operation=Event_DTC_0X9A0201.GetEventTested
        OpEventGetEventTested_GetEventTested_EvtInfo_DTC_0X9A031E: start-on-event=DemSatellite_0InternalBehavior/GetEventTested, operation=EvtInfo_DTC_0X9A031E.GetEventTested
        OpEventGetEventTested_GetEventTested_Event_DTC_0X9A031E: start-on-event=DemSatellite_0InternalBehavior/GetEventTested, operation=Event_DTC_0X9A031E.GetEventTested
        OpEventGetEventTested_GetEventTested_EvtInfo_DTC_0XC19988: start-on-event=DemSatellite_0InternalBehavior/GetEventTested, operation=EvtInfo_DTC_0XC19988.GetEventTested
        OpEventGetEventTested_GetEventTested_Event_DTC_0XC19988: start-on-event=DemSatellite_0InternalBehavior/GetEventTested, operation=Event_DTC_0XC19988.GetEventTested
        OpEventGetDTCOfEvent_GetDTCOfEvent_EvtInfo_DTC_0X9A0313: start-on-event=DemSatellite_0InternalBehavior/GetDTCOfEvent, operation=EvtInfo_DTC_0X9A0313.GetDTCOfEvent
        OpEventGetDTCOfEvent_GetDTCOfEvent_Event_DTC_0X9A0313: start-on-event=DemSatellite_0InternalBehavior/GetDTCOfEvent, operation=Event_DTC_0X9A0313.GetDTCOfEvent
        OpEventGetDTCOfEvent_GetDTCOfEvent_EvtInfo_DTC_0X9A0312: start-on-event=DemSatellite_0InternalBehavior/GetDTCOfEvent, operation=EvtInfo_DTC_0X9A0312.GetDTCOfEvent
        OpEventGetDTCOfEvent_GetDTCOfEvent_Event_DTC_0X9A0312: start-on-event=DemSatellite_0InternalBehavior/GetDTCOfEvent, operation=Event_DTC_0X9A0312.GetDTCOfEvent
        OpEventGetDTCOfEvent_GetDTCOfEvent_EvtInfo_DTC_0X9A0311: start-on-event=DemSatellite_0InternalBehavior/GetDTCOfEvent, operation=EvtInfo_DTC_0X9A0311.GetDTCOfEvent
        OpEventGetDTCOfEvent_GetDTCOfEvent_Event_DTC_0X9A0311: start-on-event=DemSatellite_0InternalBehavior/GetDTCOfEvent, operation=Event_DTC_0X9A0311.GetDTCOfEvent
        OpEventGetDTCOfEvent_GetDTCOfEvent_EvtInfo_DTC_0X9A0425: start-on-event=DemSatellite_0InternalBehavior/GetDTCOfEvent, operation=EvtInfo_DTC_0X9A0425.GetDTCOfEvent
        OpEventGetDTCOfEvent_GetDTCOfEvent_Event_DTC_0X9A0425: start-on-event=DemSatellite_0InternalBehavior/GetDTCOfEvent, operation=Event_DTC_0X9A0425.GetDTCOfEvent
        OpEventGetDTCOfEvent_GetDTCOfEvent_EvtInfo_DTC_0X925411: start-on-event=DemSatellite_0InternalBehavior/GetDTCOfEvent, operation=EvtInfo_DTC_0X925411.GetDTCOfEvent
        OpEventGetDTCOfEvent_GetDTCOfEvent_Event_DTC_0X925411: start-on-event=DemSatellite_0InternalBehavior/GetDTCOfEvent, operation=Event_DTC_0X925411.GetDTCOfEvent
        OpEventGetDTCOfEvent_GetDTCOfEvent_EvtInfo_DTC_0X909502: start-on-event=DemSatellite_0InternalBehavior/GetDTCOfEvent, operation=EvtInfo_DTC_0X909502.GetDTCOfEvent
        OpEventGetDTCOfEvent_GetDTCOfEvent_Event_DTC_0X909502: start-on-event=DemSatellite_0InternalBehavior/GetDTCOfEvent, operation=Event_DTC_0X909502.GetDTCOfEvent
        OpEventGetDTCOfEvent_GetDTCOfEvent_EvtInfo_DTC_0X9A0301: start-on-event=DemSatellite_0InternalBehavior/GetDTCOfEvent, operation=EvtInfo_DTC_0X9A0301.GetDTCOfEvent
        OpEventGetDTCOfEvent_GetDTCOfEvent_Event_DTC_0X9A0301: start-on-event=DemSatellite_0InternalBehavior/GetDTCOfEvent, operation=Event_DTC_0X9A0301.GetDTCOfEvent
        OpEventGetDTCOfEvent_GetDTCOfEvent_EvtInfo_DTC_0X9A041E: start-on-event=DemSatellite_0InternalBehavior/GetDTCOfEvent, operation=EvtInfo_DTC_0X9A041E.GetDTCOfEvent
        OpEventGetDTCOfEvent_GetDTCOfEvent_Event_DTC_0X9A041E: start-on-event=DemSatellite_0InternalBehavior/GetDTCOfEvent, operation=Event_DTC_0X9A041E.GetDTCOfEvent
        OpEventGetDTCOfEvent_GetDTCOfEvent_EvtInfo_DTC_0XC19887: start-on-event=DemSatellite_0InternalBehavior/GetDTCOfEvent, operation=EvtInfo_DTC_0XC19887.GetDTCOfEvent
        OpEventGetDTCOfEvent_GetDTCOfEvent_Event_DTC_0XC19887: start-on-event=DemSatellite_0InternalBehavior/GetDTCOfEvent, operation=Event_DTC_0XC19887.GetDTCOfEvent
        OpEventGetDTCOfEvent_GetDTCOfEvent_EvtInfo_DTC_0X9A0413: start-on-event=DemSatellite_0InternalBehavior/GetDTCOfEvent, operation=EvtInfo_DTC_0X9A0413.GetDTCOfEvent
        OpEventGetDTCOfEvent_GetDTCOfEvent_Event_DTC_0X9A0413: start-on-event=DemSatellite_0InternalBehavior/GetDTCOfEvent, operation=Event_DTC_0X9A0413.GetDTCOfEvent
        OpEventGetDTCOfEvent_GetDTCOfEvent_EvtInfo_DTC_0X9A0412: start-on-event=DemSatellite_0InternalBehavior/GetDTCOfEvent, operation=EvtInfo_DTC_0X9A0412.GetDTCOfEvent
        OpEventGetDTCOfEvent_GetDTCOfEvent_Event_DTC_0X9A0412: start-on-event=DemSatellite_0InternalBehavior/GetDTCOfEvent, operation=Event_DTC_0X9A0412.GetDTCOfEvent
        OpEventGetDTCOfEvent_GetDTCOfEvent_EvtInfo_DTC_0XC26402: start-on-event=DemSatellite_0InternalBehavior/GetDTCOfEvent, operation=EvtInfo_DTC_0XC26402.GetDTCOfEvent
        OpEventGetDTCOfEvent_GetDTCOfEvent_Event_DTC_0XC26402: start-on-event=DemSatellite_0InternalBehavior/GetDTCOfEvent, operation=Event_DTC_0XC26402.GetDTCOfEvent
        OpEventGetDTCOfEvent_GetDTCOfEvent_EvtInfo_DTC_0X9A0411: start-on-event=DemSatellite_0InternalBehavior/GetDTCOfEvent, operation=EvtInfo_DTC_0X9A0411.GetDTCOfEvent
        OpEventGetDTCOfEvent_GetDTCOfEvent_Event_DTC_0X9A0411: start-on-event=DemSatellite_0InternalBehavior/GetDTCOfEvent, operation=Event_DTC_0X9A0411.GetDTCOfEvent
        OpEventGetDTCOfEvent_GetDTCOfEvent_EvtInfo_DTC_0X9A0401: start-on-event=DemSatellite_0InternalBehavior/GetDTCOfEvent, operation=EvtInfo_DTC_0X9A0401.GetDTCOfEvent
        OpEventGetDTCOfEvent_GetDTCOfEvent_Event_DTC_0X9A0401: start-on-event=DemSatellite_0InternalBehavior/GetDTCOfEvent, operation=Event_DTC_0X9A0401.GetDTCOfEvent
        OpEventGetDTCOfEvent_GetDTCOfEvent_EvtInfo_DTC_0X93F611: start-on-event=DemSatellite_0InternalBehavior/GetDTCOfEvent, operation=EvtInfo_DTC_0X93F611.GetDTCOfEvent
        OpEventGetDTCOfEvent_GetDTCOfEvent_Event_DTC_0X93F611: start-on-event=DemSatellite_0InternalBehavior/GetDTCOfEvent, operation=Event_DTC_0X93F611.GetDTCOfEvent
        OpEventGetDTCOfEvent_GetDTCOfEvent_EvtInfo_DTC_0X923817: start-on-event=DemSatellite_0InternalBehavior/GetDTCOfEvent, operation=EvtInfo_DTC_0X923817.GetDTCOfEvent
        OpEventGetDTCOfEvent_GetDTCOfEvent_Event_DTC_0X923817: start-on-event=DemSatellite_0InternalBehavior/GetDTCOfEvent, operation=Event_DTC_0X923817.GetDTCOfEvent
        OpEventGetDTCOfEvent_GetDTCOfEvent_EvtInfo_DTC_0X923816: start-on-event=DemSatellite_0InternalBehavior/GetDTCOfEvent, operation=EvtInfo_DTC_0X923816.GetDTCOfEvent
        OpEventGetDTCOfEvent_GetDTCOfEvent_Event_DTC_0X923816: start-on-event=DemSatellite_0InternalBehavior/GetDTCOfEvent, operation=Event_DTC_0X923816.GetDTCOfEvent
        OpEventGetDTCOfEvent_GetDTCOfEvent_EvtInfo_DTC_0X93F613: start-on-event=DemSatellite_0InternalBehavior/GetDTCOfEvent, operation=EvtInfo_DTC_0X93F613.GetDTCOfEvent
        OpEventGetDTCOfEvent_GetDTCOfEvent_Event_DTC_0X93F613: start-on-event=DemSatellite_0InternalBehavior/GetDTCOfEvent, operation=Event_DTC_0X93F613.GetDTCOfEvent
        OpEventGetDTCOfEvent_GetDTCOfEvent_EvtInfo_DTC_0X925311: start-on-event=DemSatellite_0InternalBehavior/GetDTCOfEvent, operation=EvtInfo_DTC_0X925311.GetDTCOfEvent
        OpEventGetDTCOfEvent_GetDTCOfEvent_Event_DTC_0X925311: start-on-event=DemSatellite_0InternalBehavior/GetDTCOfEvent, operation=Event_DTC_0X925311.GetDTCOfEvent
        OpEventGetDTCOfEvent_GetDTCOfEvent_EvtInfo_DTC_0X93F612: start-on-event=DemSatellite_0InternalBehavior/GetDTCOfEvent, operation=EvtInfo_DTC_0X93F612.GetDTCOfEvent
        OpEventGetDTCOfEvent_GetDTCOfEvent_Event_DTC_0X93F612: start-on-event=DemSatellite_0InternalBehavior/GetDTCOfEvent, operation=Event_DTC_0X93F612.GetDTCOfEvent
        OpEventGetDTCOfEvent_GetDTCOfEvent_EvtInfo_DTC_0X9A0125: start-on-event=DemSatellite_0InternalBehavior/GetDTCOfEvent, operation=EvtInfo_DTC_0X9A0125.GetDTCOfEvent
        OpEventGetDTCOfEvent_GetDTCOfEvent_Event_DTC_0X9A0125: start-on-event=DemSatellite_0InternalBehavior/GetDTCOfEvent, operation=Event_DTC_0X9A0125.GetDTCOfEvent
        OpEventGetDTCOfEvent_GetDTCOfEvent_EvtInfo_DTC_0XC15502: start-on-event=DemSatellite_0InternalBehavior/GetDTCOfEvent, operation=EvtInfo_DTC_0XC15502.GetDTCOfEvent
        OpEventGetDTCOfEvent_GetDTCOfEvent_Event_DTC_0XC15502: start-on-event=DemSatellite_0InternalBehavior/GetDTCOfEvent, operation=Event_DTC_0XC15502.GetDTCOfEvent
        OpEventGetDTCOfEvent_GetDTCOfEvent_EvtInfo_DTC_0X9A011E: start-on-event=DemSatellite_0InternalBehavior/GetDTCOfEvent, operation=EvtInfo_DTC_0X9A011E.GetDTCOfEvent
        OpEventGetDTCOfEvent_GetDTCOfEvent_Event_DTC_0X9A011E: start-on-event=DemSatellite_0InternalBehavior/GetDTCOfEvent, operation=Event_DTC_0X9A011E.GetDTCOfEvent
        OpEventGetDTCOfEvent_GetDTCOfEvent_EvtInfo_DTC_0XC15582: start-on-event=DemSatellite_0InternalBehavior/GetDTCOfEvent, operation=EvtInfo_DTC_0XC15582.GetDTCOfEvent
        OpEventGetDTCOfEvent_GetDTCOfEvent_Event_DTC_0XC15582: start-on-event=DemSatellite_0InternalBehavior/GetDTCOfEvent, operation=Event_DTC_0XC15582.GetDTCOfEvent
        OpEventGetDTCOfEvent_GetDTCOfEvent_EvtInfo_DTC_0XC01988: start-on-event=DemSatellite_0InternalBehavior/GetDTCOfEvent, operation=EvtInfo_DTC_0XC01988.GetDTCOfEvent
        OpEventGetDTCOfEvent_GetDTCOfEvent_Event_DTC_0XC01988: start-on-event=DemSatellite_0InternalBehavior/GetDTCOfEvent, operation=Event_DTC_0XC01988.GetDTCOfEvent
        OpEventGetDTCOfEvent_GetDTCOfEvent_EvtInfo_DTC_0X9A0112: start-on-event=DemSatellite_0InternalBehavior/GetDTCOfEvent, operation=EvtInfo_DTC_0X9A0112.GetDTCOfEvent
        OpEventGetDTCOfEvent_GetDTCOfEvent_Event_DTC_0X9A0112: start-on-event=DemSatellite_0InternalBehavior/GetDTCOfEvent, operation=Event_DTC_0X9A0112.GetDTCOfEvent
        OpEventGetDTCOfEvent_GetDTCOfEvent_EvtInfo_DTC_0X919F11: start-on-event=DemSatellite_0InternalBehavior/GetDTCOfEvent, operation=EvtInfo_DTC_0X919F11.GetDTCOfEvent
        OpEventGetDTCOfEvent_GetDTCOfEvent_Event_DTC_0X919F11: start-on-event=DemSatellite_0InternalBehavior/GetDTCOfEvent, operation=Event_DTC_0X919F11.GetDTCOfEvent
        OpEventGetDTCOfEvent_GetDTCOfEvent_EvtInfo_DTC_0X9A0111: start-on-event=DemSatellite_0InternalBehavior/GetDTCOfEvent, operation=EvtInfo_DTC_0X9A0111.GetDTCOfEvent
        OpEventGetDTCOfEvent_GetDTCOfEvent_Event_DTC_0X9A0111: start-on-event=DemSatellite_0InternalBehavior/GetDTCOfEvent, operation=Event_DTC_0X9A0111.GetDTCOfEvent
        OpEventGetDTCOfEvent_GetDTCOfEvent_EvtInfo_DTC_0X919F12: start-on-event=DemSatellite_0InternalBehavior/GetDTCOfEvent, operation=EvtInfo_DTC_0X919F12.GetDTCOfEvent
        OpEventGetDTCOfEvent_GetDTCOfEvent_Event_DTC_0X919F12: start-on-event=DemSatellite_0InternalBehavior/GetDTCOfEvent, operation=Event_DTC_0X919F12.GetDTCOfEvent
        OpEventGetDTCOfEvent_GetDTCOfEvent_EvtInfo_DTC_0X919F13: start-on-event=DemSatellite_0InternalBehavior/GetDTCOfEvent, operation=EvtInfo_DTC_0X919F13.GetDTCOfEvent
        OpEventGetDTCOfEvent_GetDTCOfEvent_Event_DTC_0X919F13: start-on-event=DemSatellite_0InternalBehavior/GetDTCOfEvent, operation=Event_DTC_0X919F13.GetDTCOfEvent
        OpEventGetDTCOfEvent_GetDTCOfEvent_EvtInfo_DTC_0X9A0113: start-on-event=DemSatellite_0InternalBehavior/GetDTCOfEvent, operation=EvtInfo_DTC_0X9A0113.GetDTCOfEvent
        OpEventGetDTCOfEvent_GetDTCOfEvent_Event_DTC_0X9A0113: start-on-event=DemSatellite_0InternalBehavior/GetDTCOfEvent, operation=Event_DTC_0X9A0113.GetDTCOfEvent
        OpEventGetDTCOfEvent_GetDTCOfEvent_EvtInfo_DTC_0XC14687: start-on-event=DemSatellite_0InternalBehavior/GetDTCOfEvent, operation=EvtInfo_DTC_0XC14687.GetDTCOfEvent
        OpEventGetDTCOfEvent_GetDTCOfEvent_Event_DTC_0XC14687: start-on-event=DemSatellite_0InternalBehavior/GetDTCOfEvent, operation=Event_DTC_0XC14687.GetDTCOfEvent
        OpEventGetDTCOfEvent_GetDTCOfEvent_EvtInfo_DTC_0X91BA63: start-on-event=DemSatellite_0InternalBehavior/GetDTCOfEvent, operation=EvtInfo_DTC_0X91BA63.GetDTCOfEvent
        OpEventGetDTCOfEvent_GetDTCOfEvent_Event_DTC_0X91BA63: start-on-event=DemSatellite_0InternalBehavior/GetDTCOfEvent, operation=Event_DTC_0X91BA63.GetDTCOfEvent
        OpEventGetDTCOfEvent_GetDTCOfEvent_EvtInfo_DTC_0X9A0225: start-on-event=DemSatellite_0InternalBehavior/GetDTCOfEvent, operation=EvtInfo_DTC_0X9A0225.GetDTCOfEvent
        OpEventGetDTCOfEvent_GetDTCOfEvent_Event_DTC_0X9A0225: start-on-event=DemSatellite_0InternalBehavior/GetDTCOfEvent, operation=Event_DTC_0X9A0225.GetDTCOfEvent
        OpEventGetDTCOfEvent_GetDTCOfEvent_EvtInfo_DTC_0XD10017: start-on-event=DemSatellite_0InternalBehavior/GetDTCOfEvent, operation=EvtInfo_DTC_0XD10017.GetDTCOfEvent
        OpEventGetDTCOfEvent_GetDTCOfEvent_Event_DTC_0XD10017: start-on-event=DemSatellite_0InternalBehavior/GetDTCOfEvent, operation=Event_DTC_0XD10017.GetDTCOfEvent
        OpEventGetDTCOfEvent_GetDTCOfEvent_EvtInfo_DTC_0X93F512: start-on-event=DemSatellite_0InternalBehavior/GetDTCOfEvent, operation=EvtInfo_DTC_0X93F512.GetDTCOfEvent
        OpEventGetDTCOfEvent_GetDTCOfEvent_Event_DTC_0X93F512: start-on-event=DemSatellite_0InternalBehavior/GetDTCOfEvent, operation=Event_DTC_0X93F512.GetDTCOfEvent
        OpEventGetDTCOfEvent_GetDTCOfEvent_EvtInfo_DTC_0X93F511: start-on-event=DemSatellite_0InternalBehavior/GetDTCOfEvent, operation=EvtInfo_DTC_0X93F511.GetDTCOfEvent
        OpEventGetDTCOfEvent_GetDTCOfEvent_Event_DTC_0X93F511: start-on-event=DemSatellite_0InternalBehavior/GetDTCOfEvent, operation=Event_DTC_0X93F511.GetDTCOfEvent
        OpEventGetDTCOfEvent_GetDTCOfEvent_EvtInfo_DTC_0X925211: start-on-event=DemSatellite_0InternalBehavior/GetDTCOfEvent, operation=EvtInfo_DTC_0X925211.GetDTCOfEvent
        OpEventGetDTCOfEvent_GetDTCOfEvent_Event_DTC_0X925211: start-on-event=DemSatellite_0InternalBehavior/GetDTCOfEvent, operation=Event_DTC_0X925211.GetDTCOfEvent
        OpEventGetDTCOfEvent_GetDTCOfEvent_EvtInfo_DTC_0X93F513: start-on-event=DemSatellite_0InternalBehavior/GetDTCOfEvent, operation=EvtInfo_DTC_0X93F513.GetDTCOfEvent
        OpEventGetDTCOfEvent_GetDTCOfEvent_Event_DTC_0X93F513: start-on-event=DemSatellite_0InternalBehavior/GetDTCOfEvent, operation=Event_DTC_0X93F513.GetDTCOfEvent
        OpEventGetDTCOfEvent_GetDTCOfEvent_EvtInfo_DTC_0X9A0101: start-on-event=DemSatellite_0InternalBehavior/GetDTCOfEvent, operation=EvtInfo_DTC_0X9A0101.GetDTCOfEvent
        OpEventGetDTCOfEvent_GetDTCOfEvent_Event_DTC_0X9A0101: start-on-event=DemSatellite_0InternalBehavior/GetDTCOfEvent, operation=Event_DTC_0X9A0101.GetDTCOfEvent
        OpEventGetDTCOfEvent_GetDTCOfEvent_EvtInfo_DTC_0X9A021E: start-on-event=DemSatellite_0InternalBehavior/GetDTCOfEvent, operation=EvtInfo_DTC_0X9A021E.GetDTCOfEvent
        OpEventGetDTCOfEvent_GetDTCOfEvent_Event_DTC_0X9A021E: start-on-event=DemSatellite_0InternalBehavior/GetDTCOfEvent, operation=Event_DTC_0X9A021E.GetDTCOfEvent
        OpEventGetDTCOfEvent_GetDTCOfEvent_EvtInfo_DTC_0XA10604: start-on-event=DemSatellite_0InternalBehavior/GetDTCOfEvent, operation=EvtInfo_DTC_0XA10604.GetDTCOfEvent
        OpEventGetDTCOfEvent_GetDTCOfEvent_Event_DTC_0XA10604: start-on-event=DemSatellite_0InternalBehavior/GetDTCOfEvent, operation=Event_DTC_0XA10604.GetDTCOfEvent
        OpEventGetDTCOfEvent_GetDTCOfEvent_EvtInfo_DTC_0XA10602: start-on-event=DemSatellite_0InternalBehavior/GetDTCOfEvent, operation=EvtInfo_DTC_0XA10602.GetDTCOfEvent
        OpEventGetDTCOfEvent_GetDTCOfEvent_Event_DTC_0XA10602: start-on-event=DemSatellite_0InternalBehavior/GetDTCOfEvent, operation=Event_DTC_0XA10602.GetDTCOfEvent
        OpEventGetDTCOfEvent_GetDTCOfEvent_EvtInfo_DTC_0X908E87: start-on-event=DemSatellite_0InternalBehavior/GetDTCOfEvent, operation=EvtInfo_DTC_0X908E87.GetDTCOfEvent
        OpEventGetDTCOfEvent_GetDTCOfEvent_Event_DTC_0X908E87: start-on-event=DemSatellite_0InternalBehavior/GetDTCOfEvent, operation=Event_DTC_0X908E87.GetDTCOfEvent
        OpEventGetDTCOfEvent_GetDTCOfEvent_EvtInfo_DTC_0X9A0211: start-on-event=DemSatellite_0InternalBehavior/GetDTCOfEvent, operation=EvtInfo_DTC_0X9A0211.GetDTCOfEvent
        OpEventGetDTCOfEvent_GetDTCOfEvent_Event_DTC_0X9A0211: start-on-event=DemSatellite_0InternalBehavior/GetDTCOfEvent, operation=Event_DTC_0X9A0211.GetDTCOfEvent
        OpEventGetDTCOfEvent_GetDTCOfEvent_EvtInfo_DTC_0X9A0213: start-on-event=DemSatellite_0InternalBehavior/GetDTCOfEvent, operation=EvtInfo_DTC_0X9A0213.GetDTCOfEvent
        OpEventGetDTCOfEvent_GetDTCOfEvent_Event_DTC_0X9A0213: start-on-event=DemSatellite_0InternalBehavior/GetDTCOfEvent, operation=Event_DTC_0X9A0213.GetDTCOfEvent
        OpEventGetDTCOfEvent_GetDTCOfEvent_EvtInfo_DTC_0X9A0212: start-on-event=DemSatellite_0InternalBehavior/GetDTCOfEvent, operation=EvtInfo_DTC_0X9A0212.GetDTCOfEvent
        OpEventGetDTCOfEvent_GetDTCOfEvent_Event_DTC_0X9A0212: start-on-event=DemSatellite_0InternalBehavior/GetDTCOfEvent, operation=Event_DTC_0X9A0212.GetDTCOfEvent
        OpEventGetDTCOfEvent_GetDTCOfEvent_EvtInfo_DTC_0XA11204: start-on-event=DemSatellite_0InternalBehavior/GetDTCOfEvent, operation=EvtInfo_DTC_0XA11204.GetDTCOfEvent
        OpEventGetDTCOfEvent_GetDTCOfEvent_Event_DTC_0XA11204: start-on-event=DemSatellite_0InternalBehavior/GetDTCOfEvent, operation=Event_DTC_0XA11204.GetDTCOfEvent
        OpEventGetDTCOfEvent_GetDTCOfEvent_EvtInfo_DTC_0X9A0325: start-on-event=DemSatellite_0InternalBehavior/GetDTCOfEvent, operation=EvtInfo_DTC_0X9A0325.GetDTCOfEvent
        OpEventGetDTCOfEvent_GetDTCOfEvent_Event_DTC_0X9A0325: start-on-event=DemSatellite_0InternalBehavior/GetDTCOfEvent, operation=Event_DTC_0X9A0325.GetDTCOfEvent
        OpEventGetDTCOfEvent_GetDTCOfEvent_EvtInfo_DTC_0XD10116: start-on-event=DemSatellite_0InternalBehavior/GetDTCOfEvent, operation=EvtInfo_DTC_0XD10116.GetDTCOfEvent
        OpEventGetDTCOfEvent_GetDTCOfEvent_Event_DTC_0XD10116: start-on-event=DemSatellite_0InternalBehavior/GetDTCOfEvent, operation=Event_DTC_0XD10116.GetDTCOfEvent
        OpEventGetDTCOfEvent_GetDTCOfEvent_EvtInfo_DTC_0X909602: start-on-event=DemSatellite_0InternalBehavior/GetDTCOfEvent, operation=EvtInfo_DTC_0X909602.GetDTCOfEvent
        OpEventGetDTCOfEvent_GetDTCOfEvent_Event_DTC_0X909602: start-on-event=DemSatellite_0InternalBehavior/GetDTCOfEvent, operation=Event_DTC_0X909602.GetDTCOfEvent
        OpEventGetDTCOfEvent_GetDTCOfEvent_EvtInfo_DTC_0X9A0201: start-on-event=DemSatellite_0InternalBehavior/GetDTCOfEvent, operation=EvtInfo_DTC_0X9A0201.GetDTCOfEvent
        OpEventGetDTCOfEvent_GetDTCOfEvent_Event_DTC_0X9A0201: start-on-event=DemSatellite_0InternalBehavior/GetDTCOfEvent, operation=Event_DTC_0X9A0201.GetDTCOfEvent
        OpEventGetDTCOfEvent_GetDTCOfEvent_EvtInfo_DTC_0X9A031E: start-on-event=DemSatellite_0InternalBehavior/GetDTCOfEvent, operation=EvtInfo_DTC_0X9A031E.GetDTCOfEvent
        OpEventGetDTCOfEvent_GetDTCOfEvent_Event_DTC_0X9A031E: start-on-event=DemSatellite_0InternalBehavior/GetDTCOfEvent, operation=Event_DTC_0X9A031E.GetDTCOfEvent
        OpEventGetDTCOfEvent_GetDTCOfEvent_EvtInfo_DTC_0XC19988: start-on-event=DemSatellite_0InternalBehavior/GetDTCOfEvent, operation=EvtInfo_DTC_0XC19988.GetDTCOfEvent
        OpEventGetDTCOfEvent_GetDTCOfEvent_Event_DTC_0XC19988: start-on-event=DemSatellite_0InternalBehavior/GetDTCOfEvent, operation=Event_DTC_0XC19988.GetDTCOfEvent
        OpEventGetFaultDetectionCounter_GetFaultDetectionCounter_EvtInfo_DTC_0X9A0313: start-on-event=DemSatellite_0InternalBehavior/GetFaultDetectionCounter, operation=EvtInfo_DTC_0X9A0313.GetFaultDetectionCounter
        OpEventGetFaultDetectionCounter_GetFaultDetectionCounter_Event_DTC_0X9A0313: start-on-event=DemSatellite_0InternalBehavior/GetFaultDetectionCounter, operation=Event_DTC_0X9A0313.GetFaultDetectionCounter
        OpEventGetFaultDetectionCounter_GetFaultDetectionCounter_EvtInfo_DTC_0X9A0312: start-on-event=DemSatellite_0InternalBehavior/GetFaultDetectionCounter, operation=EvtInfo_DTC_0X9A0312.GetFaultDetectionCounter
        OpEventGetFaultDetectionCounter_GetFaultDetectionCounter_Event_DTC_0X9A0312: start-on-event=DemSatellite_0InternalBehavior/GetFaultDetectionCounter, operation=Event_DTC_0X9A0312.GetFaultDetectionCounter
        OpEventGetFaultDetectionCounter_GetFaultDetectionCounter_EvtInfo_DTC_0X9A0311: start-on-event=DemSatellite_0InternalBehavior/GetFaultDetectionCounter, operation=EvtInfo_DTC_0X9A0311.GetFaultDetectionCounter
        OpEventGetFaultDetectionCounter_GetFaultDetectionCounter_Event_DTC_0X9A0311: start-on-event=DemSatellite_0InternalBehavior/GetFaultDetectionCounter, operation=Event_DTC_0X9A0311.GetFaultDetectionCounter
        OpEventGetFaultDetectionCounter_GetFaultDetectionCounter_EvtInfo_DTC_0X9A0425: start-on-event=DemSatellite_0InternalBehavior/GetFaultDetectionCounter, operation=EvtInfo_DTC_0X9A0425.GetFaultDetectionCounter
        OpEventGetFaultDetectionCounter_GetFaultDetectionCounter_Event_DTC_0X9A0425: start-on-event=DemSatellite_0InternalBehavior/GetFaultDetectionCounter, operation=Event_DTC_0X9A0425.GetFaultDetectionCounter
        OpEventGetFaultDetectionCounter_GetFaultDetectionCounter_EvtInfo_DTC_0X925411: start-on-event=DemSatellite_0InternalBehavior/GetFaultDetectionCounter, operation=EvtInfo_DTC_0X925411.GetFaultDetectionCounter
        OpEventGetFaultDetectionCounter_GetFaultDetectionCounter_Event_DTC_0X925411: start-on-event=DemSatellite_0InternalBehavior/GetFaultDetectionCounter, operation=Event_DTC_0X925411.GetFaultDetectionCounter
        OpEventGetFaultDetectionCounter_GetFaultDetectionCounter_EvtInfo_DTC_0X909502: start-on-event=DemSatellite_0InternalBehavior/GetFaultDetectionCounter, operation=EvtInfo_DTC_0X909502.GetFaultDetectionCounter
        OpEventGetFaultDetectionCounter_GetFaultDetectionCounter_Event_DTC_0X909502: start-on-event=DemSatellite_0InternalBehavior/GetFaultDetectionCounter, operation=Event_DTC_0X909502.GetFaultDetectionCounter
        OpEventGetFaultDetectionCounter_GetFaultDetectionCounter_EvtInfo_DTC_0X9A0301: start-on-event=DemSatellite_0InternalBehavior/GetFaultDetectionCounter, operation=EvtInfo_DTC_0X9A0301.GetFaultDetectionCounter
        OpEventGetFaultDetectionCounter_GetFaultDetectionCounter_Event_DTC_0X9A0301: start-on-event=DemSatellite_0InternalBehavior/GetFaultDetectionCounter, operation=Event_DTC_0X9A0301.GetFaultDetectionCounter
        OpEventGetFaultDetectionCounter_GetFaultDetectionCounter_EvtInfo_DTC_0X9A041E: start-on-event=DemSatellite_0InternalBehavior/GetFaultDetectionCounter, operation=EvtInfo_DTC_0X9A041E.GetFaultDetectionCounter
        OpEventGetFaultDetectionCounter_GetFaultDetectionCounter_Event_DTC_0X9A041E: start-on-event=DemSatellite_0InternalBehavior/GetFaultDetectionCounter, operation=Event_DTC_0X9A041E.GetFaultDetectionCounter
        OpEventGetFaultDetectionCounter_GetFaultDetectionCounter_EvtInfo_DTC_0XC19887: start-on-event=DemSatellite_0InternalBehavior/GetFaultDetectionCounter, operation=EvtInfo_DTC_0XC19887.GetFaultDetectionCounter
        OpEventGetFaultDetectionCounter_GetFaultDetectionCounter_Event_DTC_0XC19887: start-on-event=DemSatellite_0InternalBehavior/GetFaultDetectionCounter, operation=Event_DTC_0XC19887.GetFaultDetectionCounter
        OpEventGetFaultDetectionCounter_GetFaultDetectionCounter_EvtInfo_DTC_0X9A0413: start-on-event=DemSatellite_0InternalBehavior/GetFaultDetectionCounter, operation=EvtInfo_DTC_0X9A0413.GetFaultDetectionCounter
        OpEventGetFaultDetectionCounter_GetFaultDetectionCounter_Event_DTC_0X9A0413: start-on-event=DemSatellite_0InternalBehavior/GetFaultDetectionCounter, operation=Event_DTC_0X9A0413.GetFaultDetectionCounter
        OpEventGetFaultDetectionCounter_GetFaultDetectionCounter_EvtInfo_DTC_0X9A0412: start-on-event=DemSatellite_0InternalBehavior/GetFaultDetectionCounter, operation=EvtInfo_DTC_0X9A0412.GetFaultDetectionCounter
        OpEventGetFaultDetectionCounter_GetFaultDetectionCounter_Event_DTC_0X9A0412: start-on-event=DemSatellite_0InternalBehavior/GetFaultDetectionCounter, operation=Event_DTC_0X9A0412.GetFaultDetectionCounter
        OpEventGetFaultDetectionCounter_GetFaultDetectionCounter_EvtInfo_DTC_0XC26402: start-on-event=DemSatellite_0InternalBehavior/GetFaultDetectionCounter, operation=EvtInfo_DTC_0XC26402.GetFaultDetectionCounter
        OpEventGetFaultDetectionCounter_GetFaultDetectionCounter_Event_DTC_0XC26402: start-on-event=DemSatellite_0InternalBehavior/GetFaultDetectionCounter, operation=Event_DTC_0XC26402.GetFaultDetectionCounter
        OpEventGetFaultDetectionCounter_GetFaultDetectionCounter_EvtInfo_DTC_0X9A0411: start-on-event=DemSatellite_0InternalBehavior/GetFaultDetectionCounter, operation=EvtInfo_DTC_0X9A0411.GetFaultDetectionCounter
        OpEventGetFaultDetectionCounter_GetFaultDetectionCounter_Event_DTC_0X9A0411: start-on-event=DemSatellite_0InternalBehavior/GetFaultDetectionCounter, operation=Event_DTC_0X9A0411.GetFaultDetectionCounter
        OpEventGetFaultDetectionCounter_GetFaultDetectionCounter_EvtInfo_DTC_0X9A0401: start-on-event=DemSatellite_0InternalBehavior/GetFaultDetectionCounter, operation=EvtInfo_DTC_0X9A0401.GetFaultDetectionCounter
        OpEventGetFaultDetectionCounter_GetFaultDetectionCounter_Event_DTC_0X9A0401: start-on-event=DemSatellite_0InternalBehavior/GetFaultDetectionCounter, operation=Event_DTC_0X9A0401.GetFaultDetectionCounter
        OpEventGetFaultDetectionCounter_GetFaultDetectionCounter_EvtInfo_DTC_0X93F611: start-on-event=DemSatellite_0InternalBehavior/GetFaultDetectionCounter, operation=EvtInfo_DTC_0X93F611.GetFaultDetectionCounter
        OpEventGetFaultDetectionCounter_GetFaultDetectionCounter_Event_DTC_0X93F611: start-on-event=DemSatellite_0InternalBehavior/GetFaultDetectionCounter, operation=Event_DTC_0X93F611.GetFaultDetectionCounter
        OpEventGetFaultDetectionCounter_GetFaultDetectionCounter_EvtInfo_DTC_0X923817: start-on-event=DemSatellite_0InternalBehavior/GetFaultDetectionCounter, operation=EvtInfo_DTC_0X923817.GetFaultDetectionCounter
        OpEventGetFaultDetectionCounter_GetFaultDetectionCounter_Event_DTC_0X923817: start-on-event=DemSatellite_0InternalBehavior/GetFaultDetectionCounter, operation=Event_DTC_0X923817.GetFaultDetectionCounter
        OpEventGetFaultDetectionCounter_GetFaultDetectionCounter_EvtInfo_DTC_0X923816: start-on-event=DemSatellite_0InternalBehavior/GetFaultDetectionCounter, operation=EvtInfo_DTC_0X923816.GetFaultDetectionCounter
        OpEventGetFaultDetectionCounter_GetFaultDetectionCounter_Event_DTC_0X923816: start-on-event=DemSatellite_0InternalBehavior/GetFaultDetectionCounter, operation=Event_DTC_0X923816.GetFaultDetectionCounter
        OpEventGetFaultDetectionCounter_GetFaultDetectionCounter_EvtInfo_DTC_0X93F613: start-on-event=DemSatellite_0InternalBehavior/GetFaultDetectionCounter, operation=EvtInfo_DTC_0X93F613.GetFaultDetectionCounter
        OpEventGetFaultDetectionCounter_GetFaultDetectionCounter_Event_DTC_0X93F613: start-on-event=DemSatellite_0InternalBehavior/GetFaultDetectionCounter, operation=Event_DTC_0X93F613.GetFaultDetectionCounter
        OpEventGetFaultDetectionCounter_GetFaultDetectionCounter_EvtInfo_DTC_0X925311: start-on-event=DemSatellite_0InternalBehavior/GetFaultDetectionCounter, operation=EvtInfo_DTC_0X925311.GetFaultDetectionCounter
        OpEventGetFaultDetectionCounter_GetFaultDetectionCounter_Event_DTC_0X925311: start-on-event=DemSatellite_0InternalBehavior/GetFaultDetectionCounter, operation=Event_DTC_0X925311.GetFaultDetectionCounter
        OpEventGetFaultDetectionCounter_GetFaultDetectionCounter_EvtInfo_DTC_0X93F612: start-on-event=DemSatellite_0InternalBehavior/GetFaultDetectionCounter, operation=EvtInfo_DTC_0X93F612.GetFaultDetectionCounter
        OpEventGetFaultDetectionCounter_GetFaultDetectionCounter_Event_DTC_0X93F612: start-on-event=DemSatellite_0InternalBehavior/GetFaultDetectionCounter, operation=Event_DTC_0X93F612.GetFaultDetectionCounter
        OpEventGetFaultDetectionCounter_GetFaultDetectionCounter_EvtInfo_DTC_0X9A0125: start-on-event=DemSatellite_0InternalBehavior/GetFaultDetectionCounter, operation=EvtInfo_DTC_0X9A0125.GetFaultDetectionCounter
